VERSION ""

NS_ :

BS_:

BU_: Dummy_PHS EBOOST_OBD_PHS EOCM2cp_IMX6_PHS EOCM2cp_K1_PHS EPSb_PHS EBCM_PHS EPSa_PHS CMMb_PHS CGM3a_PHS CMMa_PHS ADIMb_PHS

BO_ 603 USDT_Req_to_CMM_PHS: 8 CGM3a_PHS
 SG_ DgnInf : 7|64@0+ (1,0) [0|1.84467440737096E+019] ""  CMMa_PHS

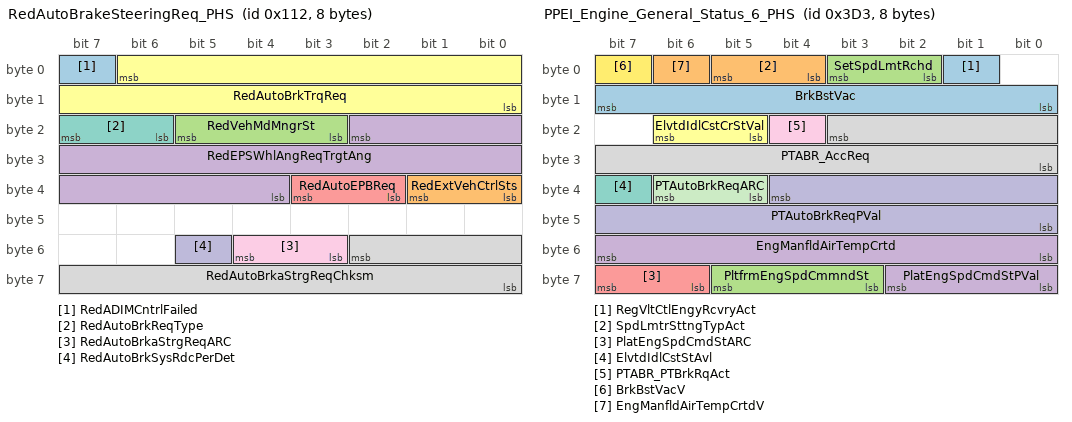
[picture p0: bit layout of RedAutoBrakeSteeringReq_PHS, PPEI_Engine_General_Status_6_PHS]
BO_ 274 RedAutoBrakeSteeringReq_PHS: 8 ADIMb_PHS
 SG_ RedADIMCntrlFailed : 7|1@0+ (1,0) [0|1] ""  EOCM2cp_K1_PHS,EPSb_PHS,EPSa_PHS,EBOOST_OBD_PHS,EBCM_PHS
 SG_ RedExtVehCtrlSts : 33|2@0+ (1,0) [0|2] ""  EBOOST_OBD_PHS,EBCM_PHS
 SG_ RedVehMdMngrSt : 21|3@0+ (1,0) [0|7] ""  EOCM2cp_K1_PHS,EPSb_PHS,EBOOST_OBD_PHS,EBCM_PHS,EPSa_PHS
 SG_ RedEPSWhlAngReqTrgtAng : 18|15@0- (0.0625,0) [-1024|1023.9375] "Deg"  EPSa_PHS,EPSb_PHS,EBOOST_OBD_PHS,EBCM_PHS
 SG_ RedAutoEPBReq : 35|2@0+ (1,0) [0|3] ""  EPSa_PHS,EPSb_PHS,EBOOST_OBD_PHS,EBCM_PHS
 SG_ RedAutoBrkTrqReq : 6|15@0+ (2,-65534) [-65534|0] "Nm"  EPSa_PHS,EPSb_PHS,EBOOST_OBD_PHS,EBCM_PHS
 SG_ RedAutoBrkReqType : 23|2@0+ (1,0) [0|3] ""  EPSa_PHS,EPSb_PHS,EBOOST_OBD_PHS,EBCM_PHS
 SG_ RedAutoBrkaStrgReqChksm : 50|11@0+ (1,0) [0|2047] ""  EPSa_PHS,EPSb_PHS,EBOOST_OBD_PHS,EBCM_PHS
 SG_ RedAutoBrkaStrgReqARC : 52|2@0+ (1,0) [0|3] ""  EPSa_PHS,EPSb_PHS,EBOOST_OBD_PHS,EBCM_PHS
 SG_ RedAutoBrkSysRdcPerDet : 53|1@0+ (1,0) [0|1] ""  EBCM_PHS,EBOOST_OBD_PHS

BO_ 598 USDT_Req_to_CMMb_PHS: 8 CGM3a_PHS
 SG_ DgnInf : 7|64@0+ (1,0) [0|1.84467440737096E+019] ""  CMMb_PHS

BO_ 1608 USDT_Resp_From_EPSb_PHS: 8 EPSb_PHS
 SG_ DgnInf : 7|64@0+ (1,0) [0|1.84467440737096E+019] ""  CGM3a_PHS

BO_ 1931 DTC_Triggered_78B_PHS: 7 EPSb_PHS
 SG_ DTCI_CodeSupported_78B : 40|1@0+ (1,0) [0|1] ""  CGM3a_PHS
 SG_ DTCI_CurrentStatus_78B : 41|1@0+ (1,0) [0|1] ""  CGM3a_PHS
 SG_ DTCI_DTCFailType_78B : 39|8@0+ (1,0) [0|255] ""  CGM3a_PHS
 SG_ DTCI_DTCFaultType_78B : 55|8@0+ (1,0) [0|255] ""  CGM3a_PHS
 SG_ DTCI_DTCNumber_78B : 23|16@0+ (1,0) [0|65535] ""  CGM3a_PHS
 SG_ DTCI_DTCSource_78B : 15|8@0+ (1,0) [0|255] ""  CGM3a_PHS
 SG_ DTCI_DTCTriggered_78B : 0|1@0+ (1,0) [0|1] ""  CGM3a_PHS
 SG_ DTCI_HistStat_78B : 44|1@0+ (1,0) [0|1] ""  CGM3a_PHS
 SG_ DTCI_TstFldCdClrdStat_78B : 43|1@0+ (1,0) [0|1] ""  CGM3a_PHS
 SG_ DTCI_TstFldPwrUpSt_78B : 46|1@0+ (1,0) [0|1] ""  CGM3a_PHS
 SG_ DTCI_TstNPsdCdClrdSt_78B : 42|1@0+ (1,0) [0|1] ""  CGM3a_PHS
 SG_ DTCI_TstNPsdPwrUpSt_78B : 45|1@0+ (1,0) [0|1] ""  CGM3a_PHS
 SG_ DTCIUnused1_78B : 7|1@0+ (1,0) [0|1] ""  CGM3a_PHS
 SG_ DTCIUnused2_78B : 6|1@0+ (1,0) [0|1] ""  CGM3a_PHS
 SG_ DTCIUnused3_78B : 5|1@0+ (1,0) [0|1] ""  CGM3a_PHS
 SG_ DTCIUnused4_78B : 4|1@0+ (1,0) [0|1] ""  CGM3a_PHS
 SG_ DTCIUnused5_78B : 3|1@0+ (1,0) [0|1] ""  CGM3a_PHS
 SG_ DTCIUnused6_78B : 2|1@0+ (1,0) [0|1] ""  CGM3a_PHS
 SG_ DTCIUnused7_78B : 1|1@0+ (1,0) [0|1] ""  CGM3a_PHS
 SG_ DTCI_WrnIndRqdSt_78B : 47|1@0+ (1,0) [0|1] ""  CGM3a_PHS

BO_ 1364 UUDT_Resp_From_EBoost_PHS: 8 EBOOST_OBD_PHS
 SG_ DgnInf_HS554 : 7|64@0+ (1,0) [0|1.84467440737096E+019] ""  CGM3a_PHS

BO_ 1359 UUDT_Resp_From_ADIMb_PHS: 8 ADIMb_PHS
 SG_ DgnInf_HS54F : 7|64@0+ (1,0) [0|1.84467440737096E+019] ""  CGM3a_PHS

BO_ 1352 UUDT_Resp_From_EPSb_PHS: 8 EPSb_PHS
 SG_ DgnInf_HS548 : 7|64@0+ (1,0) [0|1.84467440737096E+019] ""  CGM3a_PHS

BO_ 1300 VIN_Digits_2_to_9_PHS: 8 CGM3a_PHS
 SG_ VehIdNmDig2_9 : 7|64@0+ (1,0) [0|1] ""  EBCM_PHS,EBOOST_OBD_PHS,EOCM2cp_IMX6_PHS,EPSa_PHS,EOCM2cp_K1_PHS

BO_ 979 PPEI_Engine_General_Status_6_PHS: 8 CGM3a_PHS
 SG_ RegVltCtlEngyRcvryAct : 1|1@0+ (1,0) [0|1] "" Vector__XXX
 SG_ SpdLmtrSttngTypAct : 5|2@0+ (1,0) [0|3] "" Vector__XXX
 SG_ SetSpdLmtRchd : 3|2@0+ (1,0) [0|3] "" Vector__XXX
 SG_ PlatEngSpdCmdStPVal : 58|3@0+ (1,0) [0|7] "" Vector__XXX
 SG_ PlatEngSpdCmdStARC : 63|2@0+ (1,0) [0|3] "" Vector__XXX
 SG_ ElvtdIdlCstCrStVal : 22|2@0+ (1,0) [0|3] "" Vector__XXX
 SG_ ElvtdIdlCstStAvl : 39|1@0+ (1,0) [0|1] "" Vector__XXX
 SG_ PTABR_AccReq : 19|12@0- (0.01,0) [-20.48|20.47] "m/s^2"  EBCM_PHS
 SG_ PTABR_PTBrkRqAct : 20|1@0+ (1,0) [0|1] ""  EBCM_PHS
 SG_ PTAutoBrkReqPVal : 36|13@0+ (1,0) [0|8191] ""  EBCM_PHS
 SG_ PTAutoBrkReqARC : 38|2@0+ (1,0) [0|3] ""  EBCM_PHS
 SG_ BrkBstVacV : 7|1@0+ (1,0) [0|1] ""  EBCM_PHS
 SG_ BrkBstVac : 15|8@0+ (0.5,0) [0|127.5] "kPa"  EBCM_PHS
 SG_ EngManfldAirTempCrtdV : 6|1@0+ (1,0) [0|1] "" Vector__XXX
 SG_ PltfrmEngSpdCmmndSt : 61|3@0+ (1,0) [0|7] "" Vector__XXX
 SG_ EngManfldAirTempCrtd : 55|8@0+ (1,-40) [-40|215] "deg C" Vector__XXX

BO_ 1249 PPEI_VIN_Digits_10_to_17_PHS: 8 CGM3a_PHS
 SG_ VehIdNmDig10_17 : 7|64@0+ (1,0) [0|1] ""  EPSa_PHS,EBCM_PHS,EOCM2cp_K1_PHS

BO_ 1615 USDT_Resp_From_ADIMb_PHS: 8 ADIMb_PHS
 SG_ DgnInf : 7|64@0+ (1,0) [0|1.84467440737096E+019] ""  CGM3a_PHS

BO_ 562 Driving_Mode_Control_PHS: 8 EBCM_PHS
 SG_ BrkSysAutBrkStat : 52|2@0+ (1,0) [0|3] ""  Dummy_PHS
 SG_ FSRACCBrkngReqDenied : 46|1@0+ (1,0) [0|1] ""  Dummy_PHS
 SG_ BrkSysExtHldCpbltyFld : 47|1@0+ (1,0) [0|1] ""  Dummy_PHS
 SG_ SndPerfMdCsStAvl : 63|1@0+ (1,0) [0|1] ""  Dummy_PHS
 SG_ SndPerfMdCsCrStVal : 62|3@0+ (1,0) [0|7] ""  Dummy_PHS
 SG_ DispPerfMdCsStAvl : 59|1@0+ (1,0) [0|1] ""  Dummy_PHS
 SG_ DispPerfMdCsCrStVal : 58|3@0+ (1,0) [0|7] ""  Dummy_PHS
 SG_ DrvlneMntsPerfMdRq : 50|3@0+ (1,0) [0|7] ""  Dummy_PHS
 SG_ RideCntrlPerfMdRq : 18|3@0+ (1,0) [0|7] ""  Dummy_PHS
 SG_ StgSysPerfMdRq : 29|3@0+ (1,0) [0|7] ""  Dummy_PHS
 SG_ DiffPerfMdRq : 26|3@0+ (1,0) [0|7] ""  Dummy_PHS
 SG_ SndEnhcmtPerfMdRq : 13|3@0+ (1,0) [0|7] ""  Dummy_PHS
 SG_ DsplyPerfMdRq : 10|3@0+ (1,0) [0|7] ""  Dummy_PHS
 SG_ ExhstPerfMdRq : 5|3@0+ (1,0) [0|7] ""  Dummy_PHS
 SG_ HillDscntCntlSysStat : 55|3@0+ (1,0) [0|7] ""  Dummy_PHS
 SG_ SusCustStngAvlbl : 23|1@0+ (1,0) [0|1] ""  Dummy_PHS
 SG_ SusCustCurrStngVal : 45|3@0+ (1,0) [0|7] ""  Dummy_PHS
 SG_ StrCustStngAvlbl : 7|1@0+ (1,0) [0|1] ""  Dummy_PHS
 SG_ StrCustCurrStngVal : 42|3@0+ (1,0) [0|7] ""  Dummy_PHS
 SG_ DrvlnCustStngAvlbl : 6|1@0+ (1,0) [0|1] ""  Dummy_PHS
 SG_ DrvMdCntrlState : 39|8@0+ (1,0) [0|255] ""  Dummy_PHS
 SG_ AWDPerfMdRq : 2|3@0+ (1,0) [0|7] ""  Dummy_PHS
 SG_ DrvlnCustCurrStngVal : 22|3@0+ (1,0) [0|7] ""  Dummy_PHS

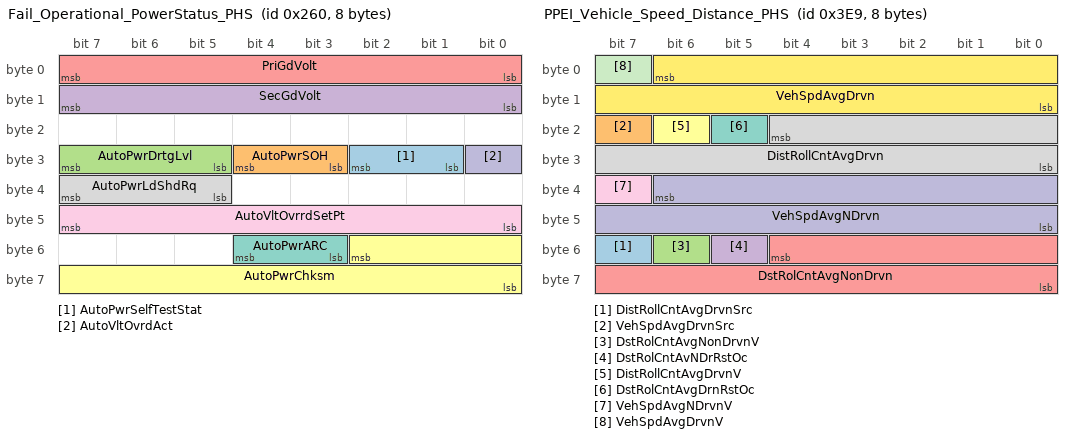
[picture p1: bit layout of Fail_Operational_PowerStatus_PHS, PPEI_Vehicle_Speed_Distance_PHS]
BO_ 608 Fail_Operational_PowerStatus_PHS: 8 CGM3a_PHS
 SG_ AutoPwrSelfTestStat : 26|2@0+ (1,0) [0|3] "" Vector__XXX
 SG_ AutoPwrSOH : 28|2@0+ (1,0) [0|3] "" Vector__XXX
 SG_ AutoPwrDrtgLvl : 31|3@0+ (1,0) [0|7] "" Vector__XXX
 SG_ SecGdVolt : 15|8@0+ (0.1,0) [0|25.5] "Volts" Vector__XXX
 SG_ PriGdVolt : 7|8@0+ (0.1,0) [0|25.5] "Volts" Vector__XXX
 SG_ AutoPwrChksm : 50|11@0+ (1,0) [0|2047] ""  EBOOST_OBD_PHS,EPSb_PHS,EBCM_PHS,EPSa_PHS
 SG_ AutoPwrARC : 52|2@0+ (1,0) [0|3] ""  EBOOST_OBD_PHS,EPSb_PHS,EBCM_PHS,EPSa_PHS
 SG_ AutoPwrLdShdRq : 39|3@0+ (1,0) [0|7] ""  EBOOST_OBD_PHS,EPSb_PHS,EBCM_PHS,EPSa_PHS
 SG_ AutoVltOvrrdSetPt : 47|8@0+ (0.1,0) [0|25.5] "V" Vector__XXX
 SG_ AutoVltOvrdAct : 24|1@0+ (1,0) [0|1] "" Vector__XXX

BO_ 1001 PPEI_Vehicle_Speed_Distance_PHS: 8 CGM3a_PHS
 SG_ DistRollCntAvgDrvnSrc : 55|1@0+ (1,0) [0|1] ""  EBOOST_OBD_PHS,EOCM2cp_IMX6_PHS,EPSb_PHS,EBCM_PHS,EPSa_PHS
 SG_ VehSpdAvgDrvnSrc : 23|1@0+ (1,0) [0|1] ""  EBOOST_OBD_PHS,EOCM2cp_IMX6_PHS,EPSa_PHS,EPSb_PHS,EBCM_PHS
 SG_ DstRolCntAvgNonDrvnV : 54|1@0+ (1,0) [0|1] ""  EBOOST_OBD_PHS,EOCM2cp_IMX6_PHS,EPSb_PHS,EPSa_PHS,EBCM_PHS
 SG_ DstRolCntAvNDrRstOc : 53|1@0+ (1,0) [0|1] ""  EBOOST_OBD_PHS,EOCM2cp_IMX6_PHS,EPSb_PHS,EPSa_PHS,EBCM_PHS
 SG_ DstRolCntAvgNonDrvn : 52|13@0+ (0.125,0) [0|1023.875] "m"  EBOOST_OBD_PHS,EOCM2cp_IMX6_PHS,EPSb_PHS,EBCM_PHS,EPSa_PHS
 SG_ DistRollCntAvgDrvnV : 22|1@0+ (1,0) [0|1] ""  EBOOST_OBD_PHS,EOCM2cp_IMX6_PHS,EPSb_PHS,EBCM_PHS,EPSa_PHS
 SG_ DstRolCntAvgDrnRstOc : 21|1@0+ (1,0) [0|1] ""  EBOOST_OBD_PHS,EOCM2cp_IMX6_PHS,EPSb_PHS,EBCM_PHS,EPSa_PHS
 SG_ DistRollCntAvgDrvn : 20|13@0+ (0.125,0) [0|1023.875] "m"  EBOOST_OBD_PHS,EOCM2cp_IMX6_PHS,EPSb_PHS,EBCM_PHS,EPSa_PHS
 SG_ VehSpdAvgNDrvnV : 39|1@0+ (1,0) [0|1] ""  CMMb_PHS,CMMa_PHS,EBOOST_OBD_PHS,EPSa_PHS,EOCM2cp_IMX6_PHS,EPSb_PHS,EBCM_PHS
 SG_ VehSpdAvgNDrvn : 38|15@0+ (0.015625,0) [0|511.984375] "km / h"  CMMb_PHS,CMMa_PHS,EBOOST_OBD_PHS,EPSa_PHS,EOCM2cp_IMX6_PHS,EPSb_PHS,EBCM_PHS
 SG_ VehSpdAvgDrvnV : 7|1@0+ (1,0) [0|1] ""  EBOOST_OBD_PHS,EPSa_PHS,EOCM2cp_IMX6_PHS,EPSb_PHS,EOCM2cp_K1_PHS,EBCM_PHS
 SG_ VehSpdAvgDrvn : 6|15@0+ (0.015625,0) [0|511.984375] "km / h"  EBOOST_OBD_PHS,EOCM2cp_IMX6_PHS,EOCM2cp_K1_PHS,EPSa_PHS,EPSb_PHS,EBCM_PHS

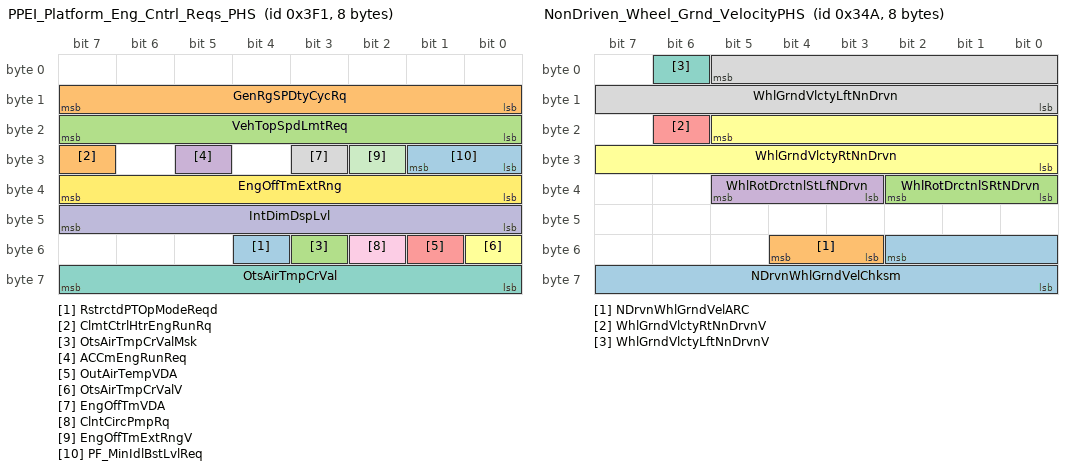
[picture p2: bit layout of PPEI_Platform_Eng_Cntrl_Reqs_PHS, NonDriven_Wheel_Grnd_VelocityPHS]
BO_ 1009 PPEI_Platform_Eng_Cntrl_Reqs_PHS: 8 CGM3a_PHS
 SG_ RstrctdPTOpModeReqd : 52|1@0+ (1,0) [0|1] "" Vector__XXX
 SG_ ClmtCtrlHtrEngRunRq : 31|1@0+ (1,0) [0|1] "" Vector__XXX
 SG_ OtsAirTmpCrValMsk : 51|1@0+ (1,0) [0|1] ""  EPSb_PHS,EPSa_PHS
 SG_ ACCmEngRunReq : 29|1@0+ (1,0) [0|1] "" Vector__XXX
 SG_ OutAirTempVDA : 49|1@0+ (1,0) [0|1] "" Vector__XXX
 SG_ OtsAirTmpCrValV : 48|1@0+ (1,0) [0|1] ""  EBCM_PHS,EPSb_PHS,EPSa_PHS
 SG_ OtsAirTmpCrVal : 63|8@0+ (0.5,-40) [-40|87.5] "deg C"  EPSb_PHS,EPSa_PHS,EBCM_PHS
 SG_ EngOffTmVDA : 27|1@0+ (1,0) [0|1] ""  EPSa_PHS,EPSb_PHS
 SG_ ClntCircPmpRq : 50|1@0+ (1,0) [0|1] "" Vector__XXX
 SG_ IntDimDspLvl : 47|8@0+ (0.392157,0) [0|100.000035] "%" Vector__XXX
 SG_ EngOffTmExtRngV : 26|1@0+ (1,0) [0|1] ""  EBCM_PHS,EPSa_PHS,EPSb_PHS
 SG_ EngOffTmExtRng : 39|8@0+ (4,0) [0|1020] "min"  EBCM_PHS,EPSa_PHS,EPSb_PHS
 SG_ PF_MinIdlBstLvlReq : 25|2@0+ (1,0) [0|3] "" Vector__XXX
 SG_ GenRgSPDtyCycRq : 15|8@0+ (0.392157,0) [0|100.000035] "%" Vector__XXX
 SG_ VehTopSpdLmtReq : 23|8@0+ (2,0) [0|510] "km / h" Vector__XXX

BO_ 201 PPEI_Engine_General_Status_1_PHS: 8 CGM3a_PHS
 SG_ Eng12vStrtrMtrCmmdOn : 53|1@0+ (1,0) [0|1] ""  EOCM2cp_K1_PHS,EOCM2cp_IMX6_PHS,EBCM_PHS,EPSb_PHS,EPSa_PHS
 SG_ EngCntrlRunCrnkTrmSt : 52|1@0+ (1,0) [0|1] ""  EOCM2cp_K1_PHS,EBOOST_OBD_PHS,EBCM_PHS,EOCM2cp_IMX6_PHS
 SG_ EngAirIntBstPrV : 51|1@0+ (1,0) [0|1] ""  EOCM2cp_K1_PHS,EBCM_PHS
 SG_ EngAirIntBstPr : 63|8@0- (1,0) [-128|127] "kPaG"  EOCM2cp_K1_PHS,EBCM_PHS
 SG_ SpdLmtrSpdWrngEnbld : 47|1@0+ (1,0) [0|1] ""  EOCM2cp_K1_PHS,EBCM_PHS
 SG_ EngCylDactEvntPndg : 54|1@0+ (1,0) [0|1] ""  EOCM2cp_K1_PHS,EBCM_PHS
 SG_ EngCylDeactMd : 43|2@0+ (1,0) [0|3] ""  EOCM2cp_K1_PHS,EBCM_PHS
 SG_ RmVhStrtEngRng : 55|1@0+ (1,0) [0|1] ""  EOCM2cp_K1_PHS,EBCM_PHS
 SG_ PFEngSpdCmndSpcd : 45|1@0+ (1,0) [0|1] ""  EOCM2cp_K1_PHS,EBCM_PHS
 SG_ DrThrtlOvrrdDetProtVal : 25|2@0+ (1,0) [0|3] ""  EOCM2cp_K1_PHS,EBCM_PHS
 SG_ DrThrtlOvrdDetAlvRlCnt : 27|2@0+ (1,0) [0|3] ""  EOCM2cp_K1_PHS,EBCM_PHS
 SG_ PltfrmEngSpdCmdInhtRq : 44|1@0+ (1,0) [0|1] ""  EOCM2cp_K1_PHS,EBCM_PHS
 SG_ PT_BrkPedDscrtInpStatV : 41|1@0+ (1,0) [0|1] ""  EOCM2cp_K1_PHS,EBCM_PHS
 SG_ PT_BrkPedDscrtInpStat : 40|1@0+ (1,0) [0|1] ""  EOCM2cp_K1_PHS,EBCM_PHS
 SG_ AccActPos : 39|8@0+ (0.392157,0) [0|100.000035] "%"  EOCM2cp_K1_PHS,EBCM_PHS
 SG_ CrsCntEnbld : 29|1@0+ (1,0) [0|1] ""  EOCM2cp_K1_PHS,EBCM_PHS
 SG_ CrsCntAtv : 30|1@0+ (1,0) [0|1] ""  EOCM2cp_K1_PHS,EBCM_PHS
 SG_ DrvThrottlOvrrdDet : 28|1@0+ (1,0) [0|1] ""  EOCM2cp_K1_PHS,EBCM_PHS
 SG_ PT_CrnkAct : 6|1@0+ (1,0) [0|1] ""  EOCM2cp_K1_PHS,EBCM_PHS,EPSb_PHS,EPSa_PHS
 SG_ PTRunAbrt : 4|1@0+ (1,0) [0|1] ""  EOCM2cp_K1_PHS,EBCM_PHS
 SG_ PTO_PT_RunAbrtd : 3|1@0+ (1,0) [0|1] ""  EOCM2cp_K1_PHS,EBCM_PHS
 SG_ PTCrnkAbrted : 5|1@0+ (1,0) [0|1] ""  EOCM2cp_K1_PHS,EBCM_PHS
 SG_ EngSpdStat : 1|2@0+ (1,0) [0|3] ""  EOCM2cp_K1_PHS,EBCM_PHS,EPSb_PHS,EPSa_PHS
 SG_ EngSpd : 15|16@0+ (0.25,0) [0|16383.75] "rpm"  EOCM2cp_K1_PHS,EBCM_PHS,EPSb_PHS,EPSa_PHS
 SG_ EngRunAtv : 7|1@0+ (1,0) [0|1] ""  EOCM2cp_K1_PHS,EBCM_PHS,EOCM2cp_IMX6_PHS,EPSb_PHS,EPSa_PHS
 SG_ EngIdlAtv : 2|1@0+ (1,0) [0|1] ""  EOCM2cp_K1_PHS,EBCM_PHS
 SG_ AccActPosV : 31|1@0+ (1,0) [0|1] ""  EOCM2cp_K1_PHS,EBCM_PHS

BO_ 842 NonDriven_Wheel_Grnd_VelocityPHS: 8 EBCM_PHS
 SG_ NDrvnWhlGrndVelChksm : 50|11@0+ (1,0) [0|2047] ""  ADIMb_PHS,EPSb_PHS,EPSa_PHS,CGM3a_PHS,EBOOST_OBD_PHS
 SG_ NDrvnWhlGrndVelARC : 52|2@0+ (1,0) [0|3] ""  ADIMb_PHS,EPSb_PHS,EPSa_PHS,CGM3a_PHS,EBOOST_OBD_PHS
 SG_ WhlRotDrctnlSRtNDrvn : 34|3@0+ (1,0) [0|7] ""  ADIMb_PHS,EBOOST_OBD_PHS,CGM3a_PHS,EPSb_PHS,EPSa_PHS
 SG_ WhlRotDrctnlStLfNDrvn : 37|3@0+ (1,0) [0|7] ""  ADIMb_PHS,EBOOST_OBD_PHS,CGM3a_PHS,EPSb_PHS,EPSa_PHS
 SG_ WhlGrndVlctyRtNnDrvnV : 22|1@0+ (1,0) [0|1] ""  ADIMb_PHS,EBOOST_OBD_PHS,EPSa_PHS,CGM3a_PHS,EPSb_PHS
 SG_ WhlGrndVlctyRtNnDrvn : 21|14@0+ (0.03125,0) [0|511.96875] "km / h"  ADIMb_PHS,EBOOST_OBD_PHS,EPSa_PHS,CGM3a_PHS,EPSb_PHS
 SG_ WhlGrndVlctyLftNnDrvnV : 6|1@0+ (1,0) [0|1] ""  ADIMb_PHS,EBOOST_OBD_PHS,EPSa_PHS,CGM3a_PHS,EPSb_PHS
 SG_ WhlGrndVlctyLftNnDrvn : 5|14@0+ (0.03125,0) [0|511.96875] "km / h"  ADIMb_PHS,EBOOST_OBD_PHS,EPSa_PHS,CGM3a_PHS,EPSb_PHS

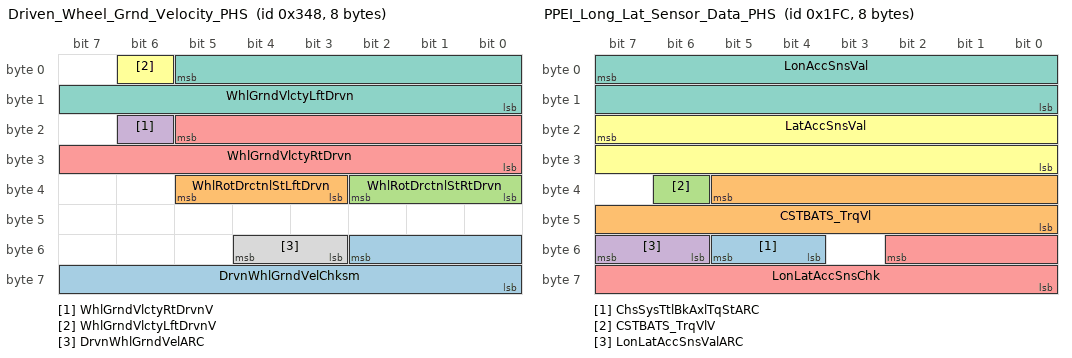
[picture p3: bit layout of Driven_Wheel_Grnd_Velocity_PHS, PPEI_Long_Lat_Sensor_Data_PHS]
BO_ 840 Driven_Wheel_Grnd_Velocity_PHS: 8 EBCM_PHS
 SG_ DrvnWhlGrndVelChksm : 50|11@0+ (1,0) [0|2047] ""  ADIMb_PHS,EPSb_PHS,EPSa_PHS,CGM3a_PHS,EBOOST_OBD_PHS
 SG_ WhlRotDrctnlStLftDrvn : 37|3@0+ (1,0) [0|7] ""  ADIMb_PHS,EBOOST_OBD_PHS,CGM3a_PHS,EPSb_PHS,EPSa_PHS
 SG_ WhlRotDrctnlStRtDrvn : 34|3@0+ (1,0) [0|7] ""  ADIMb_PHS,EBOOST_OBD_PHS,CGM3a_PHS,EPSb_PHS,EPSa_PHS
 SG_ WhlGrndVlctyRtDrvnV : 22|1@0+ (1,0) [0|1] ""  ADIMb_PHS,EBOOST_OBD_PHS,EPSa_PHS,CGM3a_PHS,EPSb_PHS
 SG_ WhlGrndVlctyRtDrvn : 21|14@0+ (0.03125,0) [0|511.96875] "km / h"  ADIMb_PHS,EBOOST_OBD_PHS,EPSa_PHS,CGM3a_PHS,EPSb_PHS
 SG_ WhlGrndVlctyLftDrvnV : 6|1@0+ (1,0) [0|1] ""  ADIMb_PHS,EBOOST_OBD_PHS,EPSa_PHS,CGM3a_PHS,EPSb_PHS
 SG_ WhlGrndVlctyLftDrvn : 5|14@0+ (0.03125,0) [0|511.96875] "km / h"  ADIMb_PHS,EBOOST_OBD_PHS,EPSa_PHS,CGM3a_PHS,EPSb_PHS
 SG_ DrvnWhlGrndVelARC : 52|2@0+ (1,0) [0|3] ""  ADIMb_PHS,EPSb_PHS,EPSa_PHS,CGM3a_PHS,EBOOST_OBD_PHS

BO_ 1912 DTC_Triggered_778_PHS: 7 EPSa_PHS
 SG_ DTCI_DTCFaultType_778 : 55|8@0+ (1,0) [0|255] ""  CGM3a_PHS
 SG_ DTCI_CodeSupported_778 : 40|1@0+ (1,0) [0|1] ""  CGM3a_PHS
 SG_ DTCI_CurrentStatus_778 : 41|1@0+ (1,0) [0|1] ""  CGM3a_PHS
 SG_ DTCI_TstNPsdCdClrdSt_778 : 42|1@0+ (1,0) [0|1] ""  CGM3a_PHS
 SG_ DTCI_TstFldCdClrdStat_778 : 43|1@0+ (1,0) [0|1] ""  CGM3a_PHS
 SG_ DTCI_HistStat_778 : 44|1@0+ (1,0) [0|1] ""  CGM3a_PHS
 SG_ DTCI_TstNPsdPwrUpSt_778 : 45|1@0+ (1,0) [0|1] ""  CGM3a_PHS
 SG_ DTCI_TstFldPwrUpSt_778 : 46|1@0+ (1,0) [0|1] ""  CGM3a_PHS
 SG_ DTCI_WrnIndRqdSt_778 : 47|1@0+ (1,0) [0|1] ""  CGM3a_PHS
 SG_ DTCI_DTCFailType_778 : 39|8@0+ (1,0) [0|255] ""  CGM3a_PHS
 SG_ DTCI_DTCNumber_778 : 23|16@0+ (1,0) [0|65535] ""  CGM3a_PHS
 SG_ DTCI_DTCSource_778 : 15|8@0+ (1,0) [0|255] ""  CGM3a_PHS
 SG_ DTCI_DTCTriggered_778 : 0|1@0+ (1,0) [0|1] ""  CGM3a_PHS
 SG_ DTCIUnused7_778 : 1|1@0+ (1,0) [0|1] ""  CGM3a_PHS
 SG_ DTCIUnused6_778 : 2|1@0+ (1,0) [0|1] ""  CGM3a_PHS
 SG_ DTCIUnused5_778 : 3|1@0+ (1,0) [0|1] ""  CGM3a_PHS
 SG_ DTCIUnused4_778 : 4|1@0+ (1,0) [0|1] ""  CGM3a_PHS
 SG_ DTCIUnused3_778 : 5|1@0+ (1,0) [0|1] ""  CGM3a_PHS
 SG_ DTCIUnused2_778 : 6|1@0+ (1,0) [0|1] ""  CGM3a_PHS
 SG_ DTCIUnused1_778 : 7|1@0+ (1,0) [0|1] ""  CGM3a_PHS

BO_ 591 USDT_Req_to_ADIMb_PHS: 8 CGM3a_PHS
 SG_ DgnInf : 7|64@0+ (1,0) [0|1.84467440737096E+019] ""  ADIMb_PHS

BO_ 1371 UUDT_Resp_From_CMM_PHS: 8 CMMa_PHS
 SG_ DgnInf_HS55B : 7|64@0+ (1,0) [0|1.84467440737096E+019] ""  CGM3a_PHS

BO_ 497 PPEI_Platform_General_Status_PHS: 8 CGM3a_PHS
 SG_ ElvtdIdlCstStReq : 33|2@0+ (1,0) [0|3] ""  EOCM2cp_K1_PHS
 SG_ FuelFltLfRstRqd : 56|1@0+ (1,0) [0|1] ""  EOCM2cp_K1_PHS
 SG_ ACCompSysVDA : 9|1@0+ (1,0) [0|1] ""  EOCM2cp_K1_PHS
 SG_ BkupPwrModeMstrVDA : 7|1@0+ (1,0) [0|1] ""  EOCM2cp_K1_PHS,EOCM2cp_IMX6_PHS,EBCM_PHS
 SG_ PrkBrkVDA : 35|1@0+ (1,0) [0|1] ""  EOCM2cp_K1_PHS
 SG_ PrkBrkVDM : 62|1@0+ (1,0) [0|1] ""  EOCM2cp_K1_PHS
 SG_ BkupPwrModeMstrVDM : 61|1@0+ (1,0) [0|1] ""  EOCM2cp_K1_PHS
 SG_ ACCompSysVDM : 60|1@0+ (1,0) [0|1] ""  EOCM2cp_K1_PHS
 SG_ AirbgVDA : 57|1@0+ (1,0) [0|1] ""  EOCM2cp_K1_PHS
 SG_ SysBkupPwrMdEn : 6|1@0+ (1,0) [0|1] ""  EBOOST_OBD_PHS,EOCM2cp_K1_PHS,EPSb_PHS,EPSa_PHS,EBCM_PHS,EOCM2cp_IMX6_PHS
 SG_ SysBkUpPwrMd : 5|2@0+ (1,0) [0|3] ""  EBOOST_OBD_PHS,EOCM2cp_K1_PHS,EPSb_PHS,EPSa_PHS,EBCM_PHS,EOCM2cp_IMX6_PHS
 SG_ SysPwrMd : 1|2@0+ (1,0) [0|3] ""  EBOOST_OBD_PHS,EOCM2cp_K1_PHS,EPSb_PHS,EPSa_PHS,EBCM_PHS,EOCM2cp_IMX6_PHS
 SG_ TrStLgMdAtv : 34|1@0+ (1,0) [0|1] ""  EOCM2cp_IMX6_PHS,EBOOST_OBD_PHS,EOCM2cp_K1_PHS,EPSb_PHS,EBCM_PHS,EPSa_PHS
 SG_ DispMeasSys : 59|1@0+ (1,0) [0|1] ""  EOCM2cp_K1_PHS
 SG_ ACCmpsrFldOn : 63|1@0+ (1,0) [0|1] ""  EOCM2cp_K1_PHS
 SG_ ACCompModReq : 12|2@0+ (1,0) [0|3] ""  EOCM2cp_K1_PHS
 SG_ ACCompNormLd : 55|8@0+ (0.1,0) [0|25.5] "l/min"  EOCM2cp_K1_PHS
 SG_ ACCompNormLdV : 10|1@0+ (1,0) [0|1] ""  EOCM2cp_K1_PHS
 SG_ PTORSMstrEngShtReq : 13|1@0+ (1,0) [0|1] ""  EOCM2cp_K1_PHS
 SG_ EngOilLfRstRq : 37|1@0+ (1,0) [0|1] ""  EOCM2cp_K1_PHS
 SG_ SIRDpl : 58|1@0+ (1,0) [0|1] ""  EOCM2cp_IMX6_PHS,EOCM2cp_K1_PHS
 SG_ PTORmStMsEngStRq : 14|1@0+ (1,0) [0|1] ""  EOCM2cp_K1_PHS
 SG_ RmVehStrRq : 15|1@0+ (1,0) [0|1] ""  EOCM2cp_K1_PHS
 SG_ ThrtlPrgrsnReq : 39|2@0+ (1,0) [0|3] ""  EOCM2cp_K1_PHS
 SG_ PrkBrkSwAtv : 36|1@0+ (1,0) [0|1] ""  EOCM2cp_K1_PHS,EBCM_PHS,EOCM2cp_IMX6_PHS
 SG_ PMMAccTrmSt : 2|1@0+ (1,0) [0|1] ""  EOCM2cp_K1_PHS
 SG_ PMMRunCrkTrmSt : 3|1@0+ (1,0) [0|1] ""  EOCM2cp_K1_PHS
 SG_ ImmblzrPreRelPswdStat : 8|1@0+ (1,0) [0|1] ""  EOCM2cp_K1_PHS
 SG_ ImmblzrPreRelPswrd : 23|16@0+ (1,0) [0|65535] "passwrd"  EOCM2cp_K1_PHS

BO_ 1908 DTC_Triggered_774: 7 EBCM_PHS
 SG_ DTCI_DTCFaultType_774 : 55|8@0+ (1,0) [0|255] ""  CGM3a_PHS
 SG_ DTCI_CodeSupported_774 : 40|1@0+ (1,0) [0|1] ""  CGM3a_PHS
 SG_ DTCI_CurrentStatus_774 : 41|1@0+ (1,0) [0|1] ""  CGM3a_PHS
 SG_ DTCI_TstNPsdCdClrdSt_774 : 42|1@0+ (1,0) [0|1] ""  CGM3a_PHS
 SG_ DTCI_TstFldCdClrdStat_774 : 43|1@0+ (1,0) [0|1] ""  CGM3a_PHS
 SG_ DTCI_HistStat_774 : 44|1@0+ (1,0) [0|1] ""  CGM3a_PHS
 SG_ DTCI_TstNPsdPwrUpSt_774 : 45|1@0+ (1,0) [0|1] ""  CGM3a_PHS
 SG_ DTCI_TstFldPwrUpSt_774 : 46|1@0+ (1,0) [0|1] ""  CGM3a_PHS
 SG_ DTCI_WrnIndRqdSt_774 : 47|1@0+ (1,0) [0|1] ""  CGM3a_PHS
 SG_ DTCI_DTCFailType_774 : 39|8@0+ (1,0) [0|255] ""  CGM3a_PHS
 SG_ DTCI_DTCNumber_774 : 23|16@0+ (1,0) [0|65535] ""  CGM3a_PHS
 SG_ DTCI_DTCSource_774 : 15|8@0+ (1,0) [0|255] ""  CGM3a_PHS
 SG_ DTCI_DTCTriggered_774 : 0|1@0+ (1,0) [0|1] ""  CGM3a_PHS
 SG_ DTCIUnused7_774 : 1|1@0+ (1,0) [0|1] ""  CGM3a_PHS
 SG_ DTCIUnused6_774 : 2|1@0+ (1,0) [0|1] ""  CGM3a_PHS
 SG_ DTCIUnused5_774 : 3|1@0+ (1,0) [0|1] ""  CGM3a_PHS
 SG_ DTCIUnused4_774 : 4|1@0+ (1,0) [0|1] ""  CGM3a_PHS
 SG_ DTCIUnused3_774 : 5|1@0+ (1,0) [0|1] ""  CGM3a_PHS
 SG_ DTCIUnused2_774 : 6|1@0+ (1,0) [0|1] ""  CGM3a_PHS
 SG_ DTCIUnused1_774 : 7|1@0+ (1,0) [0|1] ""  CGM3a_PHS

BO_ 578 USDT_Req_to_EPSa_PHS: 8 CGM3a_PHS
 SG_ DgnInf : 7|64@0+ (1,0) [0|1.84467440737096E+019] ""  EPSa_PHS

BO_ 584 USDT_Req_to_EPSb_PHS: 8 CGM3a_PHS
 SG_ DgnInf : 7|64@0+ (1,0) [0|1.84467440737096E+019] ""  EPSb_PHS

BO_ 1233 PPEI_Engine_General_Status_5_PHS: 8 CGM3a_PHS
 SG_ PTExPrtclFltWrng3IO : 63|1@0+ (1,0) [0|1] "" Vector__XXX
 SG_ PTExPartFltManRegStat : 62|3@0+ (1,0) [0|7] "" Vector__XXX
 SG_ a_12VBatSysUnstab : 30|1@0+ (1,0) [0|1] "" Vector__XXX
 SG_ EngShtdwnAct : 48|1@0+ (1,0) [0|1] "" Vector__XXX
 SG_ EngShtdwnPndgIO : 49|1@0+ (1,0) [0|1] "" Vector__XXX
 SG_ FuelFltChgNwIO : 51|1@0+ (1,0) [0|1] "" Vector__XXX
 SG_ PTExPrtclFltrWrn2IO : 50|1@0+ (1,0) [0|1] "" Vector__XXX
 SG_ PTHiElecLdReqd : 52|1@0+ (1,0) [0|1] "" Vector__XXX
 SG_ PTExPrtclFltrWrnIO : 53|1@0+ (1,0) [0|1] "" Vector__XXX
 SG_ AirCndOffIO : 0|1@0+ (1,0) [0|1] "" Vector__XXX
 SG_ DslGlwPlgIO : 55|1@0+ (1,0) [0|1] "" Vector__XXX
 SG_ RdcdPwrIO : 31|1@0+ (1,0) [0|1] "" Vector__XXX
 SG_ FuelTotCap : 27|12@0+ (0.125,0) [0|511.875] "liters" Vector__XXX
 SG_ FlLvlPctV : 28|1@0+ (1,0) [0|1] "" Vector__XXX
 SG_ FlLvlPct : 47|8@0+ (0.392157,0) [0|100.000035] "%" Vector__XXX
 SG_ EngWtrInFlIO : 54|1@0+ (1,0) [0|1] "" Vector__XXX
 SG_ EngOilTmpV : 7|1@0+ (1,0) [0|1] ""  EPSb_PHS,EPSa_PHS
 SG_ EngOilTmp : 15|8@0+ (1,-40) [-40|215] "deg C"  EPSb_PHS,EPSa_PHS
 SG_ EngOilPrsV : 6|1@0+ (1,0) [0|1] "" Vector__XXX
 SG_ EngOilPrsLwIO : 5|1@0+ (1,0) [0|1] "" Vector__XXX
 SG_ EngOilPrs : 23|8@0+ (4,0) [0|1020] "kPa" Vector__XXX
 SG_ EngOilLvlLwIO : 4|1@0+ (1,0) [0|1] "" Vector__XXX
 SG_ EngOilChngIO : 3|1@0+ (1,0) [0|1] "" Vector__XXX
 SG_ EngHt_StpEngIO : 1|1@0+ (1,0) [0|1] "" Vector__XXX
 SG_ EngHotFuelEnrchmntIO : 2|1@0+ (1,0) [0|1] "" Vector__XXX
 SG_ CkFlFilrCapIO : 29|1@0+ (1,0) [0|1] "" Vector__XXX

BO_ 257 USDT_Req_to_All_PHS_ECUs_PHS: 8 CGM3a_PHS
 SG_ DgnInf : 7|64@0+ (1,0) [0|1.84467440737096E+019] ""  CMMb_PHS,CMMa_PHS,EPSb_PHS,EOCM2cp_K1_PHS,EBOOST_OBD_PHS,EBCM_PHS,ADIMb_PHS,EPSa_PHS

BO_ 1620 USDT_Resp_From_EBoost_PHS: 8 EBOOST_OBD_PHS
 SG_ DgnInf : 7|64@0+ (1,0) [0|1.84467440737096E+019] ""  CGM3a_PHS

BO_ 596 USDT_Req_to_EBoost_PHS: 8 CGM3a_PHS
 SG_ DgnInf : 7|64@0+ (1,0) [0|1.84467440737096E+019] ""  EBOOST_OBD_PHS

BO_ 579 USDT_Req_to_EBCM_PHS: 8 CGM3a_PHS
 SG_ DgnInf : 7|64@0+ (1,0) [0|1.84467440737096E+019] ""  EBCM_PHS

BO_ 587 USDT_Req_to_EOCM2cp_K1_PHS: 8 CGM3a_PHS
 SG_ DgnInf : 7|64@0+ (1,0) [0|1.84467440737096E+019] ""  EOCM2cp_K1_PHS

BO_ 1611 USDT_Resp_From_EOCM2cp_K1_PHS: 8 EOCM2cp_K1_PHS
 SG_ DgnInf : 7|64@0+ (1,0) [0|1.84467440737096E+019] ""  CGM3a_PHS

BO_ 1355 UUDT_Resp_From_EOCM2cp_K1_PHS: 8 EOCM2cp_K1_PHS
 SG_ DgnInf_HS54B : 7|64@0+ (1,0) [0|1.84467440737096E+019] ""  CGM3a_PHS

BO_ 382 Redundant_Brake_Status_PHS: 1 EBOOST_OBD_PHS
 SG_ BrkSysBrkLtsReqdRed : 0|1@0+ (1,0) [0|1] ""  CGM3a_PHS

BO_ 508 PPEI_Long_Lat_Sensor_Data_PHS: 8 EBCM_PHS
 SG_ ChsSysTtlBkAxlTqStARC : 53|2@0+ (1,0) [0|3] ""  EOCM2cp_K1_PHS,CGM3a_PHS
 SG_ CSTBATS_TrqVl : 37|14@0+ (2,0) [0|32766] "Nm"  EOCM2cp_K1_PHS,CGM3a_PHS
 SG_ CSTBATS_TrqVlV : 38|1@0+ (1,0) [0|1] ""  EOCM2cp_K1_PHS,CGM3a_PHS
 SG_ LonLatAccSnsValARC : 55|2@0+ (1,0) [0|3] ""  EOCM2cp_K1_PHS,CGM3a_PHS
 SG_ LonLatAccSnsChk : 50|11@0+ (1,0) [0|2047] ""  EOCM2cp_K1_PHS,CGM3a_PHS
 SG_ LatAccSnsVal : 23|16@0- (0.00012207,0) [-3.99998976|3.99986769] "g's"  EOCM2cp_K1_PHS,CGM3a_PHS
 SG_ LonAccSnsVal : 7|16@0- (0.00012207,0) [-3.99998976|3.99986769] "g's"  EOCM2cp_K1_PHS,CGM3a_PHS

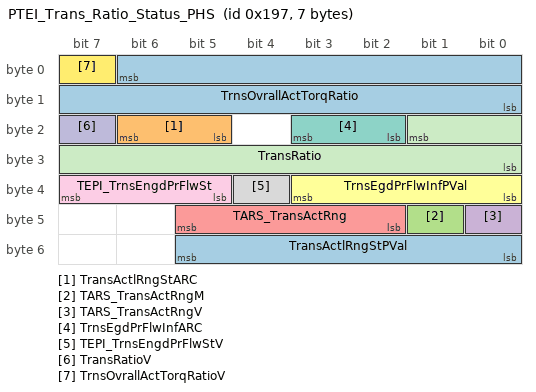
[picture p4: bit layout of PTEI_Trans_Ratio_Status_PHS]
BO_ 407 PTEI_Trans_Ratio_Status_PHS: 7 CGM3a_PHS
 SG_ TransActlRngStPVal : 53|6@0+ (1,0) [0|63] ""  EOCM2cp_K1_PHS
 SG_ TransActlRngStARC : 22|2@0+ (1,0) [0|3] ""  EOCM2cp_K1_PHS
 SG_ TARS_TransActRngM : 41|1@0+ (1,0) [0|1] ""  EOCM2cp_K1_PHS,EBOOST_OBD_PHS,EBCM_PHS
 SG_ TARS_TransActRngV : 40|1@0+ (1,0) [0|1] ""  EOCM2cp_K1_PHS,EBOOST_OBD_PHS,EBCM_PHS
 SG_ TARS_TransActRng : 45|4@0+ (1,0) [0|15] ""  EOCM2cp_K1_PHS,EBOOST_OBD_PHS,EBCM_PHS
 SG_ TrnsEgdPrFlwInfPVal : 35|4@0+ (1,0) [0|15] ""  EOCM2cp_K1_PHS
 SG_ TrnsEgdPrFlwInfARC : 19|2@0+ (1,0) [0|3] ""  EOCM2cp_K1_PHS
 SG_ TEPI_TrnsEngdPrFlwStV : 36|1@0+ (1,0) [0|1] ""  EOCM2cp_K1_PHS
 SG_ TEPI_TrnsEngdPrFlwSt : 39|3@0+ (1,0) [0|7] ""  EOCM2cp_K1_PHS
 SG_ TransRatioV : 23|1@0+ (1,0) [0|1] ""  EOCM2cp_K1_PHS
 SG_ TransRatio : 17|10@0+ (0.03125,0) [0|31.96875] ""  EOCM2cp_K1_PHS
 SG_ TrnsOvrallActTorqRatioV : 7|1@0+ (1,0) [0|1] ""  EOCM2cp_K1_PHS
 SG_ TrnsOvrallActTorqRatio : 6|15@0- (0.00390625,0) [-64|63.99609375] ""  EOCM2cp_K1_PHS

BO_ 1627 USDT_Resp_From_CMM_PHS: 8 CMMa_PHS
 SG_ DgnInf : 7|64@0+ (1,0) [0|1.84467440737096E+019] ""  CGM3a_PHS

BO_ 1603 USDT_Resp_From_EBCM_PHS: 8 EBCM_PHS
 SG_ DgnInf : 7|64@0+ (1,0) [0|1.84467440737096E+019] ""  CGM3a_PHS

BO_ 1347 UUDT_Resp_From_EBCM_PHS: 8 EBCM_PHS
 SG_ DgnInf_HS543 : 7|64@0+ (1,0) [0|1.84467440737096E+019] ""  CGM3a_PHS

BO_ 1346 UUDT_Resp_From_EPSa_PHS: 8 EPSa_PHS
 SG_ DgnInf_HS542 : 7|64@0+ (1,0) [0|1.84467440737096E+019] ""  CGM3a_PHS

BO_ 1602 USDT_Resp_From_EPSa_PHS: 8 EPSa_PHS
 SG_ DgnInf : 7|64@0+ (1,0) [0|1.84467440737096E+019] ""  CGM3a_PHS

CM_ SG_ 1931 DTCI_DTCFailType_78B "Assigned per GMW3110, Appendix E";
CM_ SG_ 1931 DTCI_DTCFaultType_78B "Based on Powertrain definition.  Not expected to be supported by all devices.";
CM_ SG_ 1931 DTCI_DTCSource_78B "This shall be equal to the Diagnostic Address of the transmittting device.";
CM_ SG_ 1300 VehIdNmDig2_9 "Desc: 8 ASCII Characters";
CM_ SG_ 979 BrkBstVac "0 kPA represents the sensor reading atmospheric pressure";
CM_ SG_ 1249 VehIdNmDig10_17 "Desc: 8 ASCII Characters";
CM_ BO_ 201 "Changed for PPEI 3.6";
CM_ SG_ 201 EngRunAtv "Indication from powertrain that the engine is running (Has RPM > 0)";
CM_ SG_ 1912 DTCI_DTCFaultType_778 "Based on Powertrain definition.  Not expected to be supported by all devices.";
CM_ SG_ 1912 DTCI_DTCFailType_778 "Assigned per GMW3110, Appendix E";
CM_ SG_ 1912 DTCI_DTCSource_778 "This shall be equal to the Diagnostic Address of the transmittting device.";
CM_ SG_ 1908 DTCI_DTCFaultType_774 "Based on Powertrain definition.  Not expected to be supported by all devices.";
CM_ SG_ 1908 DTCI_DTCFailType_774 "Assigned per GMW3110, Appendix E";
CM_ SG_ 1908 DTCI_DTCSource_774 "This shall be equal to the Diagnostic Address of the transmittting device.";
BA_DEF_ SG_  "VNSigSLHSSharedDiagnostic" ENUM  "No","Yes";
BA_DEF_ SG_  "SignalType" STRING ;
BA_DEF_ SG_  "PacketOrder" INT 0 65535;
BA_DEF_ SG_  "SignalLongName" STRING ;
BA_DEF_ SG_  "GenSigStartValue" INT 0 65535;
BA_DEF_ SG_  "VNSigAllNodes" ENUM  "No","Yes";
BA_DEF_ SG_  "GenSigSendType" ENUM  "not used","not used","not used","not used","not used","not used","not used","NoSigSendType","not used","not used","OnAnyChange","OnChangeIfActive","OnDelta";
BA_DEF_ SG_  "GenSigSendOnInit" ENUM  "Not Initialized","Application","Handler";
BA_DEF_ BO_  "AppGenMsgCycleTime" INT 0 0;
BA_DEF_ BO_  "GenMsgILSupport" ENUM  "No","Yes";
BA_DEF_ BO_  "TpApplType" STRING ;
BA_DEF_ BO_  "Prio" INT 0 7;
BA_DEF_ BO_  "MessageSubnet" ENUM  "LS","HS","CE","PE","HV","FO","LE","HE2","PHS","PCE","DLCLS","DLCHS","DLCCE","DLCFO";
BA_DEF_ BO_  "DiagState" ENUM  "No","Yes";
BA_DEF_ BO_  "GenMsgStartDelayTime" INT 0 100000;
BA_DEF_ BO_  "GenMsgDelayTime" INT 0 100000;
BA_DEF_ BO_  "GenMsgCycleTime" INT 0 100000;
BA_DEF_ BO_  "GenMsgSendType" ENUM  "cyclicX","spontanX","cyclicIfActiveX","spontanWithDelay","cyclicAndSpontanX","cyclicAndSpontanWithDelay","spontanWithRepitition","cyclicIfActiveAndSpontanWD";
BA_DEF_ BO_  "DiagResponse" ENUM  "No","Yes";
BA_DEF_ BO_  "DiagRequest" ENUM  "No","Yes";
BA_DEF_ BO_  "NmMessage" ENUM  "No","Yes";
BA_DEF_REL_ BU_SG_REL_  "GenSigSuprvRespComment" STRING ;
BA_DEF_REL_ BU_SG_REL_  "GenSigVBitResp" ENUM  "No","Yes";
BA_DEF_REL_ BU_SG_REL_  "GenSigVBitRespComment" STRING ;
BA_DEF_REL_ BU_SG_REL_  "GenSigVDAFailComment" STRING ;
BA_DEF_REL_ BU_SG_REL_  "GenSigVDAFailResp" ENUM  "No","Yes";
BA_DEF_REL_ BU_SG_REL_  "GenSigRxStartValue" STRING ;
BA_DEF_REL_ BU_SG_REL_  "GenSigSuprvResp" ENUM  "None","Notify App","Substitute Default";
BA_DEF_REL_ BU_SG_REL_  "GenSigTimeoutMsg" HEX 0 268435455;
BA_DEF_REL_ BU_SG_REL_  "GenSigTimeoutTime" INT 0 15000;
BA_DEF_DEF_  "VNSigSLHSSharedDiagnostic" "No";
BA_DEF_DEF_  "SignalType" "";
BA_DEF_DEF_  "PacketOrder" 0;
BA_DEF_DEF_  "SignalLongName" "";
BA_DEF_DEF_  "GenSigStartValue" 0;
BA_DEF_DEF_  "VNSigAllNodes" "No";
BA_DEF_DEF_  "GenSigSendType" "NoSigSendType";
BA_DEF_DEF_  "GenSigSendOnInit" "Not Initialized";
BA_DEF_DEF_  "AppGenMsgCycleTime" 0;
BA_DEF_DEF_  "GenMsgILSupport" "Yes";
BA_DEF_DEF_  "TpApplType" "";
BA_DEF_DEF_  "Prio" 4;
BA_DEF_DEF_  "MessageSubnet" "LS";
BA_DEF_DEF_  "DiagState" "No";
BA_DEF_DEF_  "GenMsgStartDelayTime" 0;
BA_DEF_DEF_  "GenMsgDelayTime" 0;
BA_DEF_DEF_  "GenMsgCycleTime" 0;
BA_DEF_DEF_  "GenMsgSendType" "spontanX";
BA_DEF_DEF_  "DiagResponse" "No";
BA_DEF_DEF_  "DiagRequest" "No";
BA_DEF_DEF_  "NmMessage" "No";
BA_DEF_DEF_REL_ "GenSigSuprvRespComment" "";
BA_DEF_DEF_REL_ "GenSigVBitResp" "No";
BA_DEF_DEF_REL_ "GenSigVBitRespComment" "";
BA_DEF_DEF_REL_ "GenSigVDAFailComment" "";
BA_DEF_DEF_REL_ "GenSigVDAFailResp" "No";
BA_DEF_DEF_REL_ "GenSigRxStartValue" "";
BA_DEF_DEF_REL_ "GenSigSuprvResp" "None";
BA_DEF_DEF_REL_ "GenSigTimeoutMsg" 0;
BA_DEF_DEF_REL_ "GenSigTimeoutTime" 0;
BA_ "Prio" BO_ 603 0;
BA_ "MessageSubnet" BO_ 603 8;
BA_ "DiagRequest" BO_ 603 1;
BA_ "Prio" BO_ 274 0;
BA_ "MessageSubnet" BO_ 274 8;
BA_ "GenMsgCycleTime" BO_ 274 10;
BA_ "GenMsgSendType" BO_ 274 0;
BA_ "Prio" BO_ 598 0;
BA_ "MessageSubnet" BO_ 598 8;
BA_ "DiagRequest" BO_ 598 1;
BA_ "Prio" BO_ 1608 0;
BA_ "MessageSubnet" BO_ 1608 8;
BA_ "DiagResponse" BO_ 1608 1;
BA_ "Prio" BO_ 1931 0;
BA_ "MessageSubnet" BO_ 1931 8;
BA_ "GenMsgCycleTime" BO_ 1931 1000;
BA_ "GenMsgSendType" BO_ 1931 0;
BA_ "GenMsgILSupport" BO_ 1364 0;
BA_ "TpApplType" BO_ 1364 "DiagUUDTResponse";
BA_ "Prio" BO_ 1364 0;
BA_ "MessageSubnet" BO_ 1364 8;
BA_ "GenMsgILSupport" BO_ 1359 0;
BA_ "TpApplType" BO_ 1359 "DiagUUDTResponse";
BA_ "Prio" BO_ 1359 0;
BA_ "MessageSubnet" BO_ 1359 8;
BA_ "GenMsgILSupport" BO_ 1352 0;
BA_ "TpApplType" BO_ 1352 "DiagUUDTResponse";
BA_ "Prio" BO_ 1352 0;
BA_ "MessageSubnet" BO_ 1352 8;
BA_ "Prio" BO_ 1300 0;
BA_ "MessageSubnet" BO_ 1300 8;
BA_ "GenMsgStartDelayTime" BO_ 1300 70;
BA_ "GenMsgCycleTime" BO_ 1300 1000;
BA_ "GenMsgSendType" BO_ 1300 0;
BA_ "Prio" BO_ 979 0;
BA_ "MessageSubnet" BO_ 979 8;
BA_ "GenMsgCycleTime" BO_ 979 100;
BA_ "GenMsgSendType" BO_ 979 0;
BA_ "Prio" BO_ 1249 0;
BA_ "MessageSubnet" BO_ 1249 8;
BA_ "GenMsgStartDelayTime" BO_ 1249 60;
BA_ "GenMsgCycleTime" BO_ 1249 1000;
BA_ "GenMsgSendType" BO_ 1249 0;
BA_ "Prio" BO_ 1615 0;
BA_ "MessageSubnet" BO_ 1615 8;
BA_ "DiagResponse" BO_ 1615 1;
BA_ "Prio" BO_ 562 0;
BA_ "MessageSubnet" BO_ 562 8;
BA_ "GenMsgCycleTime" BO_ 562 50;
BA_ "GenMsgSendType" BO_ 562 0;
BA_ "Prio" BO_ 608 0;
BA_ "MessageSubnet" BO_ 608 8;
BA_ "GenMsgDelayTime" BO_ 608 25;
BA_ "GenMsgCycleTime" BO_ 608 100;
BA_ "GenMsgSendType" BO_ 608 0;
BA_ "Prio" BO_ 1001 0;
BA_ "MessageSubnet" BO_ 1001 8;
BA_ "GenMsgCycleTime" BO_ 1001 100;
BA_ "GenMsgSendType" BO_ 1001 0;
BA_ "Prio" BO_ 1009 0;
BA_ "MessageSubnet" BO_ 1009 8;
BA_ "GenMsgStartDelayTime" BO_ 1009 10;
BA_ "GenMsgCycleTime" BO_ 1009 250;
BA_ "GenMsgSendType" BO_ 1009 0;
BA_ "Prio" BO_ 201 0;
BA_ "MessageSubnet" BO_ 201 8;
BA_ "GenMsgCycleTime" BO_ 201 12;
BA_ "GenMsgSendType" BO_ 201 0;
BA_ "Prio" BO_ 842 0;
BA_ "MessageSubnet" BO_ 842 8;
BA_ "GenMsgCycleTime" BO_ 842 50;
BA_ "GenMsgSendType" BO_ 842 0;
BA_ "Prio" BO_ 840 0;
BA_ "MessageSubnet" BO_ 840 8;
BA_ "GenMsgCycleTime" BO_ 840 50;
BA_ "GenMsgSendType" BO_ 840 0;
BA_ "Prio" BO_ 1912 0;
BA_ "MessageSubnet" BO_ 1912 8;
BA_ "GenMsgCycleTime" BO_ 1912 1000;
BA_ "GenMsgSendType" BO_ 1912 0;
BA_ "Prio" BO_ 591 0;
BA_ "MessageSubnet" BO_ 591 8;
BA_ "DiagRequest" BO_ 591 1;
BA_ "GenMsgILSupport" BO_ 1371 0;
BA_ "TpApplType" BO_ 1371 "DiagUUDTResponse";
BA_ "Prio" BO_ 1371 0;
BA_ "MessageSubnet" BO_ 1371 8;
BA_ "Prio" BO_ 497 0;
BA_ "MessageSubnet" BO_ 497 8;
BA_ "GenMsgStartDelayTime" BO_ 497 10;
BA_ "GenMsgDelayTime" BO_ 497 30;
BA_ "GenMsgCycleTime" BO_ 497 100;
BA_ "GenMsgSendType" BO_ 497 0;
BA_ "Prio" BO_ 1908 0;
BA_ "MessageSubnet" BO_ 1908 8;
BA_ "GenMsgCycleTime" BO_ 1908 1000;
BA_ "GenMsgSendType" BO_ 1908 0;
BA_ "Prio" BO_ 578 0;
BA_ "MessageSubnet" BO_ 578 8;
BA_ "DiagRequest" BO_ 578 1;
BA_ "Prio" BO_ 584 0;
BA_ "MessageSubnet" BO_ 584 8;
BA_ "DiagRequest" BO_ 584 1;
BA_ "Prio" BO_ 1233 0;
BA_ "MessageSubnet" BO_ 1233 8;
BA_ "GenMsgCycleTime" BO_ 1233 500;
BA_ "GenMsgSendType" BO_ 1233 0;
BA_ "GenMsgILSupport" BO_ 257 0;
BA_ "Prio" BO_ 257 0;
BA_ "MessageSubnet" BO_ 257 8;
BA_ "DiagState" BO_ 257 1;
BA_ "Prio" BO_ 1620 0;
BA_ "MessageSubnet" BO_ 1620 8;
BA_ "DiagResponse" BO_ 1620 1;
BA_ "Prio" BO_ 596 0;
BA_ "MessageSubnet" BO_ 596 8;
BA_ "DiagRequest" BO_ 596 1;
BA_ "Prio" BO_ 579 0;
BA_ "MessageSubnet" BO_ 579 8;
BA_ "DiagRequest" BO_ 579 1;
BA_ "GenMsgILSupport" BO_ 587 0;
BA_ "Prio" BO_ 587 0;
BA_ "MessageSubnet" BO_ 587 8;
BA_ "DiagRequest" BO_ 587 1;
BA_ "GenMsgILSupport" BO_ 1611 0;
BA_ "Prio" BO_ 1611 0;
BA_ "MessageSubnet" BO_ 1611 8;
BA_ "DiagResponse" BO_ 1611 1;
BA_ "GenMsgILSupport" BO_ 1355 0;
BA_ "TpApplType" BO_ 1355 "DiagUUDTResponse";
BA_ "Prio" BO_ 1355 0;
BA_ "MessageSubnet" BO_ 1355 8;
BA_ "MessageSubnet" BO_ 382 8;
BA_ "GenMsgCycleTime" BO_ 382 100;
BA_ "GenMsgSendType" BO_ 382 0;
BA_ "Prio" BO_ 508 0;
BA_ "MessageSubnet" BO_ 508 8;
BA_ "GenMsgCycleTime" BO_ 508 50;
BA_ "GenMsgSendType" BO_ 508 0;
BA_ "Prio" BO_ 407 0;
BA_ "MessageSubnet" BO_ 407 8;
BA_ "GenMsgCycleTime" BO_ 407 25;
BA_ "GenMsgSendType" BO_ 407 0;
BA_ "Prio" BO_ 1627 0;
BA_ "MessageSubnet" BO_ 1627 8;
BA_ "DiagResponse" BO_ 1627 1;
BA_ "Prio" BO_ 1603 0;
BA_ "MessageSubnet" BO_ 1603 8;
BA_ "DiagResponse" BO_ 1603 1;
BA_ "GenMsgILSupport" BO_ 1347 0;
BA_ "TpApplType" BO_ 1347 "DiagUUDTResponse";
BA_ "Prio" BO_ 1347 0;
BA_ "MessageSubnet" BO_ 1347 8;
BA_ "GenMsgILSupport" BO_ 1346 0;
BA_ "TpApplType" BO_ 1346 "DiagUUDTResponse";
BA_ "Prio" BO_ 1346 0;
BA_ "MessageSubnet" BO_ 1346 8;
BA_ "Prio" BO_ 1602 0;
BA_ "MessageSubnet" BO_ 1602 8;
BA_ "DiagResponse" BO_ 1602 1;
BA_ "VNSigSLHSSharedDiagnostic" SG_ 603 DgnInf 1;
BA_ "SignalType" SG_ 603 DgnInf "UNM";
BA_ "SignalLongName" SG_ 603 DgnInf "Diagnostic Information";
BA_ "VNSigAllNodes" SG_ 603 DgnInf 1;
BA_ "SignalType" SG_ 274 RedADIMCntrlFailed "BLN";
BA_ "SignalLongName" SG_ 274 RedADIMCntrlFailed "Redundant Autonomous Drive Interface Module Controller Failed";
BA_ "VNSigAllNodes" SG_ 274 RedADIMCntrlFailed 1;
BA_ "SignalType" SG_ 274 RedExtVehCtrlSts "ENM";
BA_ "SignalLongName" SG_ 274 RedExtVehCtrlSts "Redundant External Vehicle Control Status";
BA_ "VNSigAllNodes" SG_ 274 RedExtVehCtrlSts 1;
BA_ "SignalType" SG_ 274 RedVehMdMngrSt "ENM";
BA_ "SignalLongName" SG_ 274 RedVehMdMngrSt "Redundant Vehicle Mode Manager State";
BA_ "VNSigAllNodes" SG_ 274 RedVehMdMngrSt 1;
BA_ "SignalType" SG_ 274 RedEPSWhlAngReqTrgtAng "UNM";
BA_ "SignalLongName" SG_ 274 RedEPSWhlAngReqTrgtAng "Redundant Electric Power Steering Wheel Angle Request Target Angle";
BA_ "VNSigAllNodes" SG_ 274 RedEPSWhlAngReqTrgtAng 1;
BA_ "SignalType" SG_ 274 RedAutoEPBReq "ENM";
BA_ "SignalLongName" SG_ 274 RedAutoEPBReq "Redundant Autonomous Electric Park Brake Request";
BA_ "VNSigAllNodes" SG_ 274 RedAutoEPBReq 1;
BA_ "SignalType" SG_ 274 RedAutoBrkTrqReq "UNM";
BA_ "SignalLongName" SG_ 274 RedAutoBrkTrqReq "Redundant Autonomous Brake Torque Request";
BA_ "GenSigStartValue" SG_ 274 RedAutoBrkTrqReq 32767;
BA_ "VNSigAllNodes" SG_ 274 RedAutoBrkTrqReq 1;
BA_ "SignalType" SG_ 274 RedAutoBrkReqType "ENM";
BA_ "SignalLongName" SG_ 274 RedAutoBrkReqType "Redundant Autonomous Brake Request Type";
BA_ "VNSigAllNodes" SG_ 274 RedAutoBrkReqType 1;
BA_ "SignalType" SG_ 274 RedAutoBrkaStrgReqChksm "UNM";
BA_ "SignalLongName" SG_ 274 RedAutoBrkaStrgReqChksm "Redundant Autonomous Brake and Steering Request Checksum";
BA_ "VNSigAllNodes" SG_ 274 RedAutoBrkaStrgReqChksm 1;
BA_ "SignalType" SG_ 274 RedAutoBrkaStrgReqARC "UNM";
BA_ "SignalLongName" SG_ 274 RedAutoBrkaStrgReqARC "Redundant Autonomous Brake and Steering Request Alive Rolling Count";
BA_ "VNSigAllNodes" SG_ 274 RedAutoBrkaStrgReqARC 1;
BA_ "SignalType" SG_ 274 RedAutoBrkSysRdcPerDet "BLN";
BA_ "SignalLongName" SG_ 274 RedAutoBrkSysRdcPerDet "Redundant Brake System Reduced Performance Detected";
BA_ "VNSigAllNodes" SG_ 274 RedAutoBrkSysRdcPerDet 1;
BA_ "VNSigSLHSSharedDiagnostic" SG_ 598 DgnInf 1;
BA_ "SignalType" SG_ 598 DgnInf "UNM";
BA_ "SignalLongName" SG_ 598 DgnInf "Diagnostic Information";
BA_ "VNSigAllNodes" SG_ 598 DgnInf 1;
BA_ "VNSigSLHSSharedDiagnostic" SG_ 1608 DgnInf 1;
BA_ "SignalType" SG_ 1608 DgnInf "UNM";
BA_ "SignalLongName" SG_ 1608 DgnInf "Diagnostic Information";
BA_ "VNSigAllNodes" SG_ 1608 DgnInf 1;
BA_ "SignalType" SG_ 1931 DTCI_CodeSupported_78B "BLN";
BA_ "PacketOrder" SG_ 1931 DTCI_CodeSupported_78B 19;
BA_ "SignalLongName" SG_ 1931 DTCI_CodeSupported_78B "Diagnostic Trouble Code Information Extended 78B : Code Supported";
BA_ "VNSigAllNodes" SG_ 1931 DTCI_CodeSupported_78B 1;
BA_ "SignalType" SG_ 1931 DTCI_CurrentStatus_78B "BLN";
BA_ "PacketOrder" SG_ 1931 DTCI_CurrentStatus_78B 18;
BA_ "SignalLongName" SG_ 1931 DTCI_CurrentStatus_78B "Diagnostic Trouble Code Information Extended 78B : Current Status";
BA_ "VNSigAllNodes" SG_ 1931 DTCI_CurrentStatus_78B 1;
BA_ "SignalType" SG_ 1931 DTCI_DTCFailType_78B "UNM";
BA_ "PacketOrder" SG_ 1931 DTCI_DTCFailType_78B 11;
BA_ "SignalLongName" SG_ 1931 DTCI_DTCFailType_78B "Diagnostic Trouble Code Information Extended 78B : Diagnostic Trouble Code Failure Type";
BA_ "VNSigAllNodes" SG_ 1931 DTCI_DTCFailType_78B 1;
BA_ "SignalType" SG_ 1931 DTCI_DTCFaultType_78B "ENM";
BA_ "PacketOrder" SG_ 1931 DTCI_DTCFaultType_78B 20;
BA_ "SignalLongName" SG_ 1931 DTCI_DTCFaultType_78B "Diagnostic Trouble Code Information Extended 78B : Diagnostic Trouble Code Fault Type";
BA_ "VNSigAllNodes" SG_ 1931 DTCI_DTCFaultType_78B 1;
BA_ "SignalType" SG_ 1931 DTCI_DTCNumber_78B "UNM";
BA_ "PacketOrder" SG_ 1931 DTCI_DTCNumber_78B 10;
BA_ "SignalLongName" SG_ 1931 DTCI_DTCNumber_78B "Diagnostic Trouble Code Information Extended 78B : Diagnostic Trouble Code Number";
BA_ "VNSigAllNodes" SG_ 1931 DTCI_DTCNumber_78B 1;
BA_ "SignalType" SG_ 1931 DTCI_DTCSource_78B "UNM";
BA_ "PacketOrder" SG_ 1931 DTCI_DTCSource_78B 9;
BA_ "SignalLongName" SG_ 1931 DTCI_DTCSource_78B "Diagnostic Trouble Code Information Extended 78B : Diagnostic Trouble Code Source";
BA_ "VNSigAllNodes" SG_ 1931 DTCI_DTCSource_78B 1;
BA_ "SignalType" SG_ 1931 DTCI_DTCTriggered_78B "BLN";
BA_ "PacketOrder" SG_ 1931 DTCI_DTCTriggered_78B 8;
BA_ "SignalLongName" SG_ 1931 DTCI_DTCTriggered_78B "Diagnostic Trouble Code Information Extended 78B : Diagnostic Trouble Code Triggered";
BA_ "VNSigAllNodes" SG_ 1931 DTCI_DTCTriggered_78B 1;
BA_ "SignalType" SG_ 1931 DTCI_HistStat_78B "BLN";
BA_ "PacketOrder" SG_ 1931 DTCI_HistStat_78B 15;
BA_ "SignalLongName" SG_ 1931 DTCI_HistStat_78B "Diagnostic Trouble Code Information Extended 78B : History Status";
BA_ "VNSigAllNodes" SG_ 1931 DTCI_HistStat_78B 1;
BA_ "SignalType" SG_ 1931 DTCI_TstFldCdClrdStat_78B "BLN";
BA_ "PacketOrder" SG_ 1931 DTCI_TstFldCdClrdStat_78B 16;
BA_ "SignalLongName" SG_ 1931 DTCI_TstFldCdClrdStat_78B "Diagnostic Trouble Code Information Extended 78B : Test Failed Since Code Cleared Status";
BA_ "VNSigAllNodes" SG_ 1931 DTCI_TstFldCdClrdStat_78B 1;
BA_ "SignalType" SG_ 1931 DTCI_TstFldPwrUpSt_78B "BLN";
BA_ "PacketOrder" SG_ 1931 DTCI_TstFldPwrUpSt_78B 13;
BA_ "SignalLongName" SG_ 1931 DTCI_TstFldPwrUpSt_78B "Diagnostic Trouble Code Information Extended 78B : Test Failed Since Power Up Status";
BA_ "VNSigAllNodes" SG_ 1931 DTCI_TstFldPwrUpSt_78B 1;
BA_ "SignalType" SG_ 1931 DTCI_TstNPsdCdClrdSt_78B "BLN";
BA_ "PacketOrder" SG_ 1931 DTCI_TstNPsdCdClrdSt_78B 17;
BA_ "SignalLongName" SG_ 1931 DTCI_TstNPsdCdClrdSt_78B "Diagnostic Trouble Code Information Extended 78B : Test Not Passed Since Code Cleared Status";
BA_ "VNSigAllNodes" SG_ 1931 DTCI_TstNPsdCdClrdSt_78B 1;
BA_ "SignalType" SG_ 1931 DTCI_TstNPsdPwrUpSt_78B "BLN";
BA_ "PacketOrder" SG_ 1931 DTCI_TstNPsdPwrUpSt_78B 14;
BA_ "SignalLongName" SG_ 1931 DTCI_TstNPsdPwrUpSt_78B "Diagnostic Trouble Code Information Extended 78B : Test Not Passed Since Power Up Status";
BA_ "VNSigAllNodes" SG_ 1931 DTCI_TstNPsdPwrUpSt_78B 1;
BA_ "SignalType" SG_ 1931 DTCIUnused1_78B "BLN";
BA_ "PacketOrder" SG_ 1931 DTCIUnused1_78B 1;
BA_ "SignalLongName" SG_ 1931 DTCIUnused1_78B "Diagnostic Trouble Code Information Extended 78B : Unused 1";
BA_ "VNSigAllNodes" SG_ 1931 DTCIUnused1_78B 1;
BA_ "SignalType" SG_ 1931 DTCIUnused2_78B "BLN";
BA_ "PacketOrder" SG_ 1931 DTCIUnused2_78B 2;
BA_ "SignalLongName" SG_ 1931 DTCIUnused2_78B "Diagnostic Trouble Code Information Extended 78B : Unused 2";
BA_ "VNSigAllNodes" SG_ 1931 DTCIUnused2_78B 1;
BA_ "SignalType" SG_ 1931 DTCIUnused3_78B "BLN";
BA_ "PacketOrder" SG_ 1931 DTCIUnused3_78B 3;
BA_ "SignalLongName" SG_ 1931 DTCIUnused3_78B "Diagnostic Trouble Code Information Extended 78B : Unused 3";
BA_ "VNSigAllNodes" SG_ 1931 DTCIUnused3_78B 1;
BA_ "SignalType" SG_ 1931 DTCIUnused4_78B "BLN";
BA_ "PacketOrder" SG_ 1931 DTCIUnused4_78B 4;
BA_ "SignalLongName" SG_ 1931 DTCIUnused4_78B "Diagnostic Trouble Code Information Extended 78B : Unused 4";
BA_ "VNSigAllNodes" SG_ 1931 DTCIUnused4_78B 1;
BA_ "SignalType" SG_ 1931 DTCIUnused5_78B "BLN";
BA_ "PacketOrder" SG_ 1931 DTCIUnused5_78B 5;
BA_ "SignalLongName" SG_ 1931 DTCIUnused5_78B "Diagnostic Trouble Code Information Extended 78B : Unused 5";
BA_ "VNSigAllNodes" SG_ 1931 DTCIUnused5_78B 1;
BA_ "SignalType" SG_ 1931 DTCIUnused6_78B "BLN";
BA_ "PacketOrder" SG_ 1931 DTCIUnused6_78B 6;
BA_ "SignalLongName" SG_ 1931 DTCIUnused6_78B "Diagnostic Trouble Code Information Extended 78B : Unused 6";
BA_ "VNSigAllNodes" SG_ 1931 DTCIUnused6_78B 1;
BA_ "SignalType" SG_ 1931 DTCIUnused7_78B "BLN";
BA_ "PacketOrder" SG_ 1931 DTCIUnused7_78B 7;
BA_ "SignalLongName" SG_ 1931 DTCIUnused7_78B "Diagnostic Trouble Code Information Extended 78B : Unused 7";
BA_ "VNSigAllNodes" SG_ 1931 DTCIUnused7_78B 1;
BA_ "SignalType" SG_ 1931 DTCI_WrnIndRqdSt_78B "BLN";
BA_ "PacketOrder" SG_ 1931 DTCI_WrnIndRqdSt_78B 12;
BA_ "SignalLongName" SG_ 1931 DTCI_WrnIndRqdSt_78B "Diagnostic Trouble Code Information Extended 78B : Warning Indicator Requested Status";
BA_ "VNSigAllNodes" SG_ 1931 DTCI_WrnIndRqdSt_78B 1;
BA_ "VNSigSLHSSharedDiagnostic" SG_ 1364 DgnInf_HS554 1;
BA_ "SignalType" SG_ 1364 DgnInf_HS554 "UNM";
BA_ "SignalLongName" SG_ 1364 DgnInf_HS554 "Diagnostic Information HS554";
BA_ "VNSigAllNodes" SG_ 1364 DgnInf_HS554 1;
BA_ "VNSigSLHSSharedDiagnostic" SG_ 1359 DgnInf_HS54F 1;
BA_ "SignalType" SG_ 1359 DgnInf_HS54F "UNM";
BA_ "SignalLongName" SG_ 1359 DgnInf_HS54F "Diagnostic Information HS54F";
BA_ "VNSigAllNodes" SG_ 1359 DgnInf_HS54F 1;
BA_ "VNSigSLHSSharedDiagnostic" SG_ 1352 DgnInf_HS548 1;
BA_ "SignalType" SG_ 1352 DgnInf_HS548 "UNM";
BA_ "SignalLongName" SG_ 1352 DgnInf_HS548 "Diagnostic Information HS548";
BA_ "VNSigAllNodes" SG_ 1352 DgnInf_HS548 1;
BA_ "SignalType" SG_ 1300 VehIdNmDig2_9 "ASC";
BA_ "SignalLongName" SG_ 1300 VehIdNmDig2_9 "Vehicle Identification Number Digits 2-9";
BA_ "VNSigAllNodes" SG_ 1300 VehIdNmDig2_9 1;
BA_ "SignalType" SG_ 979 RegVltCtlEngyRcvryAct "BLN";
BA_ "SignalLongName" SG_ 979 RegVltCtlEngyRcvryAct "Regulated Voltage Control Energy Recovery Active";
BA_ "VNSigAllNodes" SG_ 979 RegVltCtlEngyRcvryAct 1;
BA_ "SignalType" SG_ 979 SpdLmtrSttngTypAct "ENM";
BA_ "SignalLongName" SG_ 979 SpdLmtrSttngTypAct "Speed Limiter Setting Type Active";
BA_ "VNSigAllNodes" SG_ 979 SpdLmtrSttngTypAct 1;
BA_ "SignalType" SG_ 979 SetSpdLmtRchd "ENM";
BA_ "SignalLongName" SG_ 979 SetSpdLmtRchd "Set Speed Limit Reached";
BA_ "VNSigAllNodes" SG_ 979 SetSpdLmtRchd 1;
BA_ "SignalType" SG_ 979 PlatEngSpdCmdStPVal "UNM";
BA_ "SignalLongName" SG_ 979 PlatEngSpdCmdStPVal "Platform Engine Speed Command Status Protection Value";
BA_ "VNSigAllNodes" SG_ 979 PlatEngSpdCmdStPVal 1;
BA_ "SignalType" SG_ 979 PlatEngSpdCmdStARC "UNM";
BA_ "SignalLongName" SG_ 979 PlatEngSpdCmdStARC "Platform Engine Speed Command Status Alive Rolling Count";
BA_ "VNSigAllNodes" SG_ 979 PlatEngSpdCmdStARC 1;
BA_ "SignalType" SG_ 979 ElvtdIdlCstCrStVal "ENM";
BA_ "SignalLongName" SG_ 979 ElvtdIdlCstCrStVal "Elevated Idle Customization Current Setting Value";
BA_ "VNSigAllNodes" SG_ 979 ElvtdIdlCstCrStVal 1;
BA_ "SignalType" SG_ 979 ElvtdIdlCstStAvl "BLN";
BA_ "SignalLongName" SG_ 979 ElvtdIdlCstStAvl "Elevated Idle Customization Setting Available";
BA_ "VNSigAllNodes" SG_ 979 ElvtdIdlCstStAvl 1;
BA_ "SignalType" SG_ 979 PTABR_AccReq "SNM";
BA_ "PacketOrder" SG_ 979 PTABR_AccReq 2;
BA_ "SignalLongName" SG_ 979 PTABR_AccReq "Powertrain Automatic Braking Request : Acceleration Request";
BA_ "VNSigAllNodes" SG_ 979 PTABR_AccReq 1;
BA_ "SignalType" SG_ 979 PTABR_PTBrkRqAct "BLN";
BA_ "PacketOrder" SG_ 979 PTABR_PTBrkRqAct 1;
BA_ "SignalLongName" SG_ 979 PTABR_PTBrkRqAct "Powertrain Automatic Braking Request : Powertrain Brake Request Active";
BA_ "VNSigAllNodes" SG_ 979 PTABR_PTBrkRqAct 1;
BA_ "SignalType" SG_ 979 PTAutoBrkReqPVal "UNM";
BA_ "SignalLongName" SG_ 979 PTAutoBrkReqPVal "Powertrain Automatic Braking Request Protection Value";
BA_ "VNSigAllNodes" SG_ 979 PTAutoBrkReqPVal 1;
BA_ "SignalType" SG_ 979 PTAutoBrkReqARC "UNM";
BA_ "SignalLongName" SG_ 979 PTAutoBrkReqARC "Powertrain Automatic Braking Request Alive Rolling Count";
BA_ "VNSigAllNodes" SG_ 979 PTAutoBrkReqARC 1;
BA_ "SignalType" SG_ 979 BrkBstVacV "ENM";
BA_ "SignalLongName" SG_ 979 BrkBstVacV "Brake Boost Vacuum Validity";
BA_ "VNSigAllNodes" SG_ 979 BrkBstVacV 1;
BA_ "SignalType" SG_ 979 BrkBstVac "UNM";
BA_ "SignalLongName" SG_ 979 BrkBstVac "Brake Boost Vacuum";
BA_ "VNSigAllNodes" SG_ 979 BrkBstVac 1;
BA_ "SignalType" SG_ 979 EngManfldAirTempCrtdV "ENM";
BA_ "SignalLongName" SG_ 979 EngManfldAirTempCrtdV "Engine Manifold Air Temperature Corrected Validity";
BA_ "VNSigAllNodes" SG_ 979 EngManfldAirTempCrtdV 1;
BA_ "SignalType" SG_ 979 PltfrmEngSpdCmmndSt "ENM";
BA_ "SignalLongName" SG_ 979 PltfrmEngSpdCmmndSt "Platform Engine Speed Command Status";
BA_ "VNSigAllNodes" SG_ 979 PltfrmEngSpdCmmndSt 1;
BA_ "SignalType" SG_ 979 EngManfldAirTempCrtd "UNM";
BA_ "SignalLongName" SG_ 979 EngManfldAirTempCrtd "Engine Manifold Air Temperature Corrected";
BA_ "VNSigAllNodes" SG_ 979 EngManfldAirTempCrtd 1;
BA_ "SignalType" SG_ 1249 VehIdNmDig10_17 "ASC";
BA_ "SignalLongName" SG_ 1249 VehIdNmDig10_17 "Vehicle Identification Number Digits 10-17";
BA_ "VNSigAllNodes" SG_ 1249 VehIdNmDig10_17 1;
BA_ "VNSigSLHSSharedDiagnostic" SG_ 1615 DgnInf 1;
BA_ "SignalType" SG_ 1615 DgnInf "UNM";
BA_ "SignalLongName" SG_ 1615 DgnInf "Diagnostic Information";
BA_ "VNSigAllNodes" SG_ 1615 DgnInf 1;
BA_ "SignalType" SG_ 562 BrkSysAutBrkStat "ENM";
BA_ "SignalLongName" SG_ 562 BrkSysAutBrkStat "Brake System Automatic Braking Status";
BA_ "VNSigAllNodes" SG_ 562 BrkSysAutBrkStat 1;
BA_ "SignalType" SG_ 562 FSRACCBrkngReqDenied "BLN";
BA_ "SignalLongName" SG_ 562 FSRACCBrkngReqDenied "Full Speed Range Adaptive Cruise Control Braking Request Denied";
BA_ "VNSigAllNodes" SG_ 562 FSRACCBrkngReqDenied 1;
BA_ "SignalType" SG_ 562 BrkSysExtHldCpbltyFld "BLN";
BA_ "SignalLongName" SG_ 562 BrkSysExtHldCpbltyFld "Brake System Extended Hold Capability Failed";
BA_ "VNSigAllNodes" SG_ 562 BrkSysExtHldCpbltyFld 1;
BA_ "SignalType" SG_ 562 SndPerfMdCsStAvl "BLN";
BA_ "SignalLongName" SG_ 562 SndPerfMdCsStAvl "Sound Performance Mode Customization Setting Available";
BA_ "VNSigAllNodes" SG_ 562 SndPerfMdCsStAvl 1;
BA_ "SignalType" SG_ 562 SndPerfMdCsCrStVal "ENM";
BA_ "SignalLongName" SG_ 562 SndPerfMdCsCrStVal "Sound Performance Mode Customization Current Setting Value";
BA_ "VNSigAllNodes" SG_ 562 SndPerfMdCsCrStVal 1;
BA_ "SignalType" SG_ 562 DispPerfMdCsStAvl "BLN";
BA_ "SignalLongName" SG_ 562 DispPerfMdCsStAvl "Display Performance Mode Customization Setting Available";
BA_ "VNSigAllNodes" SG_ 562 DispPerfMdCsStAvl 1;
BA_ "SignalType" SG_ 562 DispPerfMdCsCrStVal "ENM";
BA_ "SignalLongName" SG_ 562 DispPerfMdCsCrStVal "Display Performance Mode Customization Current Setting Value";
BA_ "VNSigAllNodes" SG_ 562 DispPerfMdCsCrStVal 1;
BA_ "SignalType" SG_ 562 DrvlneMntsPerfMdRq "ENM";
BA_ "SignalLongName" SG_ 562 DrvlneMntsPerfMdRq "Driveline Mounts Performance Mode Request";
BA_ "VNSigAllNodes" SG_ 562 DrvlneMntsPerfMdRq 1;
BA_ "SignalType" SG_ 562 RideCntrlPerfMdRq "ENM";
BA_ "SignalLongName" SG_ 562 RideCntrlPerfMdRq "Ride Control Performance Mode Request";
BA_ "VNSigAllNodes" SG_ 562 RideCntrlPerfMdRq 1;
BA_ "SignalType" SG_ 562 StgSysPerfMdRq "ENM";
BA_ "SignalLongName" SG_ 562 StgSysPerfMdRq "Steering System Performance Mode Request";
BA_ "VNSigAllNodes" SG_ 562 StgSysPerfMdRq 1;
BA_ "SignalType" SG_ 562 DiffPerfMdRq "ENM";
BA_ "SignalLongName" SG_ 562 DiffPerfMdRq "Differential Performance Mode Request";
BA_ "VNSigAllNodes" SG_ 562 DiffPerfMdRq 1;
BA_ "SignalType" SG_ 562 SndEnhcmtPerfMdRq "ENM";
BA_ "SignalLongName" SG_ 562 SndEnhcmtPerfMdRq "Sound Enhancement Performance Mode Request";
BA_ "VNSigAllNodes" SG_ 562 SndEnhcmtPerfMdRq 1;
BA_ "SignalType" SG_ 562 DsplyPerfMdRq "ENM";
BA_ "SignalLongName" SG_ 562 DsplyPerfMdRq "Display Performance Mode Request";
BA_ "VNSigAllNodes" SG_ 562 DsplyPerfMdRq 1;
BA_ "SignalType" SG_ 562 ExhstPerfMdRq "ENM";
BA_ "SignalLongName" SG_ 562 ExhstPerfMdRq "Exhaust Performance Mode Request";
BA_ "VNSigAllNodes" SG_ 562 ExhstPerfMdRq 1;
BA_ "SignalType" SG_ 562 HillDscntCntlSysStat "ENM";
BA_ "SignalLongName" SG_ 562 HillDscntCntlSysStat "Hill Descent Control System Status";
BA_ "VNSigAllNodes" SG_ 562 HillDscntCntlSysStat 1;
BA_ "SignalType" SG_ 562 SusCustStngAvlbl "BLN";
BA_ "SignalLongName" SG_ 562 SusCustStngAvlbl "Suspension Customization Setting Available";
BA_ "VNSigAllNodes" SG_ 562 SusCustStngAvlbl 1;
BA_ "SignalType" SG_ 562 SusCustCurrStngVal "ENM";
BA_ "SignalLongName" SG_ 562 SusCustCurrStngVal "Suspension Customization Current Setting Value";
BA_ "VNSigAllNodes" SG_ 562 SusCustCurrStngVal 1;
BA_ "SignalType" SG_ 562 StrCustStngAvlbl "BLN";
BA_ "SignalLongName" SG_ 562 StrCustStngAvlbl "Steering Customization Setting Available";
BA_ "VNSigAllNodes" SG_ 562 StrCustStngAvlbl 1;
BA_ "SignalType" SG_ 562 StrCustCurrStngVal "ENM";
BA_ "SignalLongName" SG_ 562 StrCustCurrStngVal "Steering Customization Current Setting Value";
BA_ "VNSigAllNodes" SG_ 562 StrCustCurrStngVal 1;
BA_ "SignalType" SG_ 562 DrvlnCustStngAvlbl "BLN";
BA_ "SignalLongName" SG_ 562 DrvlnCustStngAvlbl "Driveline Customization Setting Available";
BA_ "VNSigAllNodes" SG_ 562 DrvlnCustStngAvlbl 1;
BA_ "SignalType" SG_ 562 DrvMdCntrlState "UNM";
BA_ "SignalLongName" SG_ 562 DrvMdCntrlState "Driving Mode Control State";
BA_ "VNSigAllNodes" SG_ 562 DrvMdCntrlState 1;
BA_ "SignalType" SG_ 562 AWDPerfMdRq "ENM";
BA_ "SignalLongName" SG_ 562 AWDPerfMdRq "AWD Performance Mode Request";
BA_ "VNSigAllNodes" SG_ 562 AWDPerfMdRq 1;
BA_ "SignalType" SG_ 562 DrvlnCustCurrStngVal "ENM";
BA_ "SignalLongName" SG_ 562 DrvlnCustCurrStngVal "Driveline Customization Current Setting Value";
BA_ "VNSigAllNodes" SG_ 562 DrvlnCustCurrStngVal 1;
BA_ "SignalType" SG_ 608 AutoPwrSelfTestStat "ENM";
BA_ "SignalLongName" SG_ 608 AutoPwrSelfTestStat "Autonomous Power Self Test Status";
BA_ "VNSigAllNodes" SG_ 608 AutoPwrSelfTestStat 1;
BA_ "GenSigSendType" SG_ 608 AutoPwrSOH 10;
BA_ "SignalType" SG_ 608 AutoPwrSOH "ENM";
BA_ "SignalLongName" SG_ 608 AutoPwrSOH "Autonomous Power State of Health";
BA_ "VNSigAllNodes" SG_ 608 AutoPwrSOH 1;
BA_ "GenSigSendType" SG_ 608 AutoPwrDrtgLvl 10;
BA_ "SignalType" SG_ 608 AutoPwrDrtgLvl "ENM";
BA_ "SignalLongName" SG_ 608 AutoPwrDrtgLvl "Autonomous Power Derating Level";
BA_ "VNSigAllNodes" SG_ 608 AutoPwrDrtgLvl 1;
BA_ "SignalType" SG_ 608 SecGdVolt "UNM";
BA_ "SignalLongName" SG_ 608 SecGdVolt "Secondary Grid Voltage";
BA_ "VNSigAllNodes" SG_ 608 SecGdVolt 1;
BA_ "SignalType" SG_ 608 PriGdVolt "UNM";
BA_ "SignalLongName" SG_ 608 PriGdVolt "Primary Grid Voltage";
BA_ "VNSigAllNodes" SG_ 608 PriGdVolt 1;
BA_ "SignalType" SG_ 608 AutoPwrChksm "UNM";
BA_ "SignalLongName" SG_ 608 AutoPwrChksm "Autonomous Power Checksum";
BA_ "VNSigAllNodes" SG_ 608 AutoPwrChksm 1;
BA_ "SignalType" SG_ 608 AutoPwrARC "UNM";
BA_ "SignalLongName" SG_ 608 AutoPwrARC "Autonomous Power Alive Rolling Count";
BA_ "VNSigAllNodes" SG_ 608 AutoPwrARC 1;
BA_ "GenSigSendType" SG_ 608 AutoPwrLdShdRq 10;
BA_ "SignalType" SG_ 608 AutoPwrLdShdRq "ENM";
BA_ "SignalLongName" SG_ 608 AutoPwrLdShdRq "Autonomous Power Load Shedding Request";
BA_ "VNSigAllNodes" SG_ 608 AutoPwrLdShdRq 1;
BA_ "SignalType" SG_ 608 AutoVltOvrrdSetPt "UNM";
BA_ "SignalLongName" SG_ 608 AutoVltOvrrdSetPt "Autonomous Voltage Override Set Point";
BA_ "VNSigAllNodes" SG_ 608 AutoVltOvrrdSetPt 1;
BA_ "GenSigSendType" SG_ 608 AutoVltOvrdAct 10;
BA_ "SignalType" SG_ 608 AutoVltOvrdAct "BLN";
BA_ "SignalLongName" SG_ 608 AutoVltOvrdAct "Autonomous Voltage Override Active";
BA_ "VNSigAllNodes" SG_ 608 AutoVltOvrdAct 1;
BA_ "SignalType" SG_ 1001 DistRollCntAvgDrvnSrc "ENM";
BA_ "SignalLongName" SG_ 1001 DistRollCntAvgDrvnSrc "Distance Rolling Count Average Driven Source";
BA_ "VNSigAllNodes" SG_ 1001 DistRollCntAvgDrvnSrc 1;
BA_ "SignalType" SG_ 1001 VehSpdAvgDrvnSrc "ENM";
BA_ "SignalLongName" SG_ 1001 VehSpdAvgDrvnSrc "Vehicle Speed Average Driven Source";
BA_ "VNSigAllNodes" SG_ 1001 VehSpdAvgDrvnSrc 1;
BA_ "SignalType" SG_ 1001 DstRolCntAvgNonDrvnV "ENM";
BA_ "SignalLongName" SG_ 1001 DstRolCntAvgNonDrvnV "Distance Rolling Count Average Non Driven Validity";
BA_ "VNSigAllNodes" SG_ 1001 DstRolCntAvgNonDrvnV 1;
BA_ "SignalType" SG_ 1001 DstRolCntAvNDrRstOc "BLN";
BA_ "SignalLongName" SG_ 1001 DstRolCntAvNDrRstOc "Distance Rolling Count Average Non Driven Reset Occurred";
BA_ "VNSigAllNodes" SG_ 1001 DstRolCntAvNDrRstOc 1;
BA_ "SignalType" SG_ 1001 DstRolCntAvgNonDrvn "UNM";
BA_ "SignalLongName" SG_ 1001 DstRolCntAvgNonDrvn "Distance Rolling Count Average Non Driven";
BA_ "VNSigAllNodes" SG_ 1001 DstRolCntAvgNonDrvn 1;
BA_ "SignalType" SG_ 1001 DistRollCntAvgDrvnV "ENM";
BA_ "SignalLongName" SG_ 1001 DistRollCntAvgDrvnV "Distance Rolling Count Average Driven Validity";
BA_ "VNSigAllNodes" SG_ 1001 DistRollCntAvgDrvnV 1;
BA_ "SignalType" SG_ 1001 DstRolCntAvgDrnRstOc "BLN";
BA_ "SignalLongName" SG_ 1001 DstRolCntAvgDrnRstOc "Distance Rolling Count Average Driven Reset Occurred";
BA_ "VNSigAllNodes" SG_ 1001 DstRolCntAvgDrnRstOc 1;
BA_ "SignalType" SG_ 1001 DistRollCntAvgDrvn "UNM";
BA_ "SignalLongName" SG_ 1001 DistRollCntAvgDrvn "Distance Rolling Count Average Driven";
BA_ "VNSigAllNodes" SG_ 1001 DistRollCntAvgDrvn 1;
BA_ "SignalType" SG_ 1001 VehSpdAvgNDrvnV "ENM";
BA_ "SignalLongName" SG_ 1001 VehSpdAvgNDrvnV "Vehicle Speed Average Non Driven Validity";
BA_ "VNSigAllNodes" SG_ 1001 VehSpdAvgNDrvnV 1;
BA_ "SignalType" SG_ 1001 VehSpdAvgNDrvn "UNM";
BA_ "SignalLongName" SG_ 1001 VehSpdAvgNDrvn "Vehicle Speed Average Non Driven";
BA_ "VNSigAllNodes" SG_ 1001 VehSpdAvgNDrvn 1;
BA_ "SignalType" SG_ 1001 VehSpdAvgDrvnV "ENM";
BA_ "SignalLongName" SG_ 1001 VehSpdAvgDrvnV "Vehicle Speed Average Driven Validity";
BA_ "VNSigAllNodes" SG_ 1001 VehSpdAvgDrvnV 1;
BA_ "SignalType" SG_ 1001 VehSpdAvgDrvn "UNM";
BA_ "SignalLongName" SG_ 1001 VehSpdAvgDrvn "Vehicle Speed Average Driven";
BA_ "VNSigAllNodes" SG_ 1001 VehSpdAvgDrvn 1;
BA_ "SignalType" SG_ 1009 RstrctdPTOpModeReqd "BLN";
BA_ "SignalLongName" SG_ 1009 RstrctdPTOpModeReqd "Restricted Powertrain Operation Mode Requested";
BA_ "VNSigAllNodes" SG_ 1009 RstrctdPTOpModeReqd 1;
BA_ "SignalType" SG_ 1009 ClmtCtrlHtrEngRunRq "ENM";
BA_ "SignalLongName" SG_ 1009 ClmtCtrlHtrEngRunRq "Climate Control Heater Engine Run Request";
BA_ "VNSigAllNodes" SG_ 1009 ClmtCtrlHtrEngRunRq 1;
BA_ "SignalType" SG_ 1009 OtsAirTmpCrValMsk "ENM";
BA_ "SignalLongName" SG_ 1009 OtsAirTmpCrValMsk "Outside Air Temperature Corrected Value Mask";
BA_ "VNSigAllNodes" SG_ 1009 OtsAirTmpCrValMsk 1;
BA_ "SignalType" SG_ 1009 ACCmEngRunReq "ENM";
BA_ "SignalLongName" SG_ 1009 ACCmEngRunReq "Air Conditioning Compressor Engine Run Request";
BA_ "VNSigAllNodes" SG_ 1009 ACCmEngRunReq 1;
BA_ "SignalType" SG_ 1009 OutAirTempVDA "ENM";
BA_ "SignalLongName" SG_ 1009 OutAirTempVDA "Outside Air Temperature Virtual Device Availability";
BA_ "GenSigStartValue" SG_ 1009 OutAirTempVDA 1;
BA_ "VNSigAllNodes" SG_ 1009 OutAirTempVDA 1;
BA_ "SignalType" SG_ 1009 OtsAirTmpCrValV "ENM";
BA_ "SignalLongName" SG_ 1009 OtsAirTmpCrValV "Outside Air Temperature Corrected Value Validity";
BA_ "VNSigAllNodes" SG_ 1009 OtsAirTmpCrValV 1;
BA_ "SignalType" SG_ 1009 OtsAirTmpCrVal "UNM";
BA_ "SignalLongName" SG_ 1009 OtsAirTmpCrVal "Outside Air Temperature Corrected Value";
BA_ "VNSigAllNodes" SG_ 1009 OtsAirTmpCrVal 1;
BA_ "SignalType" SG_ 1009 EngOffTmVDA "ENM";
BA_ "SignalLongName" SG_ 1009 EngOffTmVDA "Engine Off Time Virtual Device Availability";
BA_ "GenSigStartValue" SG_ 1009 EngOffTmVDA 1;
BA_ "VNSigAllNodes" SG_ 1009 EngOffTmVDA 1;
BA_ "SignalType" SG_ 1009 ClntCircPmpRq "ENM";
BA_ "SignalLongName" SG_ 1009 ClntCircPmpRq "Coolant Circulation Pump Request";
BA_ "VNSigAllNodes" SG_ 1009 ClntCircPmpRq 1;
BA_ "SignalType" SG_ 1009 IntDimDspLvl "UNM";
BA_ "SignalLongName" SG_ 1009 IntDimDspLvl "Interior Dimming Display Level";
BA_ "VNSigAllNodes" SG_ 1009 IntDimDspLvl 1;
BA_ "SignalType" SG_ 1009 EngOffTmExtRngV "ENM";
BA_ "SignalLongName" SG_ 1009 EngOffTmExtRngV "Engine Off Time Extended Range Validity";
BA_ "VNSigAllNodes" SG_ 1009 EngOffTmExtRngV 1;
BA_ "SignalType" SG_ 1009 EngOffTmExtRng "UNM";
BA_ "SignalLongName" SG_ 1009 EngOffTmExtRng "Engine Off Time Extended Range";
BA_ "VNSigAllNodes" SG_ 1009 EngOffTmExtRng 1;
BA_ "SignalType" SG_ 1009 PF_MinIdlBstLvlReq "ENM";
BA_ "SignalLongName" SG_ 1009 PF_MinIdlBstLvlReq "Platform Minimum Idle Boost Level Request";
BA_ "VNSigAllNodes" SG_ 1009 PF_MinIdlBstLvlReq 1;
BA_ "SignalType" SG_ 1009 GenRgSPDtyCycRq "UNM";
BA_ "SignalLongName" SG_ 1009 GenRgSPDtyCycRq "Generator Regulator Setpoint Duty Cycle Request";
BA_ "VNSigAllNodes" SG_ 1009 GenRgSPDtyCycRq 1;
BA_ "SignalType" SG_ 1009 VehTopSpdLmtReq "UNM";
BA_ "SignalLongName" SG_ 1009 VehTopSpdLmtReq "Vehicle Top Speed Limit Request";
BA_ "VNSigAllNodes" SG_ 1009 VehTopSpdLmtReq 1;
BA_ "SignalType" SG_ 201 Eng12vStrtrMtrCmmdOn "BLN";
BA_ "SignalLongName" SG_ 201 Eng12vStrtrMtrCmmdOn "Engine 12 Volt Starter Motor Commanded On";
BA_ "VNSigAllNodes" SG_ 201 Eng12vStrtrMtrCmmdOn 1;
BA_ "SignalType" SG_ 201 EngCntrlRunCrnkTrmSt "ENM";
BA_ "SignalLongName" SG_ 201 EngCntrlRunCrnkTrmSt "Engine Controller Run Crank Terminal Status";
BA_ "VNSigAllNodes" SG_ 201 EngCntrlRunCrnkTrmSt 1;
BA_ "SignalType" SG_ 201 EngAirIntBstPrV "ENM";
BA_ "SignalLongName" SG_ 201 EngAirIntBstPrV "Engine Intake Air Boost Pressure Validity";
BA_ "VNSigAllNodes" SG_ 201 EngAirIntBstPrV 1;
BA_ "SignalType" SG_ 201 EngAirIntBstPr "SNM";
BA_ "SignalLongName" SG_ 201 EngAirIntBstPr "Engine Intake Air Boost Pressure";
BA_ "VNSigAllNodes" SG_ 201 EngAirIntBstPr 1;
BA_ "SignalType" SG_ 201 SpdLmtrSpdWrngEnbld "BLN";
BA_ "SignalLongName" SG_ 201 SpdLmtrSpdWrngEnbld "Speed Limiter/Speed Warning Enabled";
BA_ "VNSigAllNodes" SG_ 201 SpdLmtrSpdWrngEnbld 1;
BA_ "SignalType" SG_ 201 EngCylDactEvntPndg "BLN";
BA_ "SignalLongName" SG_ 201 EngCylDactEvntPndg "Engine Cylinder Deactivation Event Pending";
BA_ "VNSigAllNodes" SG_ 201 EngCylDactEvntPndg 1;
BA_ "SignalType" SG_ 201 EngCylDeactMd "ENM";
BA_ "SignalLongName" SG_ 201 EngCylDeactMd "Engine Cylinder Deactivation Mode";
BA_ "VNSigAllNodes" SG_ 201 EngCylDeactMd 1;
BA_ "SignalType" SG_ 201 RmVhStrtEngRng "BLN";
BA_ "SignalLongName" SG_ 201 RmVhStrtEngRng "Remote Vehicle Start Engine Running";
BA_ "VNSigAllNodes" SG_ 201 RmVhStrtEngRng 1;
BA_ "SignalType" SG_ 201 PFEngSpdCmndSpcd "BLN";
BA_ "SignalLongName" SG_ 201 PFEngSpdCmndSpcd "Platform Engine Speed Command Superceded";
BA_ "VNSigAllNodes" SG_ 201 PFEngSpdCmndSpcd 1;
BA_ "SignalType" SG_ 201 DrThrtlOvrrdDetProtVal "UNM";
BA_ "SignalLongName" SG_ 201 DrThrtlOvrrdDetProtVal "Driver Throttle Override Detected Protection Value";
BA_ "VNSigAllNodes" SG_ 201 DrThrtlOvrrdDetProtVal 1;
BA_ "SignalType" SG_ 201 DrThrtlOvrdDetAlvRlCnt "UNM";
BA_ "SignalLongName" SG_ 201 DrThrtlOvrdDetAlvRlCnt "Driver Throttle Override Detection Alive Rolling Count";
BA_ "VNSigAllNodes" SG_ 201 DrThrtlOvrdDetAlvRlCnt 1;
BA_ "SignalType" SG_ 201 PltfrmEngSpdCmdInhtRq "ENM";
BA_ "SignalLongName" SG_ 201 PltfrmEngSpdCmdInhtRq "Platform Engine Speed Command Inhibit Request";
BA_ "VNSigAllNodes" SG_ 201 PltfrmEngSpdCmdInhtRq 1;
BA_ "SignalType" SG_ 201 PT_BrkPedDscrtInpStatV "ENM";
BA_ "SignalLongName" SG_ 201 PT_BrkPedDscrtInpStatV "Powertrain Brake Pedal Discrete Input Status Validity";
BA_ "VNSigAllNodes" SG_ 201 PT_BrkPedDscrtInpStatV 1;
BA_ "SignalType" SG_ 201 PT_BrkPedDscrtInpStat "ENM";
BA_ "SignalLongName" SG_ 201 PT_BrkPedDscrtInpStat "Powertrain Brake Pedal Discrete Input Status";
BA_ "VNSigAllNodes" SG_ 201 PT_BrkPedDscrtInpStat 1;
BA_ "SignalType" SG_ 201 AccActPos "UNM";
BA_ "SignalLongName" SG_ 201 AccActPos "Accelerator Actual Position";
BA_ "VNSigAllNodes" SG_ 201 AccActPos 1;
BA_ "SignalType" SG_ 201 CrsCntEnbld "BLN";
BA_ "SignalLongName" SG_ 201 CrsCntEnbld "Cruise Control Enabled";
BA_ "VNSigAllNodes" SG_ 201 CrsCntEnbld 1;
BA_ "SignalType" SG_ 201 CrsCntAtv "BLN";
BA_ "SignalLongName" SG_ 201 CrsCntAtv "Cruise Control Active";
BA_ "VNSigAllNodes" SG_ 201 CrsCntAtv 1;
BA_ "SignalType" SG_ 201 DrvThrottlOvrrdDet "BLN";
BA_ "SignalLongName" SG_ 201 DrvThrottlOvrrdDet "Driver Throttle Override Detected";
BA_ "VNSigAllNodes" SG_ 201 DrvThrottlOvrrdDet 1;
BA_ "SignalType" SG_ 201 PT_CrnkAct "BLN";
BA_ "SignalLongName" SG_ 201 PT_CrnkAct "Powertrain Crank Active";
BA_ "VNSigAllNodes" SG_ 201 PT_CrnkAct 1;
BA_ "SignalType" SG_ 201 PTRunAbrt "BLN";
BA_ "SignalLongName" SG_ 201 PTRunAbrt "Powertrain Run Aborted";
BA_ "VNSigAllNodes" SG_ 201 PTRunAbrt 1;
BA_ "SignalType" SG_ 201 PTO_PT_RunAbrtd "BLN";
BA_ "SignalLongName" SG_ 201 PTO_PT_RunAbrtd "Power Take Off Powertrain Run Aborted";
BA_ "VNSigAllNodes" SG_ 201 PTO_PT_RunAbrtd 1;
BA_ "SignalType" SG_ 201 PTCrnkAbrted "BLN";
BA_ "SignalLongName" SG_ 201 PTCrnkAbrted "Powertrain Crank Aborted";
BA_ "VNSigAllNodes" SG_ 201 PTCrnkAbrted 1;
BA_ "SignalType" SG_ 201 EngSpdStat "ENM";
BA_ "SignalLongName" SG_ 201 EngSpdStat "Engine Speed Status";
BA_ "VNSigAllNodes" SG_ 201 EngSpdStat 1;
BA_ "SignalType" SG_ 201 EngSpd "UNM";
BA_ "SignalLongName" SG_ 201 EngSpd "Engine Speed";
BA_ "VNSigAllNodes" SG_ 201 EngSpd 1;
BA_ "SignalType" SG_ 201 EngRunAtv "BLN";
BA_ "SignalLongName" SG_ 201 EngRunAtv "Engine Run Active";
BA_ "VNSigAllNodes" SG_ 201 EngRunAtv 1;
BA_ "SignalType" SG_ 201 EngIdlAtv "BLN";
BA_ "SignalLongName" SG_ 201 EngIdlAtv "Engine Idle Active";
BA_ "VNSigAllNodes" SG_ 201 EngIdlAtv 1;
BA_ "SignalType" SG_ 201 AccActPosV "ENM";
BA_ "SignalLongName" SG_ 201 AccActPosV "Accelerator Actual Position Validity";
BA_ "VNSigAllNodes" SG_ 201 AccActPosV 1;
BA_ "SignalType" SG_ 842 NDrvnWhlGrndVelChksm "UNM";
BA_ "SignalLongName" SG_ 842 NDrvnWhlGrndVelChksm "Non Driven Wheel Ground Velocity Checksum";
BA_ "VNSigAllNodes" SG_ 842 NDrvnWhlGrndVelChksm 1;
BA_ "SignalType" SG_ 842 NDrvnWhlGrndVelARC "UNM";
BA_ "SignalLongName" SG_ 842 NDrvnWhlGrndVelARC "Non Driven Wheel Ground Velocity Alive Rolling Count";
BA_ "VNSigAllNodes" SG_ 842 NDrvnWhlGrndVelARC 1;
BA_ "SignalType" SG_ 842 WhlRotDrctnlSRtNDrvn "ENM";
BA_ "SignalLongName" SG_ 842 WhlRotDrctnlSRtNDrvn "Wheel Rotational Directional Status Right Non Driven";
BA_ "VNSigAllNodes" SG_ 842 WhlRotDrctnlSRtNDrvn 1;
BA_ "SignalType" SG_ 842 WhlRotDrctnlStLfNDrvn "ENM";
BA_ "SignalLongName" SG_ 842 WhlRotDrctnlStLfNDrvn "Wheel Rotational Directional Status Left Non Driven";
BA_ "VNSigAllNodes" SG_ 842 WhlRotDrctnlStLfNDrvn 1;
BA_ "SignalType" SG_ 842 WhlGrndVlctyRtNnDrvnV "ENM";
BA_ "SignalLongName" SG_ 842 WhlGrndVlctyRtNnDrvnV "Wheel Ground Velocity Right Non Driven Validity";
BA_ "VNSigAllNodes" SG_ 842 WhlGrndVlctyRtNnDrvnV 1;
BA_ "SignalType" SG_ 842 WhlGrndVlctyRtNnDrvn "UNM";
BA_ "SignalLongName" SG_ 842 WhlGrndVlctyRtNnDrvn "Wheel Ground Velocity Right Non Driven";
BA_ "VNSigAllNodes" SG_ 842 WhlGrndVlctyRtNnDrvn 1;
BA_ "SignalType" SG_ 842 WhlGrndVlctyLftNnDrvnV "ENM";
BA_ "SignalLongName" SG_ 842 WhlGrndVlctyLftNnDrvnV "Wheel Ground Velocity Left Non Driven Validity";
BA_ "VNSigAllNodes" SG_ 842 WhlGrndVlctyLftNnDrvnV 1;
BA_ "SignalType" SG_ 842 WhlGrndVlctyLftNnDrvn "UNM";
BA_ "SignalLongName" SG_ 842 WhlGrndVlctyLftNnDrvn "Wheel Ground Velocity Left Non Driven";
BA_ "VNSigAllNodes" SG_ 842 WhlGrndVlctyLftNnDrvn 1;
BA_ "SignalType" SG_ 840 DrvnWhlGrndVelChksm "UNM";
BA_ "SignalLongName" SG_ 840 DrvnWhlGrndVelChksm "Driven Wheel Ground Velocity Checksum";
BA_ "VNSigAllNodes" SG_ 840 DrvnWhlGrndVelChksm 1;
BA_ "SignalType" SG_ 840 WhlRotDrctnlStLftDrvn "ENM";
BA_ "SignalLongName" SG_ 840 WhlRotDrctnlStLftDrvn "Wheel Rotational Directional Status Left Driven";
BA_ "VNSigAllNodes" SG_ 840 WhlRotDrctnlStLftDrvn 1;
BA_ "SignalType" SG_ 840 WhlRotDrctnlStRtDrvn "ENM";
BA_ "SignalLongName" SG_ 840 WhlRotDrctnlStRtDrvn "Wheel Rotational Directional Status Right Driven";
BA_ "VNSigAllNodes" SG_ 840 WhlRotDrctnlStRtDrvn 1;
BA_ "SignalType" SG_ 840 WhlGrndVlctyRtDrvnV "ENM";
BA_ "SignalLongName" SG_ 840 WhlGrndVlctyRtDrvnV "Wheel Ground Velocity Right Driven Validity";
BA_ "VNSigAllNodes" SG_ 840 WhlGrndVlctyRtDrvnV 1;
BA_ "SignalType" SG_ 840 WhlGrndVlctyRtDrvn "UNM";
BA_ "SignalLongName" SG_ 840 WhlGrndVlctyRtDrvn "Wheel Ground Velocity Right Driven";
BA_ "VNSigAllNodes" SG_ 840 WhlGrndVlctyRtDrvn 1;
BA_ "SignalType" SG_ 840 WhlGrndVlctyLftDrvnV "ENM";
BA_ "SignalLongName" SG_ 840 WhlGrndVlctyLftDrvnV "Wheel Ground Velocity Left Driven Validity";
BA_ "VNSigAllNodes" SG_ 840 WhlGrndVlctyLftDrvnV 1;
BA_ "SignalType" SG_ 840 WhlGrndVlctyLftDrvn "UNM";
BA_ "SignalLongName" SG_ 840 WhlGrndVlctyLftDrvn "Wheel Ground Velocity Left Driven";
BA_ "VNSigAllNodes" SG_ 840 WhlGrndVlctyLftDrvn 1;
BA_ "SignalType" SG_ 840 DrvnWhlGrndVelARC "UNM";
BA_ "SignalLongName" SG_ 840 DrvnWhlGrndVelARC "Driven Wheel Ground Velocity Alive Rolling Count";
BA_ "VNSigAllNodes" SG_ 840 DrvnWhlGrndVelARC 1;
BA_ "SignalType" SG_ 1912 DTCI_DTCFaultType_778 "ENM";
BA_ "PacketOrder" SG_ 1912 DTCI_DTCFaultType_778 20;
BA_ "SignalLongName" SG_ 1912 DTCI_DTCFaultType_778 "Diagnostic Trouble Code Information Extended 778 : Diagnostic Trouble Code Fault Type";
BA_ "VNSigAllNodes" SG_ 1912 DTCI_DTCFaultType_778 1;
BA_ "SignalType" SG_ 1912 DTCI_CodeSupported_778 "BLN";
BA_ "PacketOrder" SG_ 1912 DTCI_CodeSupported_778 19;
BA_ "SignalLongName" SG_ 1912 DTCI_CodeSupported_778 "Diagnostic Trouble Code Information Extended 778 : Code Supported";
BA_ "VNSigAllNodes" SG_ 1912 DTCI_CodeSupported_778 1;
BA_ "SignalType" SG_ 1912 DTCI_CurrentStatus_778 "BLN";
BA_ "PacketOrder" SG_ 1912 DTCI_CurrentStatus_778 18;
BA_ "SignalLongName" SG_ 1912 DTCI_CurrentStatus_778 "Diagnostic Trouble Code Information Extended 778 : Current Status";
BA_ "VNSigAllNodes" SG_ 1912 DTCI_CurrentStatus_778 1;
BA_ "SignalType" SG_ 1912 DTCI_TstNPsdCdClrdSt_778 "BLN";
BA_ "PacketOrder" SG_ 1912 DTCI_TstNPsdCdClrdSt_778 17;
BA_ "SignalLongName" SG_ 1912 DTCI_TstNPsdCdClrdSt_778 "Diagnostic Trouble Code Information Extended 778 : Test Not Passed Since Code Cleared Status";
BA_ "VNSigAllNodes" SG_ 1912 DTCI_TstNPsdCdClrdSt_778 1;
BA_ "SignalType" SG_ 1912 DTCI_TstFldCdClrdStat_778 "BLN";
BA_ "PacketOrder" SG_ 1912 DTCI_TstFldCdClrdStat_778 16;
BA_ "SignalLongName" SG_ 1912 DTCI_TstFldCdClrdStat_778 "Diagnostic Trouble Code Information Extended 778 : Test Failed Since Code Cleared Status";
BA_ "VNSigAllNodes" SG_ 1912 DTCI_TstFldCdClrdStat_778 1;
BA_ "SignalType" SG_ 1912 DTCI_HistStat_778 "BLN";
BA_ "PacketOrder" SG_ 1912 DTCI_HistStat_778 15;
BA_ "SignalLongName" SG_ 1912 DTCI_HistStat_778 "Diagnostic Trouble Code Information Extended 778 : History Status";
BA_ "VNSigAllNodes" SG_ 1912 DTCI_HistStat_778 1;
BA_ "SignalType" SG_ 1912 DTCI_TstNPsdPwrUpSt_778 "BLN";
BA_ "PacketOrder" SG_ 1912 DTCI_TstNPsdPwrUpSt_778 14;
BA_ "SignalLongName" SG_ 1912 DTCI_TstNPsdPwrUpSt_778 "Diagnostic Trouble Code Information Extended 778 : Test Not Passed Since Power Up Status";
BA_ "VNSigAllNodes" SG_ 1912 DTCI_TstNPsdPwrUpSt_778 1;
BA_ "SignalType" SG_ 1912 DTCI_TstFldPwrUpSt_778 "BLN";
BA_ "PacketOrder" SG_ 1912 DTCI_TstFldPwrUpSt_778 13;
BA_ "SignalLongName" SG_ 1912 DTCI_TstFldPwrUpSt_778 "Diagnostic Trouble Code Information Extended 778 : Test Failed Since Power Up Status";
BA_ "VNSigAllNodes" SG_ 1912 DTCI_TstFldPwrUpSt_778 1;
BA_ "SignalType" SG_ 1912 DTCI_WrnIndRqdSt_778 "BLN";
BA_ "PacketOrder" SG_ 1912 DTCI_WrnIndRqdSt_778 12;
BA_ "SignalLongName" SG_ 1912 DTCI_WrnIndRqdSt_778 "Diagnostic Trouble Code Information Extended 778 : Warning Indicator Requested Status";
BA_ "VNSigAllNodes" SG_ 1912 DTCI_WrnIndRqdSt_778 1;
BA_ "SignalType" SG_ 1912 DTCI_DTCFailType_778 "UNM";
BA_ "PacketOrder" SG_ 1912 DTCI_DTCFailType_778 11;
BA_ "SignalLongName" SG_ 1912 DTCI_DTCFailType_778 "Diagnostic Trouble Code Information Extended 778 : Diagnostic Trouble Code Failure Type";
BA_ "VNSigAllNodes" SG_ 1912 DTCI_DTCFailType_778 1;
BA_ "SignalType" SG_ 1912 DTCI_DTCNumber_778 "UNM";
BA_ "PacketOrder" SG_ 1912 DTCI_DTCNumber_778 10;
BA_ "SignalLongName" SG_ 1912 DTCI_DTCNumber_778 "Diagnostic Trouble Code Information Extended 778 : Diagnostic Trouble Code Number";
BA_ "VNSigAllNodes" SG_ 1912 DTCI_DTCNumber_778 1;
BA_ "SignalType" SG_ 1912 DTCI_DTCSource_778 "UNM";
BA_ "PacketOrder" SG_ 1912 DTCI_DTCSource_778 9;
BA_ "SignalLongName" SG_ 1912 DTCI_DTCSource_778 "Diagnostic Trouble Code Information Extended 778 : Diagnostic Trouble Code Source";
BA_ "VNSigAllNodes" SG_ 1912 DTCI_DTCSource_778 1;
BA_ "SignalType" SG_ 1912 DTCI_DTCTriggered_778 "BLN";
BA_ "PacketOrder" SG_ 1912 DTCI_DTCTriggered_778 8;
BA_ "SignalLongName" SG_ 1912 DTCI_DTCTriggered_778 "Diagnostic Trouble Code Information Extended 778 : Diagnostic Trouble Code Triggered";
BA_ "VNSigAllNodes" SG_ 1912 DTCI_DTCTriggered_778 1;
BA_ "SignalType" SG_ 1912 DTCIUnused7_778 "BLN";
BA_ "PacketOrder" SG_ 1912 DTCIUnused7_778 7;
BA_ "SignalLongName" SG_ 1912 DTCIUnused7_778 "Diagnostic Trouble Code Information Extended 778 : Unused 7";
BA_ "VNSigAllNodes" SG_ 1912 DTCIUnused7_778 1;
BA_ "SignalType" SG_ 1912 DTCIUnused6_778 "BLN";
BA_ "PacketOrder" SG_ 1912 DTCIUnused6_778 6;
BA_ "SignalLongName" SG_ 1912 DTCIUnused6_778 "Diagnostic Trouble Code Information Extended 778 : Unused 6";
BA_ "VNSigAllNodes" SG_ 1912 DTCIUnused6_778 1;
BA_ "SignalType" SG_ 1912 DTCIUnused5_778 "BLN";
BA_ "PacketOrder" SG_ 1912 DTCIUnused5_778 5;
BA_ "SignalLongName" SG_ 1912 DTCIUnused5_778 "Diagnostic Trouble Code Information Extended 778 : Unused 5";
BA_ "VNSigAllNodes" SG_ 1912 DTCIUnused5_778 1;
BA_ "SignalType" SG_ 1912 DTCIUnused4_778 "BLN";
BA_ "PacketOrder" SG_ 1912 DTCIUnused4_778 4;
BA_ "SignalLongName" SG_ 1912 DTCIUnused4_778 "Diagnostic Trouble Code Information Extended 778 : Unused 4";
BA_ "VNSigAllNodes" SG_ 1912 DTCIUnused4_778 1;
BA_ "SignalType" SG_ 1912 DTCIUnused3_778 "BLN";
BA_ "PacketOrder" SG_ 1912 DTCIUnused3_778 3;
BA_ "SignalLongName" SG_ 1912 DTCIUnused3_778 "Diagnostic Trouble Code Information Extended 778 : Unused 3";
BA_ "VNSigAllNodes" SG_ 1912 DTCIUnused3_778 1;
BA_ "SignalType" SG_ 1912 DTCIUnused2_778 "BLN";
BA_ "PacketOrder" SG_ 1912 DTCIUnused2_778 2;
BA_ "SignalLongName" SG_ 1912 DTCIUnused2_778 "Diagnostic Trouble Code Information Extended 778 : Unused 2";
BA_ "VNSigAllNodes" SG_ 1912 DTCIUnused2_778 1;
BA_ "SignalType" SG_ 1912 DTCIUnused1_778 "BLN";
BA_ "PacketOrder" SG_ 1912 DTCIUnused1_778 1;
BA_ "SignalLongName" SG_ 1912 DTCIUnused1_778 "Diagnostic Trouble Code Information Extended 778 : Unused 1";
BA_ "VNSigAllNodes" SG_ 1912 DTCIUnused1_778 1;
BA_ "VNSigSLHSSharedDiagnostic" SG_ 591 DgnInf 1;
BA_ "SignalType" SG_ 591 DgnInf "UNM";
BA_ "SignalLongName" SG_ 591 DgnInf "Diagnostic Information";
BA_ "VNSigAllNodes" SG_ 591 DgnInf 1;
BA_ "VNSigSLHSSharedDiagnostic" SG_ 1371 DgnInf_HS55B 1;
BA_ "SignalType" SG_ 1371 DgnInf_HS55B "UNM";
BA_ "SignalLongName" SG_ 1371 DgnInf_HS55B "Diagnostic Information HS55B";
BA_ "VNSigAllNodes" SG_ 1371 DgnInf_HS55B 1;
BA_ "SignalType" SG_ 497 ElvtdIdlCstStReq "ENM";
BA_ "SignalLongName" SG_ 497 ElvtdIdlCstStReq "Elevated Idle Customization Setting Request";
BA_ "VNSigAllNodes" SG_ 497 ElvtdIdlCstStReq 1;
BA_ "SignalType" SG_ 497 FuelFltLfRstRqd "BLN";
BA_ "SignalLongName" SG_ 497 FuelFltLfRstRqd "Fuel Filter Life Reset Requested";
BA_ "VNSigAllNodes" SG_ 497 FuelFltLfRstRqd 1;
BA_ "SignalType" SG_ 497 ACCompSysVDA "ENM";
BA_ "SignalLongName" SG_ 497 ACCompSysVDA "Air Conditioning Compressor System Virtual Device Availability";
BA_ "GenSigStartValue" SG_ 497 ACCompSysVDA 1;
BA_ "VNSigAllNodes" SG_ 497 ACCompSysVDA 1;
BA_ "SignalType" SG_ 497 BkupPwrModeMstrVDA "ENM";
BA_ "SignalLongName" SG_ 497 BkupPwrModeMstrVDA "Backup Power Mode Master Virtual Device Availability";
BA_ "GenSigStartValue" SG_ 497 BkupPwrModeMstrVDA 1;
BA_ "VNSigAllNodes" SG_ 497 BkupPwrModeMstrVDA 1;
BA_ "SignalType" SG_ 497 PrkBrkVDA "ENM";
BA_ "SignalLongName" SG_ 497 PrkBrkVDA "Park Brake Virtual Device Availability";
BA_ "GenSigStartValue" SG_ 497 PrkBrkVDA 1;
BA_ "VNSigAllNodes" SG_ 497 PrkBrkVDA 1;
BA_ "SignalType" SG_ 497 PrkBrkVDM "ENM";
BA_ "SignalLongName" SG_ 497 PrkBrkVDM "Park Brake Virtual Device Mask";
BA_ "GenSigStartValue" SG_ 497 PrkBrkVDM 1;
BA_ "VNSigAllNodes" SG_ 497 PrkBrkVDM 1;
BA_ "SignalType" SG_ 497 BkupPwrModeMstrVDM "ENM";
BA_ "SignalLongName" SG_ 497 BkupPwrModeMstrVDM "Backup Power Mode Master Virtual Device Mask";
BA_ "VNSigAllNodes" SG_ 497 BkupPwrModeMstrVDM 1;
BA_ "SignalType" SG_ 497 ACCompSysVDM "ENM";
BA_ "SignalLongName" SG_ 497 ACCompSysVDM "Air Conditioning Compressor System Virtual Device Mask";
BA_ "VNSigAllNodes" SG_ 497 ACCompSysVDM 1;
BA_ "SignalType" SG_ 497 AirbgVDA "ENM";
BA_ "SignalLongName" SG_ 497 AirbgVDA "Airbag Virtual Device Availability";
BA_ "GenSigStartValue" SG_ 497 AirbgVDA 1;
BA_ "VNSigAllNodes" SG_ 497 AirbgVDA 1;
BA_ "SignalType" SG_ 497 SysBkupPwrMdEn "BLN";
BA_ "SignalLongName" SG_ 497 SysBkupPwrMdEn "System Backup Power Mode Enabled";
BA_ "VNSigAllNodes" SG_ 497 SysBkupPwrMdEn 1;
BA_ "SignalType" SG_ 497 SysBkUpPwrMd "ENM";
BA_ "SignalLongName" SG_ 497 SysBkUpPwrMd "System Backup Power Mode";
BA_ "VNSigAllNodes" SG_ 497 SysBkUpPwrMd 1;
BA_ "SignalType" SG_ 497 SysPwrMd "ENM";
BA_ "SignalLongName" SG_ 497 SysPwrMd "System Power Mode";
BA_ "VNSigAllNodes" SG_ 497 SysPwrMd 1;
BA_ "SignalType" SG_ 497 TrStLgMdAtv "BLN";
BA_ "SignalLongName" SG_ 497 TrStLgMdAtv "Transport Storage Logistic Mode Active";
BA_ "VNSigAllNodes" SG_ 497 TrStLgMdAtv 1;
BA_ "SignalType" SG_ 497 DispMeasSys "ENM";
BA_ "SignalLongName" SG_ 497 DispMeasSys "Display Measurement System";
BA_ "VNSigAllNodes" SG_ 497 DispMeasSys 1;
BA_ "SignalType" SG_ 497 ACCmpsrFldOn "BLN";
BA_ "SignalLongName" SG_ 497 ACCmpsrFldOn "Air Conditioning Compressor Failed On";
BA_ "VNSigAllNodes" SG_ 497 ACCmpsrFldOn 1;
BA_ "SignalType" SG_ 497 ACCompModReq "ENM";
BA_ "SignalLongName" SG_ 497 ACCompModReq "Air Conditioning Compressor Mode Request";
BA_ "VNSigAllNodes" SG_ 497 ACCompModReq 1;
BA_ "SignalType" SG_ 497 ACCompNormLd "UNM";
BA_ "SignalLongName" SG_ 497 ACCompNormLd "Air Conditioning Compressor Normalized Load";
BA_ "VNSigAllNodes" SG_ 497 ACCompNormLd 1;
BA_ "SignalType" SG_ 497 ACCompNormLdV "ENM";
BA_ "SignalLongName" SG_ 497 ACCompNormLdV "Air Conditioning Compressor Normalized Load Validity";
BA_ "VNSigAllNodes" SG_ 497 ACCompNormLdV 1;
BA_ "SignalType" SG_ 497 PTORSMstrEngShtReq "BLN";
BA_ "SignalLongName" SG_ 497 PTORSMstrEngShtReq "Power Take Off Remote Start Master Engine Shutdown Requested";
BA_ "VNSigAllNodes" SG_ 497 PTORSMstrEngShtReq 1;
BA_ "SignalType" SG_ 497 EngOilLfRstRq "BLN";
BA_ "SignalLongName" SG_ 497 EngOilLfRstRq "Engine Oil Life Reset Request";
BA_ "VNSigAllNodes" SG_ 497 EngOilLfRstRq 1;
BA_ "SignalType" SG_ 497 SIRDpl "BLN";
BA_ "SignalLongName" SG_ 497 SIRDpl "Airbag Deployed";
BA_ "VNSigAllNodes" SG_ 497 SIRDpl 1;
BA_ "SignalType" SG_ 497 PTORmStMsEngStRq "ENM";
BA_ "SignalLongName" SG_ 497 PTORmStMsEngStRq "Power Take Off Remote Start Master Engine Start Request";
BA_ "VNSigAllNodes" SG_ 497 PTORmStMsEngStRq 1;
BA_ "SignalType" SG_ 497 RmVehStrRq "ENM";
BA_ "SignalLongName" SG_ 497 RmVehStrRq "Remote Vehicle Start Request";
BA_ "VNSigAllNodes" SG_ 497 RmVehStrRq 1;
BA_ "SignalType" SG_ 497 ThrtlPrgrsnReq "ENM";
BA_ "SignalLongName" SG_ 497 ThrtlPrgrsnReq "Throttle Progression Request";
BA_ "VNSigAllNodes" SG_ 497 ThrtlPrgrsnReq 1;
BA_ "SignalType" SG_ 497 PrkBrkSwAtv "BLN";
BA_ "SignalLongName" SG_ 497 PrkBrkSwAtv "Park Brake Switch Active";
BA_ "VNSigAllNodes" SG_ 497 PrkBrkSwAtv 1;
BA_ "SignalType" SG_ 497 PMMAccTrmSt "ENM";
BA_ "SignalLongName" SG_ 497 PMMAccTrmSt "Power Mode Master Accessory Terminal Status";
BA_ "VNSigAllNodes" SG_ 497 PMMAccTrmSt 1;
BA_ "SignalType" SG_ 497 PMMRunCrkTrmSt "ENM";
BA_ "SignalLongName" SG_ 497 PMMRunCrkTrmSt "Power Mode Master Run Crank Terminal Status";
BA_ "VNSigAllNodes" SG_ 497 PMMRunCrkTrmSt 1;
BA_ "SignalType" SG_ 497 ImmblzrPreRelPswdStat "ENM";
BA_ "SignalLongName" SG_ 497 ImmblzrPreRelPswdStat "Immobilizer Pre Release Password Status";
BA_ "VNSigAllNodes" SG_ 497 ImmblzrPreRelPswdStat 1;
BA_ "SignalType" SG_ 497 ImmblzrPreRelPswrd "UNM";
BA_ "SignalLongName" SG_ 497 ImmblzrPreRelPswrd "Immobilizer Pre Release Password";
BA_ "VNSigAllNodes" SG_ 497 ImmblzrPreRelPswrd 1;
BA_ "SignalType" SG_ 1908 DTCI_DTCFaultType_774 "ENM";
BA_ "PacketOrder" SG_ 1908 DTCI_DTCFaultType_774 20;
BA_ "SignalLongName" SG_ 1908 DTCI_DTCFaultType_774 "Diagnostic Trouble Code Information Extended 774 : Diagnostic Trouble Code Fault Type";
BA_ "VNSigAllNodes" SG_ 1908 DTCI_DTCFaultType_774 1;
BA_ "SignalType" SG_ 1908 DTCI_CodeSupported_774 "BLN";
BA_ "PacketOrder" SG_ 1908 DTCI_CodeSupported_774 19;
BA_ "SignalLongName" SG_ 1908 DTCI_CodeSupported_774 "Diagnostic Trouble Code Information Extended 774 : Code Supported";
BA_ "VNSigAllNodes" SG_ 1908 DTCI_CodeSupported_774 1;
BA_ "SignalType" SG_ 1908 DTCI_CurrentStatus_774 "BLN";
BA_ "PacketOrder" SG_ 1908 DTCI_CurrentStatus_774 18;
BA_ "SignalLongName" SG_ 1908 DTCI_CurrentStatus_774 "Diagnostic Trouble Code Information Extended 774 : Current Status";
BA_ "VNSigAllNodes" SG_ 1908 DTCI_CurrentStatus_774 1;
BA_ "SignalType" SG_ 1908 DTCI_TstNPsdCdClrdSt_774 "BLN";
BA_ "PacketOrder" SG_ 1908 DTCI_TstNPsdCdClrdSt_774 17;
BA_ "SignalLongName" SG_ 1908 DTCI_TstNPsdCdClrdSt_774 "Diagnostic Trouble Code Information Extended 774 : Test Not Passed Since Code Cleared Status";
BA_ "VNSigAllNodes" SG_ 1908 DTCI_TstNPsdCdClrdSt_774 1;
BA_ "SignalType" SG_ 1908 DTCI_TstFldCdClrdStat_774 "BLN";
BA_ "PacketOrder" SG_ 1908 DTCI_TstFldCdClrdStat_774 16;
BA_ "SignalLongName" SG_ 1908 DTCI_TstFldCdClrdStat_774 "Diagnostic Trouble Code Information Extended 774 : Test Failed Since Code Cleared Status";
BA_ "VNSigAllNodes" SG_ 1908 DTCI_TstFldCdClrdStat_774 1;
BA_ "SignalType" SG_ 1908 DTCI_HistStat_774 "BLN";
BA_ "PacketOrder" SG_ 1908 DTCI_HistStat_774 15;
BA_ "SignalLongName" SG_ 1908 DTCI_HistStat_774 "Diagnostic Trouble Code Information Extended 774 : History Status";
BA_ "VNSigAllNodes" SG_ 1908 DTCI_HistStat_774 1;
BA_ "SignalType" SG_ 1908 DTCI_TstNPsdPwrUpSt_774 "BLN";
BA_ "PacketOrder" SG_ 1908 DTCI_TstNPsdPwrUpSt_774 14;
BA_ "SignalLongName" SG_ 1908 DTCI_TstNPsdPwrUpSt_774 "Diagnostic Trouble Code Information Extended 774 : Test Not Passed Since Power Up Status";
BA_ "VNSigAllNodes" SG_ 1908 DTCI_TstNPsdPwrUpSt_774 1;
BA_ "SignalType" SG_ 1908 DTCI_TstFldPwrUpSt_774 "BLN";
BA_ "PacketOrder" SG_ 1908 DTCI_TstFldPwrUpSt_774 13;
BA_ "SignalLongName" SG_ 1908 DTCI_TstFldPwrUpSt_774 "Diagnostic Trouble Code Information Extended 774 : Test Failed Since Power Up Status";
BA_ "VNSigAllNodes" SG_ 1908 DTCI_TstFldPwrUpSt_774 1;
BA_ "SignalType" SG_ 1908 DTCI_WrnIndRqdSt_774 "BLN";
BA_ "PacketOrder" SG_ 1908 DTCI_WrnIndRqdSt_774 12;
BA_ "SignalLongName" SG_ 1908 DTCI_WrnIndRqdSt_774 "Diagnostic Trouble Code Information Extended 774 : Warning Indicator Requested Status";
BA_ "VNSigAllNodes" SG_ 1908 DTCI_WrnIndRqdSt_774 1;
BA_ "SignalType" SG_ 1908 DTCI_DTCFailType_774 "UNM";
BA_ "PacketOrder" SG_ 1908 DTCI_DTCFailType_774 11;
BA_ "SignalLongName" SG_ 1908 DTCI_DTCFailType_774 "Diagnostic Trouble Code Information Extended 774 : Diagnostic Trouble Code Failure Type";
BA_ "VNSigAllNodes" SG_ 1908 DTCI_DTCFailType_774 1;
BA_ "SignalType" SG_ 1908 DTCI_DTCNumber_774 "UNM";
BA_ "PacketOrder" SG_ 1908 DTCI_DTCNumber_774 10;
BA_ "SignalLongName" SG_ 1908 DTCI_DTCNumber_774 "Diagnostic Trouble Code Information Extended 774 : Diagnostic Trouble Code Number";
BA_ "VNSigAllNodes" SG_ 1908 DTCI_DTCNumber_774 1;
BA_ "SignalType" SG_ 1908 DTCI_DTCSource_774 "UNM";
BA_ "PacketOrder" SG_ 1908 DTCI_DTCSource_774 9;
BA_ "SignalLongName" SG_ 1908 DTCI_DTCSource_774 "Diagnostic Trouble Code Information Extended 774 : Diagnostic Trouble Code Source";
BA_ "VNSigAllNodes" SG_ 1908 DTCI_DTCSource_774 1;
BA_ "SignalType" SG_ 1908 DTCI_DTCTriggered_774 "BLN";
BA_ "PacketOrder" SG_ 1908 DTCI_DTCTriggered_774 8;
BA_ "SignalLongName" SG_ 1908 DTCI_DTCTriggered_774 "Diagnostic Trouble Code Information Extended 774 : Diagnostic Trouble Code Triggered";
BA_ "VNSigAllNodes" SG_ 1908 DTCI_DTCTriggered_774 1;
BA_ "SignalType" SG_ 1908 DTCIUnused7_774 "BLN";
BA_ "PacketOrder" SG_ 1908 DTCIUnused7_774 7;
BA_ "SignalLongName" SG_ 1908 DTCIUnused7_774 "Diagnostic Trouble Code Information Extended 774 : Unused 7";
BA_ "VNSigAllNodes" SG_ 1908 DTCIUnused7_774 1;
BA_ "SignalType" SG_ 1908 DTCIUnused6_774 "BLN";
BA_ "PacketOrder" SG_ 1908 DTCIUnused6_774 6;
BA_ "SignalLongName" SG_ 1908 DTCIUnused6_774 "Diagnostic Trouble Code Information Extended 774 : Unused 6";
BA_ "VNSigAllNodes" SG_ 1908 DTCIUnused6_774 1;
BA_ "SignalType" SG_ 1908 DTCIUnused5_774 "BLN";
BA_ "PacketOrder" SG_ 1908 DTCIUnused5_774 5;
BA_ "SignalLongName" SG_ 1908 DTCIUnused5_774 "Diagnostic Trouble Code Information Extended 774 : Unused 5";
BA_ "VNSigAllNodes" SG_ 1908 DTCIUnused5_774 1;
BA_ "SignalType" SG_ 1908 DTCIUnused4_774 "BLN";
BA_ "PacketOrder" SG_ 1908 DTCIUnused4_774 4;
BA_ "SignalLongName" SG_ 1908 DTCIUnused4_774 "Diagnostic Trouble Code Information Extended 774 : Unused 4";
BA_ "VNSigAllNodes" SG_ 1908 DTCIUnused4_774 1;
BA_ "SignalType" SG_ 1908 DTCIUnused3_774 "BLN";
BA_ "PacketOrder" SG_ 1908 DTCIUnused3_774 3;
BA_ "SignalLongName" SG_ 1908 DTCIUnused3_774 "Diagnostic Trouble Code Information Extended 774 : Unused 3";
BA_ "VNSigAllNodes" SG_ 1908 DTCIUnused3_774 1;
BA_ "SignalType" SG_ 1908 DTCIUnused2_774 "BLN";
BA_ "PacketOrder" SG_ 1908 DTCIUnused2_774 2;
BA_ "SignalLongName" SG_ 1908 DTCIUnused2_774 "Diagnostic Trouble Code Information Extended 774 : Unused 2";
BA_ "VNSigAllNodes" SG_ 1908 DTCIUnused2_774 1;
BA_ "SignalType" SG_ 1908 DTCIUnused1_774 "BLN";
BA_ "PacketOrder" SG_ 1908 DTCIUnused1_774 1;
BA_ "SignalLongName" SG_ 1908 DTCIUnused1_774 "Diagnostic Trouble Code Information Extended 774 : Unused 1";
BA_ "VNSigAllNodes" SG_ 1908 DTCIUnused1_774 1;
BA_ "VNSigSLHSSharedDiagnostic" SG_ 578 DgnInf 1;
BA_ "SignalType" SG_ 578 DgnInf "UNM";
BA_ "SignalLongName" SG_ 578 DgnInf "Diagnostic Information";
BA_ "VNSigAllNodes" SG_ 578 DgnInf 1;
BA_ "VNSigSLHSSharedDiagnostic" SG_ 584 DgnInf 1;
BA_ "SignalType" SG_ 584 DgnInf "UNM";
BA_ "SignalLongName" SG_ 584 DgnInf "Diagnostic Information";
BA_ "VNSigAllNodes" SG_ 584 DgnInf 1;
BA_ "SignalType" SG_ 1233 PTExPrtclFltWrng3IO "BLN";
BA_ "SignalLongName" SG_ 1233 PTExPrtclFltWrng3IO "Powertrain Exhaust Particle Filter Warning 3 Indication On";
BA_ "VNSigAllNodes" SG_ 1233 PTExPrtclFltWrng3IO 1;
BA_ "SignalType" SG_ 1233 PTExPartFltManRegStat "ENM";
BA_ "SignalLongName" SG_ 1233 PTExPartFltManRegStat "Powertrain Exhaust Particle Filter Manual Regeneration Status";
BA_ "VNSigAllNodes" SG_ 1233 PTExPartFltManRegStat 1;
BA_ "SignalType" SG_ 1233 a_12VBatSysUnstab "BLN";
BA_ "SignalLongName" SG_ 1233 a_12VBatSysUnstab "12 Volt Battery System Unstable";
BA_ "VNSigAllNodes" SG_ 1233 a_12VBatSysUnstab 1;
BA_ "SignalType" SG_ 1233 EngShtdwnAct "BLN";
BA_ "SignalLongName" SG_ 1233 EngShtdwnAct "Engine Shutdown Active";
BA_ "VNSigAllNodes" SG_ 1233 EngShtdwnAct 1;
BA_ "SignalType" SG_ 1233 EngShtdwnPndgIO "BLN";
BA_ "SignalLongName" SG_ 1233 EngShtdwnPndgIO "Engine Shutdown Pending Indication On";
BA_ "VNSigAllNodes" SG_ 1233 EngShtdwnPndgIO 1;
BA_ "SignalType" SG_ 1233 FuelFltChgNwIO "BLN";
BA_ "SignalLongName" SG_ 1233 FuelFltChgNwIO "Fuel Filter Change Now Indication On";
BA_ "VNSigAllNodes" SG_ 1233 FuelFltChgNwIO 1;
BA_ "SignalType" SG_ 1233 PTExPrtclFltrWrn2IO "BLN";
BA_ "SignalLongName" SG_ 1233 PTExPrtclFltrWrn2IO "Powertrain Exhaust Particle Filter Warning 2 Indication On";
BA_ "VNSigAllNodes" SG_ 1233 PTExPrtclFltrWrn2IO 1;
BA_ "SignalType" SG_ 1233 PTHiElecLdReqd "BLN";
BA_ "SignalLongName" SG_ 1233 PTHiElecLdReqd "Powertrain High Electrical Load Requested";
BA_ "VNSigAllNodes" SG_ 1233 PTHiElecLdReqd 1;
BA_ "SignalType" SG_ 1233 PTExPrtclFltrWrnIO "BLN";
BA_ "SignalLongName" SG_ 1233 PTExPrtclFltrWrnIO "Powertrain Exhaust Particle Filter Warning Indication On";
BA_ "VNSigAllNodes" SG_ 1233 PTExPrtclFltrWrnIO 1;
BA_ "SignalType" SG_ 1233 AirCndOffIO "BLN";
BA_ "SignalLongName" SG_ 1233 AirCndOffIO "Air Conditioning Off Indication On";
BA_ "VNSigAllNodes" SG_ 1233 AirCndOffIO 1;
BA_ "SignalType" SG_ 1233 DslGlwPlgIO "BLN";
BA_ "SignalLongName" SG_ 1233 DslGlwPlgIO "Diesel Glow Plug Indication On";
BA_ "VNSigAllNodes" SG_ 1233 DslGlwPlgIO 1;
BA_ "SignalType" SG_ 1233 RdcdPwrIO "BLN";
BA_ "SignalLongName" SG_ 1233 RdcdPwrIO "Reduced Power Indication On";
BA_ "VNSigAllNodes" SG_ 1233 RdcdPwrIO 1;
BA_ "SignalType" SG_ 1233 FuelTotCap "UNM";
BA_ "SignalLongName" SG_ 1233 FuelTotCap "Fuel Total Capacity";
BA_ "VNSigAllNodes" SG_ 1233 FuelTotCap 1;
BA_ "SignalType" SG_ 1233 FlLvlPctV "ENM";
BA_ "SignalLongName" SG_ 1233 FlLvlPctV "Fuel Level Percent Validity";
BA_ "VNSigAllNodes" SG_ 1233 FlLvlPctV 1;
BA_ "SignalType" SG_ 1233 FlLvlPct "UNM";
BA_ "SignalLongName" SG_ 1233 FlLvlPct "Fuel Level Percent";
BA_ "VNSigAllNodes" SG_ 1233 FlLvlPct 1;
BA_ "SignalType" SG_ 1233 EngWtrInFlIO "BLN";
BA_ "SignalLongName" SG_ 1233 EngWtrInFlIO "Engine Water In Fuel Indication On";
BA_ "VNSigAllNodes" SG_ 1233 EngWtrInFlIO 1;
BA_ "SignalType" SG_ 1233 EngOilTmpV "ENM";
BA_ "SignalLongName" SG_ 1233 EngOilTmpV "Engine Oil Temperature Validity";
BA_ "VNSigAllNodes" SG_ 1233 EngOilTmpV 1;
BA_ "SignalType" SG_ 1233 EngOilTmp "UNM";
BA_ "SignalLongName" SG_ 1233 EngOilTmp "Engine Oil Temperature";
BA_ "VNSigAllNodes" SG_ 1233 EngOilTmp 1;
BA_ "SignalType" SG_ 1233 EngOilPrsV "ENM";
BA_ "SignalLongName" SG_ 1233 EngOilPrsV "Engine Oil Pressure Validity";
BA_ "VNSigAllNodes" SG_ 1233 EngOilPrsV 1;
BA_ "SignalType" SG_ 1233 EngOilPrsLwIO "BLN";
BA_ "SignalLongName" SG_ 1233 EngOilPrsLwIO "Engine Oil Pressure Low Indication On";
BA_ "VNSigAllNodes" SG_ 1233 EngOilPrsLwIO 1;
BA_ "SignalType" SG_ 1233 EngOilPrs "UNM";
BA_ "SignalLongName" SG_ 1233 EngOilPrs "Engine Oil Pressure";
BA_ "VNSigAllNodes" SG_ 1233 EngOilPrs 1;
BA_ "SignalType" SG_ 1233 EngOilLvlLwIO "BLN";
BA_ "SignalLongName" SG_ 1233 EngOilLvlLwIO "Engine Oil Level Low Indication On";
BA_ "VNSigAllNodes" SG_ 1233 EngOilLvlLwIO 1;
BA_ "SignalType" SG_ 1233 EngOilChngIO "BLN";
BA_ "SignalLongName" SG_ 1233 EngOilChngIO "Engine Oil Change Indication On";
BA_ "VNSigAllNodes" SG_ 1233 EngOilChngIO 1;
BA_ "SignalType" SG_ 1233 EngHt_StpEngIO "BLN";
BA_ "SignalLongName" SG_ 1233 EngHt_StpEngIO "Engine Hot / Stop Engine Indication On";
BA_ "VNSigAllNodes" SG_ 1233 EngHt_StpEngIO 1;
BA_ "SignalType" SG_ 1233 EngHotFuelEnrchmntIO "BLN";
BA_ "SignalLongName" SG_ 1233 EngHotFuelEnrchmntIO "Engine Hot Fuel Enrichment Indication On";
BA_ "VNSigAllNodes" SG_ 1233 EngHotFuelEnrchmntIO 1;
BA_ "SignalType" SG_ 1233 CkFlFilrCapIO "BLN";
BA_ "SignalLongName" SG_ 1233 CkFlFilrCapIO "Check Fuel Filler Cap Indication On";
BA_ "VNSigAllNodes" SG_ 1233 CkFlFilrCapIO 1;
BA_ "VNSigSLHSSharedDiagnostic" SG_ 257 DgnInf 1;
BA_ "SignalType" SG_ 257 DgnInf "UNM";
BA_ "SignalLongName" SG_ 257 DgnInf "Diagnostic Information";
BA_ "VNSigAllNodes" SG_ 257 DgnInf 1;
BA_ "VNSigSLHSSharedDiagnostic" SG_ 1620 DgnInf 1;
BA_ "SignalType" SG_ 1620 DgnInf "UNM";
BA_ "SignalLongName" SG_ 1620 DgnInf "Diagnostic Information";
BA_ "VNSigAllNodes" SG_ 1620 DgnInf 1;
BA_ "VNSigSLHSSharedDiagnostic" SG_ 596 DgnInf 1;
BA_ "SignalType" SG_ 596 DgnInf "UNM";
BA_ "SignalLongName" SG_ 596 DgnInf "Diagnostic Information";
BA_ "VNSigAllNodes" SG_ 596 DgnInf 1;
BA_ "VNSigSLHSSharedDiagnostic" SG_ 579 DgnInf 1;
BA_ "SignalType" SG_ 579 DgnInf "UNM";
BA_ "SignalLongName" SG_ 579 DgnInf "Diagnostic Information";
BA_ "VNSigAllNodes" SG_ 579 DgnInf 1;
BA_ "VNSigSLHSSharedDiagnostic" SG_ 587 DgnInf 1;
BA_ "SignalType" SG_ 587 DgnInf "UNM";
BA_ "SignalLongName" SG_ 587 DgnInf "Diagnostic Information";
BA_ "VNSigAllNodes" SG_ 587 DgnInf 1;
BA_ "VNSigSLHSSharedDiagnostic" SG_ 1611 DgnInf 1;
BA_ "SignalType" SG_ 1611 DgnInf "UNM";
BA_ "SignalLongName" SG_ 1611 DgnInf "Diagnostic Information";
BA_ "VNSigAllNodes" SG_ 1611 DgnInf 1;
BA_ "VNSigSLHSSharedDiagnostic" SG_ 1355 DgnInf_HS54B 1;
BA_ "SignalType" SG_ 1355 DgnInf_HS54B "UNM";
BA_ "SignalLongName" SG_ 1355 DgnInf_HS54B "Diagnostic Information HS54B";
BA_ "VNSigAllNodes" SG_ 1355 DgnInf_HS54B 1;
BA_ "SignalType" SG_ 382 BrkSysBrkLtsReqdRed "BLN";
BA_ "SignalLongName" SG_ 382 BrkSysBrkLtsReqdRed "Brake System Brake Lights Requested Redundant";
BA_ "VNSigAllNodes" SG_ 382 BrkSysBrkLtsReqdRed 1;
BA_ "SignalType" SG_ 508 ChsSysTtlBkAxlTqStARC "UNM";
BA_ "SignalLongName" SG_ 508 ChsSysTtlBkAxlTqStARC "Chassis System Total Brake Axle Torque Status Alive Rolling Count";
BA_ "VNSigAllNodes" SG_ 508 ChsSysTtlBkAxlTqStARC 1;
BA_ "SignalType" SG_ 508 CSTBATS_TrqVl "UNM";
BA_ "PacketOrder" SG_ 508 CSTBATS_TrqVl 2;
BA_ "SignalLongName" SG_ 508 CSTBATS_TrqVl "Chassis System Total Brake Axle Torque Status : Torque Value";
BA_ "VNSigAllNodes" SG_ 508 CSTBATS_TrqVl 1;
BA_ "SignalType" SG_ 508 CSTBATS_TrqVlV "ENM";
BA_ "PacketOrder" SG_ 508 CSTBATS_TrqVlV 1;
BA_ "SignalLongName" SG_ 508 CSTBATS_TrqVlV "Chassis System Total Brake Axle Torque Status : Torque Value Validity";
BA_ "VNSigAllNodes" SG_ 508 CSTBATS_TrqVlV 1;
BA_ "SignalType" SG_ 508 LonLatAccSnsValARC "UNM";
BA_ "SignalLongName" SG_ 508 LonLatAccSnsValARC "Longitudinal/Lateral Acceleration Sensor Value Alive Rolling Count";
BA_ "VNSigAllNodes" SG_ 508 LonLatAccSnsValARC 1;
BA_ "SignalType" SG_ 508 LonLatAccSnsChk "UNM";
BA_ "SignalLongName" SG_ 508 LonLatAccSnsChk "Longitudinal/Lateral Acceleration Sensor Checksum";
BA_ "VNSigAllNodes" SG_ 508 LonLatAccSnsChk 1;
BA_ "SignalType" SG_ 508 LatAccSnsVal "SNM";
BA_ "SignalLongName" SG_ 508 LatAccSnsVal "Lateral Acceleration Sensor Value";
BA_ "VNSigAllNodes" SG_ 508 LatAccSnsVal 1;
BA_ "SignalType" SG_ 508 LonAccSnsVal "SNM";
BA_ "SignalLongName" SG_ 508 LonAccSnsVal "Longitudinal Acceleration Sensor Value";
BA_ "VNSigAllNodes" SG_ 508 LonAccSnsVal 1;
BA_ "SignalType" SG_ 407 TransActlRngStPVal "UNM";
BA_ "SignalLongName" SG_ 407 TransActlRngStPVal "Transmission Actual Range Status Protection Value";
BA_ "VNSigAllNodes" SG_ 407 TransActlRngStPVal 1;
BA_ "SignalType" SG_ 407 TransActlRngStARC "UNM";
BA_ "SignalLongName" SG_ 407 TransActlRngStARC "Transmission Actual Range Status Alive Rolling Count";
BA_ "VNSigAllNodes" SG_ 407 TransActlRngStARC 1;
BA_ "SignalType" SG_ 407 TARS_TransActRngM "ENM";
BA_ "PacketOrder" SG_ 407 TARS_TransActRngM 2;
BA_ "SignalLongName" SG_ 407 TARS_TransActRngM "Transmission Actual Range Status : Transmission Actual Range Mask";
BA_ "VNSigAllNodes" SG_ 407 TARS_TransActRngM 1;
BA_ "PacketOrder" SG_ 407 TARS_TransActRngV 3;
BA_ "SignalType" SG_ 407 TARS_TransActRngV "ENM";
BA_ "SignalLongName" SG_ 407 TARS_TransActRngV "Transmission Actual Range Status : Transmission Actual Range Validity";
BA_ "VNSigAllNodes" SG_ 407 TARS_TransActRngV 1;
BA_ "PacketOrder" SG_ 407 TARS_TransActRng 1;
BA_ "SignalType" SG_ 407 TARS_TransActRng "ENM";
BA_ "SignalLongName" SG_ 407 TARS_TransActRng "Transmission Actual Range Status : Transmission Actual Range";
BA_ "VNSigAllNodes" SG_ 407 TARS_TransActRng 1;
BA_ "SignalType" SG_ 407 TrnsEgdPrFlwInfPVal "UNM";
BA_ "SignalLongName" SG_ 407 TrnsEgdPrFlwInfPVal "Transmission Engaged Powerflow Information Protection Value";
BA_ "VNSigAllNodes" SG_ 407 TrnsEgdPrFlwInfPVal 1;
BA_ "SignalType" SG_ 407 TrnsEgdPrFlwInfARC "UNM";
BA_ "SignalLongName" SG_ 407 TrnsEgdPrFlwInfARC "Transmission Engaged Powerflow Information Alive Rolling Count";
BA_ "VNSigAllNodes" SG_ 407 TrnsEgdPrFlwInfARC 1;
BA_ "PacketOrder" SG_ 407 TEPI_TrnsEngdPrFlwStV 2;
BA_ "SignalType" SG_ 407 TEPI_TrnsEngdPrFlwStV "ENM";
BA_ "SignalLongName" SG_ 407 TEPI_TrnsEngdPrFlwStV "Transmission Engaged Powerflow Information : Transmission Engaged Powerflow State Validity";
BA_ "VNSigAllNodes" SG_ 407 TEPI_TrnsEngdPrFlwStV 1;
BA_ "PacketOrder" SG_ 407 TEPI_TrnsEngdPrFlwSt 1;
BA_ "SignalType" SG_ 407 TEPI_TrnsEngdPrFlwSt "ENM";
BA_ "SignalLongName" SG_ 407 TEPI_TrnsEngdPrFlwSt "Transmission Engaged Powerflow Information : Transmission Engaged Powerflow State";
BA_ "VNSigAllNodes" SG_ 407 TEPI_TrnsEngdPrFlwSt 1;
BA_ "SignalType" SG_ 407 TransRatioV "ENM";
BA_ "SignalLongName" SG_ 407 TransRatioV "Transmission Ratio Validity";
BA_ "VNSigAllNodes" SG_ 407 TransRatioV 1;
BA_ "SignalType" SG_ 407 TransRatio "UNM";
BA_ "SignalLongName" SG_ 407 TransRatio "Transmission Ratio";
BA_ "VNSigAllNodes" SG_ 407 TransRatio 1;
BA_ "SignalType" SG_ 407 TrnsOvrallActTorqRatioV "ENM";
BA_ "SignalLongName" SG_ 407 TrnsOvrallActTorqRatioV "Transmission Overall Actual Torque Ratio Validity";
BA_ "VNSigAllNodes" SG_ 407 TrnsOvrallActTorqRatioV 1;
BA_ "SignalType" SG_ 407 TrnsOvrallActTorqRatio "SNM";
BA_ "SignalLongName" SG_ 407 TrnsOvrallActTorqRatio "Transmission Overall Actual Torque Ratio";
BA_ "VNSigAllNodes" SG_ 407 TrnsOvrallActTorqRatio 1;
BA_ "VNSigSLHSSharedDiagnostic" SG_ 1627 DgnInf 1;
BA_ "SignalType" SG_ 1627 DgnInf "UNM";
BA_ "SignalLongName" SG_ 1627 DgnInf "Diagnostic Information";
BA_ "VNSigAllNodes" SG_ 1627 DgnInf 1;
BA_ "VNSigSLHSSharedDiagnostic" SG_ 1603 DgnInf 1;
BA_ "SignalType" SG_ 1603 DgnInf "UNM";
BA_ "SignalLongName" SG_ 1603 DgnInf "Diagnostic Information";
BA_ "VNSigAllNodes" SG_ 1603 DgnInf 1;
BA_ "VNSigSLHSSharedDiagnostic" SG_ 1347 DgnInf_HS543 1;
BA_ "SignalType" SG_ 1347 DgnInf_HS543 "UNM";
BA_ "SignalLongName" SG_ 1347 DgnInf_HS543 "Diagnostic Information HS543";
BA_ "VNSigAllNodes" SG_ 1347 DgnInf_HS543 1;
BA_ "VNSigSLHSSharedDiagnostic" SG_ 1346 DgnInf_HS542 1;
BA_ "SignalType" SG_ 1346 DgnInf_HS542 "UNM";
BA_ "SignalLongName" SG_ 1346 DgnInf_HS542 "Diagnostic Information HS542";
BA_ "VNSigAllNodes" SG_ 1346 DgnInf_HS542 1;
BA_ "VNSigSLHSSharedDiagnostic" SG_ 1602 DgnInf 1;
BA_ "SignalType" SG_ 1602 DgnInf "UNM";
BA_ "SignalLongName" SG_ 1602 DgnInf "Diagnostic Information";
BA_ "VNSigAllNodes" SG_ 1602 DgnInf 1;
BA_REL_ "GenSigRxStartValue" BU_SG_REL_ EOCM2cp_K1_PHS SG_ 274 RedADIMCntrlFailed "False";
BA_REL_ "GenSigSuprvResp" BU_SG_REL_ EOCM2cp_K1_PHS SG_ 274 RedADIMCntrlFailed 1;
BA_REL_ "GenSigTimeoutMsg" BU_SG_REL_ EOCM2cp_K1_PHS SG_ 274 RedADIMCntrlFailed 274;
BA_REL_ "GenSigTimeoutTime" BU_SG_REL_ EOCM2cp_K1_PHS SG_ 274 RedADIMCntrlFailed 25;
BA_REL_ "GenSigRxStartValue" BU_SG_REL_ EPSb_PHS SG_ 274 RedADIMCntrlFailed "False";
BA_REL_ "GenSigSuprvResp" BU_SG_REL_ EPSb_PHS SG_ 274 RedADIMCntrlFailed 1;
BA_REL_ "GenSigTimeoutMsg" BU_SG_REL_ EPSb_PHS SG_ 274 RedADIMCntrlFailed 274;
BA_REL_ "GenSigTimeoutTime" BU_SG_REL_ EPSb_PHS SG_ 274 RedADIMCntrlFailed 25;
BA_REL_ "GenSigRxStartValue" BU_SG_REL_ EPSa_PHS SG_ 274 RedADIMCntrlFailed "False";
BA_REL_ "GenSigSuprvResp" BU_SG_REL_ EPSa_PHS SG_ 274 RedADIMCntrlFailed 1;
BA_REL_ "GenSigTimeoutMsg" BU_SG_REL_ EPSa_PHS SG_ 274 RedADIMCntrlFailed 274;
BA_REL_ "GenSigTimeoutTime" BU_SG_REL_ EPSa_PHS SG_ 274 RedADIMCntrlFailed 25;
BA_REL_ "GenSigRxStartValue" BU_SG_REL_ EBOOST_OBD_PHS SG_ 274 RedADIMCntrlFailed "False";
BA_REL_ "GenSigSuprvResp" BU_SG_REL_ EBOOST_OBD_PHS SG_ 274 RedADIMCntrlFailed 1;
BA_REL_ "GenSigTimeoutMsg" BU_SG_REL_ EBOOST_OBD_PHS SG_ 274 RedADIMCntrlFailed 274;
BA_REL_ "GenSigTimeoutTime" BU_SG_REL_ EBOOST_OBD_PHS SG_ 274 RedADIMCntrlFailed 25;
BA_REL_ "GenSigRxStartValue" BU_SG_REL_ EBCM_PHS SG_ 274 RedADIMCntrlFailed "false";
BA_REL_ "GenSigSuprvResp" BU_SG_REL_ EBCM_PHS SG_ 274 RedADIMCntrlFailed 1;
BA_REL_ "GenSigTimeoutMsg" BU_SG_REL_ EBCM_PHS SG_ 274 RedADIMCntrlFailed 274;
BA_REL_ "GenSigTimeoutTime" BU_SG_REL_ EBCM_PHS SG_ 274 RedADIMCntrlFailed 25;
BA_REL_ "GenSigSuprvResp" BU_SG_REL_ EBOOST_OBD_PHS SG_ 274 RedExtVehCtrlSts 1;
BA_REL_ "GenSigTimeoutMsg" BU_SG_REL_ EBOOST_OBD_PHS SG_ 274 RedExtVehCtrlSts 274;
BA_REL_ "GenSigTimeoutTime" BU_SG_REL_ EBOOST_OBD_PHS SG_ 274 RedExtVehCtrlSts 250;
BA_REL_ "GenSigSuprvResp" BU_SG_REL_ EBCM_PHS SG_ 274 RedExtVehCtrlSts 1;
BA_REL_ "GenSigTimeoutMsg" BU_SG_REL_ EBCM_PHS SG_ 274 RedExtVehCtrlSts 274;
BA_REL_ "GenSigTimeoutTime" BU_SG_REL_ EBCM_PHS SG_ 274 RedExtVehCtrlSts 250;
BA_REL_ "GenSigRxStartValue" BU_SG_REL_ EOCM2cp_K1_PHS SG_ 274 RedVehMdMngrSt "0";
BA_REL_ "GenSigSuprvResp" BU_SG_REL_ EOCM2cp_K1_PHS SG_ 274 RedVehMdMngrSt 1;
BA_REL_ "GenSigTimeoutMsg" BU_SG_REL_ EOCM2cp_K1_PHS SG_ 274 RedVehMdMngrSt 274;
BA_REL_ "GenSigTimeoutTime" BU_SG_REL_ EOCM2cp_K1_PHS SG_ 274 RedVehMdMngrSt 25;
BA_REL_ "GenSigRxStartValue" BU_SG_REL_ EPSb_PHS SG_ 274 RedVehMdMngrSt "0";
BA_REL_ "GenSigSuprvResp" BU_SG_REL_ EPSb_PHS SG_ 274 RedVehMdMngrSt 1;
BA_REL_ "GenSigTimeoutMsg" BU_SG_REL_ EPSb_PHS SG_ 274 RedVehMdMngrSt 274;
BA_REL_ "GenSigTimeoutTime" BU_SG_REL_ EPSb_PHS SG_ 274 RedVehMdMngrSt 25;
BA_REL_ "GenSigRxStartValue" BU_SG_REL_ EBOOST_OBD_PHS SG_ 274 RedVehMdMngrSt "0";
BA_REL_ "GenSigSuprvResp" BU_SG_REL_ EBOOST_OBD_PHS SG_ 274 RedVehMdMngrSt 1;
BA_REL_ "GenSigTimeoutMsg" BU_SG_REL_ EBOOST_OBD_PHS SG_ 274 RedVehMdMngrSt 274;
BA_REL_ "GenSigTimeoutTime" BU_SG_REL_ EBOOST_OBD_PHS SG_ 274 RedVehMdMngrSt 25;
BA_REL_ "GenSigRxStartValue" BU_SG_REL_ EBCM_PHS SG_ 274 RedVehMdMngrSt "0";
BA_REL_ "GenSigSuprvResp" BU_SG_REL_ EBCM_PHS SG_ 274 RedVehMdMngrSt 1;
BA_REL_ "GenSigTimeoutMsg" BU_SG_REL_ EBCM_PHS SG_ 274 RedVehMdMngrSt 274;
BA_REL_ "GenSigTimeoutTime" BU_SG_REL_ EBCM_PHS SG_ 274 RedVehMdMngrSt 25;
BA_REL_ "GenSigRxStartValue" BU_SG_REL_ EPSa_PHS SG_ 274 RedVehMdMngrSt "0";
BA_REL_ "GenSigSuprvResp" BU_SG_REL_ EPSa_PHS SG_ 274 RedVehMdMngrSt 1;
BA_REL_ "GenSigTimeoutMsg" BU_SG_REL_ EPSa_PHS SG_ 274 RedVehMdMngrSt 274;
BA_REL_ "GenSigTimeoutTime" BU_SG_REL_ EPSa_PHS SG_ 274 RedVehMdMngrSt 25;
BA_REL_ "GenSigRxStartValue" BU_SG_REL_ EPSa_PHS SG_ 274 RedEPSWhlAngReqTrgtAng "0";
BA_REL_ "GenSigSuprvResp" BU_SG_REL_ EPSa_PHS SG_ 274 RedEPSWhlAngReqTrgtAng 1;
BA_REL_ "GenSigTimeoutMsg" BU_SG_REL_ EPSa_PHS SG_ 274 RedEPSWhlAngReqTrgtAng 274;
BA_REL_ "GenSigTimeoutTime" BU_SG_REL_ EPSa_PHS SG_ 274 RedEPSWhlAngReqTrgtAng 25;
BA_REL_ "GenSigRxStartValue" BU_SG_REL_ EPSb_PHS SG_ 274 RedEPSWhlAngReqTrgtAng "0";
BA_REL_ "GenSigSuprvResp" BU_SG_REL_ EPSb_PHS SG_ 274 RedEPSWhlAngReqTrgtAng 1;
BA_REL_ "GenSigTimeoutMsg" BU_SG_REL_ EPSb_PHS SG_ 274 RedEPSWhlAngReqTrgtAng 274;
BA_REL_ "GenSigTimeoutTime" BU_SG_REL_ EPSb_PHS SG_ 274 RedEPSWhlAngReqTrgtAng 25;
BA_REL_ "GenSigRxStartValue" BU_SG_REL_ EBOOST_OBD_PHS SG_ 274 RedEPSWhlAngReqTrgtAng "0";
BA_REL_ "GenSigSuprvResp" BU_SG_REL_ EBOOST_OBD_PHS SG_ 274 RedEPSWhlAngReqTrgtAng 1;
BA_REL_ "GenSigTimeoutMsg" BU_SG_REL_ EBOOST_OBD_PHS SG_ 274 RedEPSWhlAngReqTrgtAng 274;
BA_REL_ "GenSigTimeoutTime" BU_SG_REL_ EBOOST_OBD_PHS SG_ 274 RedEPSWhlAngReqTrgtAng 25;
BA_REL_ "GenSigRxStartValue" BU_SG_REL_ EBCM_PHS SG_ 274 RedEPSWhlAngReqTrgtAng "0";
BA_REL_ "GenSigSuprvResp" BU_SG_REL_ EBCM_PHS SG_ 274 RedEPSWhlAngReqTrgtAng 1;
BA_REL_ "GenSigTimeoutMsg" BU_SG_REL_ EBCM_PHS SG_ 274 RedEPSWhlAngReqTrgtAng 274;
BA_REL_ "GenSigTimeoutTime" BU_SG_REL_ EBCM_PHS SG_ 274 RedEPSWhlAngReqTrgtAng 25;
BA_REL_ "GenSigRxStartValue" BU_SG_REL_ EPSa_PHS SG_ 274 RedAutoEPBReq "0";
BA_REL_ "GenSigSuprvResp" BU_SG_REL_ EPSa_PHS SG_ 274 RedAutoEPBReq 1;
BA_REL_ "GenSigTimeoutMsg" BU_SG_REL_ EPSa_PHS SG_ 274 RedAutoEPBReq 274;
BA_REL_ "GenSigTimeoutTime" BU_SG_REL_ EPSa_PHS SG_ 274 RedAutoEPBReq 25;
BA_REL_ "GenSigRxStartValue" BU_SG_REL_ EPSb_PHS SG_ 274 RedAutoEPBReq "0";
BA_REL_ "GenSigSuprvResp" BU_SG_REL_ EPSb_PHS SG_ 274 RedAutoEPBReq 1;
BA_REL_ "GenSigTimeoutMsg" BU_SG_REL_ EPSb_PHS SG_ 274 RedAutoEPBReq 274;
BA_REL_ "GenSigTimeoutTime" BU_SG_REL_ EPSb_PHS SG_ 274 RedAutoEPBReq 25;
BA_REL_ "GenSigRxStartValue" BU_SG_REL_ EBOOST_OBD_PHS SG_ 274 RedAutoEPBReq "0";
BA_REL_ "GenSigSuprvResp" BU_SG_REL_ EBOOST_OBD_PHS SG_ 274 RedAutoEPBReq 1;
BA_REL_ "GenSigTimeoutMsg" BU_SG_REL_ EBOOST_OBD_PHS SG_ 274 RedAutoEPBReq 274;
BA_REL_ "GenSigTimeoutTime" BU_SG_REL_ EBOOST_OBD_PHS SG_ 274 RedAutoEPBReq 25;
BA_REL_ "GenSigRxStartValue" BU_SG_REL_ EBCM_PHS SG_ 274 RedAutoEPBReq "0";
BA_REL_ "GenSigSuprvResp" BU_SG_REL_ EBCM_PHS SG_ 274 RedAutoEPBReq 1;
BA_REL_ "GenSigTimeoutMsg" BU_SG_REL_ EBCM_PHS SG_ 274 RedAutoEPBReq 274;
BA_REL_ "GenSigTimeoutTime" BU_SG_REL_ EBCM_PHS SG_ 274 RedAutoEPBReq 25;
BA_REL_ "GenSigRxStartValue" BU_SG_REL_ EPSa_PHS SG_ 274 RedAutoBrkTrqReq "0";
BA_REL_ "GenSigSuprvResp" BU_SG_REL_ EPSa_PHS SG_ 274 RedAutoBrkTrqReq 1;
BA_REL_ "GenSigTimeoutMsg" BU_SG_REL_ EPSa_PHS SG_ 274 RedAutoBrkTrqReq 274;
BA_REL_ "GenSigTimeoutTime" BU_SG_REL_ EPSa_PHS SG_ 274 RedAutoBrkTrqReq 25;
BA_REL_ "GenSigRxStartValue" BU_SG_REL_ EPSb_PHS SG_ 274 RedAutoBrkTrqReq "0";
BA_REL_ "GenSigSuprvResp" BU_SG_REL_ EPSb_PHS SG_ 274 RedAutoBrkTrqReq 1;
BA_REL_ "GenSigTimeoutMsg" BU_SG_REL_ EPSb_PHS SG_ 274 RedAutoBrkTrqReq 274;
BA_REL_ "GenSigTimeoutTime" BU_SG_REL_ EPSb_PHS SG_ 274 RedAutoBrkTrqReq 25;
BA_REL_ "GenSigRxStartValue" BU_SG_REL_ EBOOST_OBD_PHS SG_ 274 RedAutoBrkTrqReq "0";
BA_REL_ "GenSigSuprvResp" BU_SG_REL_ EBOOST_OBD_PHS SG_ 274 RedAutoBrkTrqReq 1;
BA_REL_ "GenSigTimeoutMsg" BU_SG_REL_ EBOOST_OBD_PHS SG_ 274 RedAutoBrkTrqReq 274;
BA_REL_ "GenSigTimeoutTime" BU_SG_REL_ EBOOST_OBD_PHS SG_ 274 RedAutoBrkTrqReq 25;
BA_REL_ "GenSigRxStartValue" BU_SG_REL_ EBCM_PHS SG_ 274 RedAutoBrkTrqReq "0";
BA_REL_ "GenSigSuprvResp" BU_SG_REL_ EBCM_PHS SG_ 274 RedAutoBrkTrqReq 1;
BA_REL_ "GenSigTimeoutMsg" BU_SG_REL_ EBCM_PHS SG_ 274 RedAutoBrkTrqReq 274;
BA_REL_ "GenSigTimeoutTime" BU_SG_REL_ EBCM_PHS SG_ 274 RedAutoBrkTrqReq 25;
BA_REL_ "GenSigRxStartValue" BU_SG_REL_ EPSa_PHS SG_ 274 RedAutoBrkReqType "0";
BA_REL_ "GenSigSuprvResp" BU_SG_REL_ EPSa_PHS SG_ 274 RedAutoBrkReqType 1;
BA_REL_ "GenSigTimeoutMsg" BU_SG_REL_ EPSa_PHS SG_ 274 RedAutoBrkReqType 274;
BA_REL_ "GenSigTimeoutTime" BU_SG_REL_ EPSa_PHS SG_ 274 RedAutoBrkReqType 25;
BA_REL_ "GenSigRxStartValue" BU_SG_REL_ EPSb_PHS SG_ 274 RedAutoBrkReqType "0";
BA_REL_ "GenSigSuprvResp" BU_SG_REL_ EPSb_PHS SG_ 274 RedAutoBrkReqType 1;
BA_REL_ "GenSigTimeoutMsg" BU_SG_REL_ EPSb_PHS SG_ 274 RedAutoBrkReqType 274;
BA_REL_ "GenSigTimeoutTime" BU_SG_REL_ EPSb_PHS SG_ 274 RedAutoBrkReqType 25;
BA_REL_ "GenSigRxStartValue" BU_SG_REL_ EBOOST_OBD_PHS SG_ 274 RedAutoBrkReqType "0";
BA_REL_ "GenSigSuprvResp" BU_SG_REL_ EBOOST_OBD_PHS SG_ 274 RedAutoBrkReqType 1;
BA_REL_ "GenSigTimeoutMsg" BU_SG_REL_ EBOOST_OBD_PHS SG_ 274 RedAutoBrkReqType 274;
BA_REL_ "GenSigTimeoutTime" BU_SG_REL_ EBOOST_OBD_PHS SG_ 274 RedAutoBrkReqType 25;
BA_REL_ "GenSigRxStartValue" BU_SG_REL_ EBCM_PHS SG_ 274 RedAutoBrkReqType "0";
BA_REL_ "GenSigSuprvResp" BU_SG_REL_ EBCM_PHS SG_ 274 RedAutoBrkReqType 1;
BA_REL_ "GenSigTimeoutMsg" BU_SG_REL_ EBCM_PHS SG_ 274 RedAutoBrkReqType 274;
BA_REL_ "GenSigTimeoutTime" BU_SG_REL_ EBCM_PHS SG_ 274 RedAutoBrkReqType 25;
BA_REL_ "GenSigRxStartValue" BU_SG_REL_ EPSa_PHS SG_ 274 RedAutoBrkaStrgReqChksm "0";
BA_REL_ "GenSigRxStartValue" BU_SG_REL_ EPSb_PHS SG_ 274 RedAutoBrkaStrgReqChksm "0";
BA_REL_ "GenSigRxStartValue" BU_SG_REL_ EBOOST_OBD_PHS SG_ 274 RedAutoBrkaStrgReqChksm "0";
BA_REL_ "GenSigRxStartValue" BU_SG_REL_ EBCM_PHS SG_ 274 RedAutoBrkaStrgReqChksm "0";
BA_REL_ "GenSigRxStartValue" BU_SG_REL_ EPSa_PHS SG_ 274 RedAutoBrkaStrgReqARC "0";
BA_REL_ "GenSigRxStartValue" BU_SG_REL_ EPSb_PHS SG_ 274 RedAutoBrkaStrgReqARC "0";
BA_REL_ "GenSigRxStartValue" BU_SG_REL_ EBOOST_OBD_PHS SG_ 274 RedAutoBrkaStrgReqARC "0";
BA_REL_ "GenSigRxStartValue" BU_SG_REL_ EBCM_PHS SG_ 274 RedAutoBrkaStrgReqARC "0";
BA_REL_ "GenSigSuprvResp" BU_SG_REL_ EBCM_PHS SG_ 274 RedAutoBrkSysRdcPerDet 1;
BA_REL_ "GenSigTimeoutMsg" BU_SG_REL_ EBCM_PHS SG_ 274 RedAutoBrkSysRdcPerDet 274;
BA_REL_ "GenSigTimeoutTime" BU_SG_REL_ EBCM_PHS SG_ 274 RedAutoBrkSysRdcPerDet 250;
BA_REL_ "GenSigSuprvResp" BU_SG_REL_ EBOOST_OBD_PHS SG_ 274 RedAutoBrkSysRdcPerDet 1;
BA_REL_ "GenSigTimeoutMsg" BU_SG_REL_ EBOOST_OBD_PHS SG_ 274 RedAutoBrkSysRdcPerDet 274;
BA_REL_ "GenSigTimeoutTime" BU_SG_REL_ EBOOST_OBD_PHS SG_ 274 RedAutoBrkSysRdcPerDet 250;
BA_REL_ "GenSigSuprvResp" BU_SG_REL_ EOCM2cp_IMX6_PHS SG_ 1300 VehIdNmDig2_9 1;
BA_REL_ "GenSigTimeoutMsg" BU_SG_REL_ EOCM2cp_IMX6_PHS SG_ 1300 VehIdNmDig2_9 1300;
BA_REL_ "GenSigTimeoutTime" BU_SG_REL_ EOCM2cp_IMX6_PHS SG_ 1300 VehIdNmDig2_9 2500;
BA_REL_ "GenSigRxStartValue" BU_SG_REL_ EBCM_PHS SG_ 979 PTABR_AccReq "0";
BA_REL_ "GenSigSuprvResp" BU_SG_REL_ EBCM_PHS SG_ 979 PTABR_AccReq 1;
BA_REL_ "GenSigTimeoutMsg" BU_SG_REL_ EBCM_PHS SG_ 979 PTABR_AccReq 979;
BA_REL_ "GenSigTimeoutTime" BU_SG_REL_ EBCM_PHS SG_ 979 PTABR_AccReq 250;
BA_REL_ "GenSigRxStartValue" BU_SG_REL_ EBCM_PHS SG_ 979 PTABR_PTBrkRqAct "0";
BA_REL_ "GenSigSuprvResp" BU_SG_REL_ EBCM_PHS SG_ 979 PTABR_PTBrkRqAct 1;
BA_REL_ "GenSigTimeoutMsg" BU_SG_REL_ EBCM_PHS SG_ 979 PTABR_PTBrkRqAct 979;
BA_REL_ "GenSigTimeoutTime" BU_SG_REL_ EBCM_PHS SG_ 979 PTABR_PTBrkRqAct 250;
BA_REL_ "GenSigRxStartValue" BU_SG_REL_ EBCM_PHS SG_ 979 PTAutoBrkReqPVal "0";
BA_REL_ "GenSigRxStartValue" BU_SG_REL_ EBCM_PHS SG_ 979 PTAutoBrkReqARC "0";
BA_REL_ "GenSigSuprvResp" BU_SG_REL_ EBCM_PHS SG_ 979 BrkBstVac 1;
BA_REL_ "GenSigTimeoutMsg" BU_SG_REL_ EBCM_PHS SG_ 979 BrkBstVac 979;
BA_REL_ "GenSigTimeoutTime" BU_SG_REL_ EBCM_PHS SG_ 979 BrkBstVac 250;
BA_REL_ "GenSigSuprvResp" BU_SG_REL_ EBCM_PHS SG_ 1249 VehIdNmDig10_17 1;
BA_REL_ "GenSigTimeoutMsg" BU_SG_REL_ EBCM_PHS SG_ 1249 VehIdNmDig10_17 1249;
BA_REL_ "GenSigTimeoutTime" BU_SG_REL_ EBCM_PHS SG_ 1249 VehIdNmDig10_17 2500;
BA_REL_ "GenSigRxStartValue" BU_SG_REL_ EBOOST_OBD_PHS SG_ 608 AutoPwrChksm "0";
BA_REL_ "GenSigRxStartValue" BU_SG_REL_ EPSb_PHS SG_ 608 AutoPwrChksm "0";
BA_REL_ "GenSigRxStartValue" BU_SG_REL_ EBCM_PHS SG_ 608 AutoPwrChksm "0";
BA_REL_ "GenSigRxStartValue" BU_SG_REL_ EPSa_PHS SG_ 608 AutoPwrChksm "0";
BA_REL_ "GenSigRxStartValue" BU_SG_REL_ EBOOST_OBD_PHS SG_ 608 AutoPwrARC "0";
BA_REL_ "GenSigRxStartValue" BU_SG_REL_ EPSb_PHS SG_ 608 AutoPwrARC "0";
BA_REL_ "GenSigRxStartValue" BU_SG_REL_ EBCM_PHS SG_ 608 AutoPwrARC "0";
BA_REL_ "GenSigRxStartValue" BU_SG_REL_ EPSa_PHS SG_ 608 AutoPwrARC "0";
BA_REL_ "GenSigRxStartValue" BU_SG_REL_ EBOOST_OBD_PHS SG_ 608 AutoPwrLdShdRq "No Load Shedding";
BA_REL_ "GenSigSuprvResp" BU_SG_REL_ EBOOST_OBD_PHS SG_ 608 AutoPwrLdShdRq 1;
BA_REL_ "GenSigTimeoutMsg" BU_SG_REL_ EBOOST_OBD_PHS SG_ 608 AutoPwrLdShdRq 608;
BA_REL_ "GenSigTimeoutTime" BU_SG_REL_ EBOOST_OBD_PHS SG_ 608 AutoPwrLdShdRq 250;
BA_REL_ "GenSigRxStartValue" BU_SG_REL_ EPSb_PHS SG_ 608 AutoPwrLdShdRq "No Load Shedding";
BA_REL_ "GenSigSuprvResp" BU_SG_REL_ EPSb_PHS SG_ 608 AutoPwrLdShdRq 1;
BA_REL_ "GenSigTimeoutMsg" BU_SG_REL_ EPSb_PHS SG_ 608 AutoPwrLdShdRq 608;
BA_REL_ "GenSigTimeoutTime" BU_SG_REL_ EPSb_PHS SG_ 608 AutoPwrLdShdRq 250;
BA_REL_ "GenSigRxStartValue" BU_SG_REL_ EBCM_PHS SG_ 608 AutoPwrLdShdRq "No Load Shedding";
BA_REL_ "GenSigSuprvResp" BU_SG_REL_ EBCM_PHS SG_ 608 AutoPwrLdShdRq 1;
BA_REL_ "GenSigTimeoutMsg" BU_SG_REL_ EBCM_PHS SG_ 608 AutoPwrLdShdRq 608;
BA_REL_ "GenSigTimeoutTime" BU_SG_REL_ EBCM_PHS SG_ 608 AutoPwrLdShdRq 250;
BA_REL_ "GenSigRxStartValue" BU_SG_REL_ EPSa_PHS SG_ 608 AutoPwrLdShdRq "No Load Shedding";
BA_REL_ "GenSigSuprvResp" BU_SG_REL_ EPSa_PHS SG_ 608 AutoPwrLdShdRq 1;
BA_REL_ "GenSigTimeoutMsg" BU_SG_REL_ EPSa_PHS SG_ 608 AutoPwrLdShdRq 608;
BA_REL_ "GenSigTimeoutTime" BU_SG_REL_ EPSa_PHS SG_ 608 AutoPwrLdShdRq 250;
BA_REL_ "GenSigRxStartValue" BU_SG_REL_ EBOOST_OBD_PHS SG_ 1001 DistRollCntAvgDrvnSrc "Transmission Output Speed";
BA_REL_ "GenSigSuprvResp" BU_SG_REL_ EBOOST_OBD_PHS SG_ 1001 DistRollCntAvgDrvnSrc 1;
BA_REL_ "GenSigTimeoutMsg" BU_SG_REL_ EBOOST_OBD_PHS SG_ 1001 DistRollCntAvgDrvnSrc 1001;
BA_REL_ "GenSigTimeoutTime" BU_SG_REL_ EBOOST_OBD_PHS SG_ 1001 DistRollCntAvgDrvnSrc 250;
BA_REL_ "GenSigSuprvResp" BU_SG_REL_ EOCM2cp_IMX6_PHS SG_ 1001 DistRollCntAvgDrvnSrc 1;
BA_REL_ "GenSigTimeoutMsg" BU_SG_REL_ EOCM2cp_IMX6_PHS SG_ 1001 DistRollCntAvgDrvnSrc 1001;
BA_REL_ "GenSigTimeoutTime" BU_SG_REL_ EOCM2cp_IMX6_PHS SG_ 1001 DistRollCntAvgDrvnSrc 1000;
BA_REL_ "GenSigRxStartValue" BU_SG_REL_ EBOOST_OBD_PHS SG_ 1001 VehSpdAvgDrvnSrc "Transmission Output Speed";
BA_REL_ "GenSigSuprvResp" BU_SG_REL_ EBOOST_OBD_PHS SG_ 1001 VehSpdAvgDrvnSrc 1;
BA_REL_ "GenSigTimeoutMsg" BU_SG_REL_ EBOOST_OBD_PHS SG_ 1001 VehSpdAvgDrvnSrc 1001;
BA_REL_ "GenSigTimeoutTime" BU_SG_REL_ EBOOST_OBD_PHS SG_ 1001 VehSpdAvgDrvnSrc 250;
BA_REL_ "GenSigSuprvResp" BU_SG_REL_ EOCM2cp_IMX6_PHS SG_ 1001 VehSpdAvgDrvnSrc 1;
BA_REL_ "GenSigTimeoutMsg" BU_SG_REL_ EOCM2cp_IMX6_PHS SG_ 1001 VehSpdAvgDrvnSrc 1001;
BA_REL_ "GenSigTimeoutTime" BU_SG_REL_ EOCM2cp_IMX6_PHS SG_ 1001 VehSpdAvgDrvnSrc 1000;
BA_REL_ "GenSigRxStartValue" BU_SG_REL_ EBOOST_OBD_PHS SG_ 1001 DstRolCntAvgNonDrvnV "Valid";
BA_REL_ "GenSigRxStartValue" BU_SG_REL_ EBOOST_OBD_PHS SG_ 1001 DstRolCntAvNDrRstOc "False";
BA_REL_ "GenSigSuprvResp" BU_SG_REL_ EBOOST_OBD_PHS SG_ 1001 DstRolCntAvNDrRstOc 1;
BA_REL_ "GenSigTimeoutMsg" BU_SG_REL_ EBOOST_OBD_PHS SG_ 1001 DstRolCntAvNDrRstOc 1001;
BA_REL_ "GenSigTimeoutTime" BU_SG_REL_ EBOOST_OBD_PHS SG_ 1001 DstRolCntAvNDrRstOc 250;
BA_REL_ "GenSigSuprvResp" BU_SG_REL_ EOCM2cp_IMX6_PHS SG_ 1001 DstRolCntAvNDrRstOc 1;
BA_REL_ "GenSigTimeoutMsg" BU_SG_REL_ EOCM2cp_IMX6_PHS SG_ 1001 DstRolCntAvNDrRstOc 1001;
BA_REL_ "GenSigTimeoutTime" BU_SG_REL_ EOCM2cp_IMX6_PHS SG_ 1001 DstRolCntAvNDrRstOc 1000;
BA_REL_ "GenSigVBitResp" BU_SG_REL_ EBOOST_OBD_PHS SG_ 1001 DstRolCntAvgNonDrvn 1;
BA_REL_ "GenSigRxStartValue" BU_SG_REL_ EBOOST_OBD_PHS SG_ 1001 DstRolCntAvgNonDrvn "0";
BA_REL_ "GenSigSuprvResp" BU_SG_REL_ EBOOST_OBD_PHS SG_ 1001 DstRolCntAvgNonDrvn 1;
BA_REL_ "GenSigTimeoutMsg" BU_SG_REL_ EBOOST_OBD_PHS SG_ 1001 DstRolCntAvgNonDrvn 1001;
BA_REL_ "GenSigTimeoutTime" BU_SG_REL_ EBOOST_OBD_PHS SG_ 1001 DstRolCntAvgNonDrvn 250;
BA_REL_ "GenSigSuprvResp" BU_SG_REL_ EOCM2cp_IMX6_PHS SG_ 1001 DstRolCntAvgNonDrvn 1;
BA_REL_ "GenSigTimeoutMsg" BU_SG_REL_ EOCM2cp_IMX6_PHS SG_ 1001 DstRolCntAvgNonDrvn 1001;
BA_REL_ "GenSigTimeoutTime" BU_SG_REL_ EOCM2cp_IMX6_PHS SG_ 1001 DstRolCntAvgNonDrvn 1000;
BA_REL_ "GenSigVBitResp" BU_SG_REL_ EPSb_PHS SG_ 1001 DstRolCntAvgNonDrvn 1;
BA_REL_ "GenSigVBitResp" BU_SG_REL_ EPSa_PHS SG_ 1001 DstRolCntAvgNonDrvn 1;
BA_REL_ "GenSigRxStartValue" BU_SG_REL_ EBOOST_OBD_PHS SG_ 1001 DistRollCntAvgDrvnV "Valid";
BA_REL_ "GenSigRxStartValue" BU_SG_REL_ EBOOST_OBD_PHS SG_ 1001 DstRolCntAvgDrnRstOc "0";
BA_REL_ "GenSigSuprvResp" BU_SG_REL_ EBOOST_OBD_PHS SG_ 1001 DstRolCntAvgDrnRstOc 1;
BA_REL_ "GenSigTimeoutMsg" BU_SG_REL_ EBOOST_OBD_PHS SG_ 1001 DstRolCntAvgDrnRstOc 1001;
BA_REL_ "GenSigTimeoutTime" BU_SG_REL_ EBOOST_OBD_PHS SG_ 1001 DstRolCntAvgDrnRstOc 250;
BA_REL_ "GenSigSuprvResp" BU_SG_REL_ EOCM2cp_IMX6_PHS SG_ 1001 DstRolCntAvgDrnRstOc 1;
BA_REL_ "GenSigTimeoutMsg" BU_SG_REL_ EOCM2cp_IMX6_PHS SG_ 1001 DstRolCntAvgDrnRstOc 1001;
BA_REL_ "GenSigTimeoutTime" BU_SG_REL_ EOCM2cp_IMX6_PHS SG_ 1001 DstRolCntAvgDrnRstOc 1000;
BA_REL_ "GenSigVBitResp" BU_SG_REL_ EBOOST_OBD_PHS SG_ 1001 DistRollCntAvgDrvn 1;
BA_REL_ "GenSigRxStartValue" BU_SG_REL_ EBOOST_OBD_PHS SG_ 1001 DistRollCntAvgDrvn "0";
BA_REL_ "GenSigSuprvResp" BU_SG_REL_ EBOOST_OBD_PHS SG_ 1001 DistRollCntAvgDrvn 1;
BA_REL_ "GenSigTimeoutMsg" BU_SG_REL_ EBOOST_OBD_PHS SG_ 1001 DistRollCntAvgDrvn 1001;
BA_REL_ "GenSigTimeoutTime" BU_SG_REL_ EBOOST_OBD_PHS SG_ 1001 DistRollCntAvgDrvn 250;
BA_REL_ "GenSigVBitResp" BU_SG_REL_ EOCM2cp_IMX6_PHS SG_ 1001 DistRollCntAvgDrvn 1;
BA_REL_ "GenSigSuprvResp" BU_SG_REL_ EOCM2cp_IMX6_PHS SG_ 1001 DistRollCntAvgDrvn 1;
BA_REL_ "GenSigTimeoutMsg" BU_SG_REL_ EOCM2cp_IMX6_PHS SG_ 1001 DistRollCntAvgDrvn 1001;
BA_REL_ "GenSigTimeoutTime" BU_SG_REL_ EOCM2cp_IMX6_PHS SG_ 1001 DistRollCntAvgDrvn 1000;
BA_REL_ "GenSigVBitResp" BU_SG_REL_ EPSb_PHS SG_ 1001 DistRollCntAvgDrvn 1;
BA_REL_ "GenSigVBitResp" BU_SG_REL_ EPSa_PHS SG_ 1001 DistRollCntAvgDrvn 1;
BA_REL_ "GenSigRxStartValue" BU_SG_REL_ EBOOST_OBD_PHS SG_ 1001 VehSpdAvgNDrvnV "Valid";
BA_REL_ "GenSigVBitResp" BU_SG_REL_ EBOOST_OBD_PHS SG_ 1001 VehSpdAvgNDrvn 1;
BA_REL_ "GenSigRxStartValue" BU_SG_REL_ EBOOST_OBD_PHS SG_ 1001 VehSpdAvgNDrvn "0";
BA_REL_ "GenSigSuprvResp" BU_SG_REL_ EBOOST_OBD_PHS SG_ 1001 VehSpdAvgNDrvn 1;
BA_REL_ "GenSigTimeoutMsg" BU_SG_REL_ EBOOST_OBD_PHS SG_ 1001 VehSpdAvgNDrvn 1001;
BA_REL_ "GenSigTimeoutTime" BU_SG_REL_ EBOOST_OBD_PHS SG_ 1001 VehSpdAvgNDrvn 250;
BA_REL_ "GenSigVBitResp" BU_SG_REL_ EPSa_PHS SG_ 1001 VehSpdAvgNDrvn 1;
BA_REL_ "GenSigVBitResp" BU_SG_REL_ EOCM2cp_IMX6_PHS SG_ 1001 VehSpdAvgNDrvn 1;
BA_REL_ "GenSigSuprvResp" BU_SG_REL_ EOCM2cp_IMX6_PHS SG_ 1001 VehSpdAvgNDrvn 1;
BA_REL_ "GenSigTimeoutMsg" BU_SG_REL_ EOCM2cp_IMX6_PHS SG_ 1001 VehSpdAvgNDrvn 1001;
BA_REL_ "GenSigTimeoutTime" BU_SG_REL_ EOCM2cp_IMX6_PHS SG_ 1001 VehSpdAvgNDrvn 1000;
BA_REL_ "GenSigVBitResp" BU_SG_REL_ EPSb_PHS SG_ 1001 VehSpdAvgNDrvn 1;
BA_REL_ "GenSigVBitResp" BU_SG_REL_ EBCM_PHS SG_ 1001 VehSpdAvgNDrvn 1;
BA_REL_ "GenSigSuprvResp" BU_SG_REL_ EBCM_PHS SG_ 1001 VehSpdAvgNDrvn 1;
BA_REL_ "GenSigTimeoutMsg" BU_SG_REL_ EBCM_PHS SG_ 1001 VehSpdAvgNDrvn 1001;
BA_REL_ "GenSigTimeoutTime" BU_SG_REL_ EBCM_PHS SG_ 1001 VehSpdAvgNDrvn 1000;
BA_REL_ "GenSigRxStartValue" BU_SG_REL_ EBOOST_OBD_PHS SG_ 1001 VehSpdAvgDrvnV "Valid";
BA_REL_ "GenSigVBitResp" BU_SG_REL_ EBOOST_OBD_PHS SG_ 1001 VehSpdAvgDrvn 1;
BA_REL_ "GenSigRxStartValue" BU_SG_REL_ EBOOST_OBD_PHS SG_ 1001 VehSpdAvgDrvn "0";
BA_REL_ "GenSigSuprvResp" BU_SG_REL_ EBOOST_OBD_PHS SG_ 1001 VehSpdAvgDrvn 1;
BA_REL_ "GenSigTimeoutMsg" BU_SG_REL_ EBOOST_OBD_PHS SG_ 1001 VehSpdAvgDrvn 1001;
BA_REL_ "GenSigTimeoutTime" BU_SG_REL_ EBOOST_OBD_PHS SG_ 1001 VehSpdAvgDrvn 250;
BA_REL_ "GenSigVBitResp" BU_SG_REL_ EOCM2cp_IMX6_PHS SG_ 1001 VehSpdAvgDrvn 1;
BA_REL_ "GenSigSuprvResp" BU_SG_REL_ EOCM2cp_IMX6_PHS SG_ 1001 VehSpdAvgDrvn 1;
BA_REL_ "GenSigTimeoutMsg" BU_SG_REL_ EOCM2cp_IMX6_PHS SG_ 1001 VehSpdAvgDrvn 1001;
BA_REL_ "GenSigTimeoutTime" BU_SG_REL_ EOCM2cp_IMX6_PHS SG_ 1001 VehSpdAvgDrvn 1000;
BA_REL_ "GenSigVBitResp" BU_SG_REL_ EOCM2cp_K1_PHS SG_ 1001 VehSpdAvgDrvn 1;
BA_REL_ "GenSigSuprvResp" BU_SG_REL_ EOCM2cp_K1_PHS SG_ 1001 VehSpdAvgDrvn 1;
BA_REL_ "GenSigTimeoutMsg" BU_SG_REL_ EOCM2cp_K1_PHS SG_ 1001 VehSpdAvgDrvn 1001;
BA_REL_ "GenSigTimeoutTime" BU_SG_REL_ EOCM2cp_K1_PHS SG_ 1001 VehSpdAvgDrvn 250;
BA_REL_ "GenSigVBitResp" BU_SG_REL_ EPSa_PHS SG_ 1001 VehSpdAvgDrvn 1;
BA_REL_ "GenSigSuprvResp" BU_SG_REL_ EPSa_PHS SG_ 1001 VehSpdAvgDrvn 1;
BA_REL_ "GenSigTimeoutMsg" BU_SG_REL_ EPSa_PHS SG_ 1001 VehSpdAvgDrvn 1001;
BA_REL_ "GenSigTimeoutTime" BU_SG_REL_ EPSa_PHS SG_ 1001 VehSpdAvgDrvn 250;
BA_REL_ "GenSigVBitResp" BU_SG_REL_ EPSb_PHS SG_ 1001 VehSpdAvgDrvn 1;
BA_REL_ "GenSigSuprvResp" BU_SG_REL_ EPSb_PHS SG_ 1001 VehSpdAvgDrvn 1;
BA_REL_ "GenSigTimeoutMsg" BU_SG_REL_ EPSb_PHS SG_ 1001 VehSpdAvgDrvn 1001;
BA_REL_ "GenSigTimeoutTime" BU_SG_REL_ EPSb_PHS SG_ 1001 VehSpdAvgDrvn 250;
BA_REL_ "GenSigVBitResp" BU_SG_REL_ EPSb_PHS SG_ 1009 OtsAirTmpCrVal 1;
BA_REL_ "GenSigSuprvResp" BU_SG_REL_ EPSb_PHS SG_ 1009 OtsAirTmpCrVal 1;
BA_REL_ "GenSigTimeoutMsg" BU_SG_REL_ EPSb_PHS SG_ 1009 OtsAirTmpCrVal 1009;
BA_REL_ "GenSigTimeoutTime" BU_SG_REL_ EPSb_PHS SG_ 1009 OtsAirTmpCrVal 625;
BA_REL_ "GenSigVBitResp" BU_SG_REL_ EPSa_PHS SG_ 1009 OtsAirTmpCrVal 1;
BA_REL_ "GenSigSuprvResp" BU_SG_REL_ EPSa_PHS SG_ 1009 OtsAirTmpCrVal 1;
BA_REL_ "GenSigTimeoutMsg" BU_SG_REL_ EPSa_PHS SG_ 1009 OtsAirTmpCrVal 1009;
BA_REL_ "GenSigTimeoutTime" BU_SG_REL_ EPSa_PHS SG_ 1009 OtsAirTmpCrVal 625;
BA_REL_ "GenSigVBitResp" BU_SG_REL_ EBCM_PHS SG_ 1009 OtsAirTmpCrVal 1;
BA_REL_ "GenSigSuprvResp" BU_SG_REL_ EBCM_PHS SG_ 1009 OtsAirTmpCrVal 1;
BA_REL_ "GenSigTimeoutMsg" BU_SG_REL_ EBCM_PHS SG_ 1009 OtsAirTmpCrVal 1009;
BA_REL_ "GenSigTimeoutTime" BU_SG_REL_ EBCM_PHS SG_ 1009 OtsAirTmpCrVal 625;
BA_REL_ "GenSigSuprvResp" BU_SG_REL_ EBCM_PHS SG_ 1009 EngOffTmExtRng 1;
BA_REL_ "GenSigTimeoutMsg" BU_SG_REL_ EBCM_PHS SG_ 1009 EngOffTmExtRng 1009;
BA_REL_ "GenSigTimeoutTime" BU_SG_REL_ EBCM_PHS SG_ 1009 EngOffTmExtRng 625;
BA_REL_ "GenSigVBitResp" BU_SG_REL_ EPSa_PHS SG_ 1009 EngOffTmExtRng 1;
BA_REL_ "GenSigVBitResp" BU_SG_REL_ EPSb_PHS SG_ 1009 EngOffTmExtRng 1;
BA_REL_ "GenSigVDAFailComment" BU_SG_REL_ EPSb_PHS SG_ 1009 EngOffTmExtRng "Engine Off Time VDA";
BA_REL_ "GenSigVDAFailResp" BU_SG_REL_ EPSb_PHS SG_ 1009 EngOffTmExtRng 1;
BA_REL_ "GenSigSuprvResp" BU_SG_REL_ EBCM_PHS SG_ 201 Eng12vStrtrMtrCmmdOn 1;
BA_REL_ "GenSigTimeoutMsg" BU_SG_REL_ EBCM_PHS SG_ 201 Eng12vStrtrMtrCmmdOn 201;
BA_REL_ "GenSigTimeoutTime" BU_SG_REL_ EBCM_PHS SG_ 201 Eng12vStrtrMtrCmmdOn 250;
BA_REL_ "GenSigSuprvResp" BU_SG_REL_ EBCM_PHS SG_ 201 Eng12vStrtrMtrCmmdOn 1;
BA_REL_ "GenSigTimeoutMsg" BU_SG_REL_ EBCM_PHS SG_ 201 Eng12vStrtrMtrCmmdOn 201;
BA_REL_ "GenSigTimeoutTime" BU_SG_REL_ EBCM_PHS SG_ 201 Eng12vStrtrMtrCmmdOn 250;
BA_REL_ "GenSigSuprvResp" BU_SG_REL_ EPSb_PHS SG_ 201 Eng12vStrtrMtrCmmdOn 1;
BA_REL_ "GenSigTimeoutMsg" BU_SG_REL_ EPSb_PHS SG_ 201 Eng12vStrtrMtrCmmdOn 201;
BA_REL_ "GenSigTimeoutTime" BU_SG_REL_ EPSb_PHS SG_ 201 Eng12vStrtrMtrCmmdOn 250;
BA_REL_ "GenSigSuprvResp" BU_SG_REL_ EPSa_PHS SG_ 201 Eng12vStrtrMtrCmmdOn 1;
BA_REL_ "GenSigTimeoutMsg" BU_SG_REL_ EPSa_PHS SG_ 201 Eng12vStrtrMtrCmmdOn 201;
BA_REL_ "GenSigTimeoutTime" BU_SG_REL_ EPSa_PHS SG_ 201 Eng12vStrtrMtrCmmdOn 250;
BA_REL_ "GenSigSuprvResp" BU_SG_REL_ EBOOST_OBD_PHS SG_ 201 EngCntrlRunCrnkTrmSt 1;
BA_REL_ "GenSigTimeoutMsg" BU_SG_REL_ EBOOST_OBD_PHS SG_ 201 EngCntrlRunCrnkTrmSt 201;
BA_REL_ "GenSigTimeoutTime" BU_SG_REL_ EBOOST_OBD_PHS SG_ 201 EngCntrlRunCrnkTrmSt 250;
BA_REL_ "GenSigSuprvResp" BU_SG_REL_ EBCM_PHS SG_ 201 EngCntrlRunCrnkTrmSt 1;
BA_REL_ "GenSigTimeoutMsg" BU_SG_REL_ EBCM_PHS SG_ 201 EngCntrlRunCrnkTrmSt 201;
BA_REL_ "GenSigTimeoutTime" BU_SG_REL_ EBCM_PHS SG_ 201 EngCntrlRunCrnkTrmSt 250;
BA_REL_ "GenSigSuprvResp" BU_SG_REL_ EBCM_PHS SG_ 201 EngCntrlRunCrnkTrmSt 1;
BA_REL_ "GenSigTimeoutMsg" BU_SG_REL_ EBCM_PHS SG_ 201 EngCntrlRunCrnkTrmSt 201;
BA_REL_ "GenSigTimeoutTime" BU_SG_REL_ EBCM_PHS SG_ 201 EngCntrlRunCrnkTrmSt 250;
BA_REL_ "GenSigVBitResp" BU_SG_REL_ EBCM_PHS SG_ 201 EngAirIntBstPr 1;
BA_REL_ "GenSigSuprvResp" BU_SG_REL_ EBCM_PHS SG_ 201 EngAirIntBstPr 1;
BA_REL_ "GenSigTimeoutMsg" BU_SG_REL_ EBCM_PHS SG_ 201 EngAirIntBstPr 201;
BA_REL_ "GenSigTimeoutTime" BU_SG_REL_ EBCM_PHS SG_ 201 EngAirIntBstPr 250;
BA_REL_ "GenSigRxStartValue" BU_SG_REL_ EBCM_PHS SG_ 201 RmVhStrtEngRng "False";
BA_REL_ "GenSigSuprvResp" BU_SG_REL_ EBCM_PHS SG_ 201 RmVhStrtEngRng 1;
BA_REL_ "GenSigTimeoutMsg" BU_SG_REL_ EBCM_PHS SG_ 201 RmVhStrtEngRng 201;
BA_REL_ "GenSigTimeoutTime" BU_SG_REL_ EBCM_PHS SG_ 201 RmVhStrtEngRng 250;
BA_REL_ "GenSigSuprvResp" BU_SG_REL_ EBCM_PHS SG_ 201 PT_BrkPedDscrtInpStat 1;
BA_REL_ "GenSigTimeoutMsg" BU_SG_REL_ EBCM_PHS SG_ 201 PT_BrkPedDscrtInpStat 201;
BA_REL_ "GenSigTimeoutTime" BU_SG_REL_ EBCM_PHS SG_ 201 PT_BrkPedDscrtInpStat 250;
BA_REL_ "GenSigVBitResp" BU_SG_REL_ EBCM_PHS SG_ 201 PT_BrkPedDscrtInpStat 1;
BA_REL_ "GenSigSuprvResp" BU_SG_REL_ EBCM_PHS SG_ 201 PT_BrkPedDscrtInpStat 1;
BA_REL_ "GenSigTimeoutMsg" BU_SG_REL_ EBCM_PHS SG_ 201 PT_BrkPedDscrtInpStat 201;
BA_REL_ "GenSigTimeoutTime" BU_SG_REL_ EBCM_PHS SG_ 201 PT_BrkPedDscrtInpStat 250;
BA_REL_ "GenSigSuprvResp" BU_SG_REL_ EBCM_PHS SG_ 201 AccActPos 1;
BA_REL_ "GenSigTimeoutMsg" BU_SG_REL_ EBCM_PHS SG_ 201 AccActPos 201;
BA_REL_ "GenSigTimeoutTime" BU_SG_REL_ EBCM_PHS SG_ 201 AccActPos 250;
BA_REL_ "GenSigVBitResp" BU_SG_REL_ EBCM_PHS SG_ 201 AccActPos 1;
BA_REL_ "GenSigTimeoutMsg" BU_SG_REL_ EBCM_PHS SG_ 201 AccActPos 201;
BA_REL_ "GenSigTimeoutTime" BU_SG_REL_ EBCM_PHS SG_ 201 AccActPos 250;
BA_REL_ "GenSigSuprvResp" BU_SG_REL_ EBCM_PHS SG_ 201 CrsCntAtv 1;
BA_REL_ "GenSigTimeoutMsg" BU_SG_REL_ EBCM_PHS SG_ 201 CrsCntAtv 201;
BA_REL_ "GenSigTimeoutTime" BU_SG_REL_ EBCM_PHS SG_ 201 CrsCntAtv 250;
BA_REL_ "GenSigSuprvResp" BU_SG_REL_ EBCM_PHS SG_ 201 DrvThrottlOvrrdDet 1;
BA_REL_ "GenSigTimeoutMsg" BU_SG_REL_ EBCM_PHS SG_ 201 DrvThrottlOvrrdDet 201;
BA_REL_ "GenSigTimeoutTime" BU_SG_REL_ EBCM_PHS SG_ 201 DrvThrottlOvrrdDet 250;
BA_REL_ "GenSigSuprvResp" BU_SG_REL_ EBCM_PHS SG_ 201 PT_CrnkAct 1;
BA_REL_ "GenSigTimeoutMsg" BU_SG_REL_ EBCM_PHS SG_ 201 PT_CrnkAct 201;
BA_REL_ "GenSigTimeoutTime" BU_SG_REL_ EBCM_PHS SG_ 201 PT_CrnkAct 250;
BA_REL_ "GenSigSuprvResp" BU_SG_REL_ EBCM_PHS SG_ 201 PT_CrnkAct 1;
BA_REL_ "GenSigTimeoutMsg" BU_SG_REL_ EBCM_PHS SG_ 201 PT_CrnkAct 201;
BA_REL_ "GenSigTimeoutTime" BU_SG_REL_ EBCM_PHS SG_ 201 PT_CrnkAct 250;
BA_REL_ "GenSigSuprvResp" BU_SG_REL_ EPSb_PHS SG_ 201 PT_CrnkAct 1;
BA_REL_ "GenSigTimeoutMsg" BU_SG_REL_ EPSb_PHS SG_ 201 PT_CrnkAct 201;
BA_REL_ "GenSigTimeoutTime" BU_SG_REL_ EPSb_PHS SG_ 201 PT_CrnkAct 250;
BA_REL_ "GenSigSuprvResp" BU_SG_REL_ EPSa_PHS SG_ 201 PT_CrnkAct 1;
BA_REL_ "GenSigTimeoutMsg" BU_SG_REL_ EPSa_PHS SG_ 201 PT_CrnkAct 201;
BA_REL_ "GenSigTimeoutTime" BU_SG_REL_ EPSa_PHS SG_ 201 PT_CrnkAct 250;
BA_REL_ "GenSigSuprvResp" BU_SG_REL_ EBCM_PHS SG_ 201 EngSpdStat 1;
BA_REL_ "GenSigTimeoutMsg" BU_SG_REL_ EBCM_PHS SG_ 201 EngSpdStat 201;
BA_REL_ "GenSigTimeoutTime" BU_SG_REL_ EBCM_PHS SG_ 201 EngSpdStat 250;
BA_REL_ "GenSigSuprvResp" BU_SG_REL_ EBCM_PHS SG_ 201 EngSpdStat 1;
BA_REL_ "GenSigTimeoutMsg" BU_SG_REL_ EBCM_PHS SG_ 201 EngSpdStat 201;
BA_REL_ "GenSigTimeoutTime" BU_SG_REL_ EBCM_PHS SG_ 201 EngSpdStat 250;
BA_REL_ "GenSigSuprvResp" BU_SG_REL_ EPSb_PHS SG_ 201 EngSpdStat 1;
BA_REL_ "GenSigTimeoutMsg" BU_SG_REL_ EPSb_PHS SG_ 201 EngSpdStat 201;
BA_REL_ "GenSigTimeoutTime" BU_SG_REL_ EPSb_PHS SG_ 201 EngSpdStat 250;
BA_REL_ "GenSigSuprvResp" BU_SG_REL_ EPSa_PHS SG_ 201 EngSpdStat 1;
BA_REL_ "GenSigTimeoutMsg" BU_SG_REL_ EPSa_PHS SG_ 201 EngSpdStat 201;
BA_REL_ "GenSigTimeoutTime" BU_SG_REL_ EPSa_PHS SG_ 201 EngSpdStat 250;
BA_REL_ "GenSigSuprvResp" BU_SG_REL_ EBCM_PHS SG_ 201 EngSpd 1;
BA_REL_ "GenSigTimeoutMsg" BU_SG_REL_ EBCM_PHS SG_ 201 EngSpd 201;
BA_REL_ "GenSigTimeoutTime" BU_SG_REL_ EBCM_PHS SG_ 201 EngSpd 250;
BA_REL_ "GenSigSuprvResp" BU_SG_REL_ EBCM_PHS SG_ 201 EngSpd 1;
BA_REL_ "GenSigTimeoutMsg" BU_SG_REL_ EBCM_PHS SG_ 201 EngSpd 201;
BA_REL_ "GenSigTimeoutTime" BU_SG_REL_ EBCM_PHS SG_ 201 EngSpd 250;
BA_REL_ "GenSigSuprvResp" BU_SG_REL_ EPSb_PHS SG_ 201 EngSpd 1;
BA_REL_ "GenSigTimeoutMsg" BU_SG_REL_ EPSb_PHS SG_ 201 EngSpd 201;
BA_REL_ "GenSigTimeoutTime" BU_SG_REL_ EPSb_PHS SG_ 201 EngSpd 250;
BA_REL_ "GenSigSuprvResp" BU_SG_REL_ EPSa_PHS SG_ 201 EngSpd 1;
BA_REL_ "GenSigTimeoutMsg" BU_SG_REL_ EPSa_PHS SG_ 201 EngSpd 201;
BA_REL_ "GenSigTimeoutTime" BU_SG_REL_ EPSa_PHS SG_ 201 EngSpd 250;
BA_REL_ "GenSigSuprvResp" BU_SG_REL_ EBCM_PHS SG_ 201 EngRunAtv 1;
BA_REL_ "GenSigTimeoutMsg" BU_SG_REL_ EBCM_PHS SG_ 201 EngRunAtv 201;
BA_REL_ "GenSigTimeoutTime" BU_SG_REL_ EBCM_PHS SG_ 201 EngRunAtv 250;
BA_REL_ "GenSigSuprvResp" BU_SG_REL_ EPSb_PHS SG_ 201 EngRunAtv 1;
BA_REL_ "GenSigTimeoutMsg" BU_SG_REL_ EPSb_PHS SG_ 201 EngRunAtv 201;
BA_REL_ "GenSigTimeoutTime" BU_SG_REL_ EPSb_PHS SG_ 201 EngRunAtv 250;
BA_REL_ "GenSigSuprvResp" BU_SG_REL_ EPSa_PHS SG_ 201 EngRunAtv 1;
BA_REL_ "GenSigTimeoutMsg" BU_SG_REL_ EPSa_PHS SG_ 201 EngRunAtv 201;
BA_REL_ "GenSigTimeoutTime" BU_SG_REL_ EPSa_PHS SG_ 201 EngRunAtv 250;
BA_REL_ "GenSigRxStartValue" BU_SG_REL_ EPSb_PHS SG_ 842 NDrvnWhlGrndVelChksm "0";
BA_REL_ "GenSigRxStartValue" BU_SG_REL_ EPSa_PHS SG_ 842 NDrvnWhlGrndVelChksm "0";
BA_REL_ "GenSigRxStartValue" BU_SG_REL_ EBOOST_OBD_PHS SG_ 842 NDrvnWhlGrndVelChksm "0";
BA_REL_ "GenSigRxStartValue" BU_SG_REL_ EPSb_PHS SG_ 842 NDrvnWhlGrndVelARC "0";
BA_REL_ "GenSigRxStartValue" BU_SG_REL_ EPSa_PHS SG_ 842 NDrvnWhlGrndVelARC "0";
BA_REL_ "GenSigRxStartValue" BU_SG_REL_ EBOOST_OBD_PHS SG_ 842 NDrvnWhlGrndVelARC "0";
BA_REL_ "GenSigRxStartValue" BU_SG_REL_ EBOOST_OBD_PHS SG_ 842 WhlRotDrctnlSRtNDrvn "Unknown";
BA_REL_ "GenSigSuprvResp" BU_SG_REL_ EBOOST_OBD_PHS SG_ 842 WhlRotDrctnlSRtNDrvn 1;
BA_REL_ "GenSigTimeoutMsg" BU_SG_REL_ EBOOST_OBD_PHS SG_ 842 WhlRotDrctnlSRtNDrvn 842;
BA_REL_ "GenSigTimeoutTime" BU_SG_REL_ EBOOST_OBD_PHS SG_ 842 WhlRotDrctnlSRtNDrvn 125;
BA_REL_ "GenSigSuprvResp" BU_SG_REL_ EPSb_PHS SG_ 842 WhlRotDrctnlSRtNDrvn 1;
BA_REL_ "GenSigTimeoutMsg" BU_SG_REL_ EPSb_PHS SG_ 842 WhlRotDrctnlSRtNDrvn 842;
BA_REL_ "GenSigTimeoutTime" BU_SG_REL_ EPSb_PHS SG_ 842 WhlRotDrctnlSRtNDrvn 250;
BA_REL_ "GenSigSuprvResp" BU_SG_REL_ EPSa_PHS SG_ 842 WhlRotDrctnlSRtNDrvn 1;
BA_REL_ "GenSigTimeoutMsg" BU_SG_REL_ EPSa_PHS SG_ 842 WhlRotDrctnlSRtNDrvn 842;
BA_REL_ "GenSigTimeoutTime" BU_SG_REL_ EPSa_PHS SG_ 842 WhlRotDrctnlSRtNDrvn 250;
BA_REL_ "GenSigRxStartValue" BU_SG_REL_ EBOOST_OBD_PHS SG_ 842 WhlRotDrctnlStLfNDrvn "Unknown";
BA_REL_ "GenSigSuprvResp" BU_SG_REL_ EBOOST_OBD_PHS SG_ 842 WhlRotDrctnlStLfNDrvn 1;
BA_REL_ "GenSigTimeoutMsg" BU_SG_REL_ EBOOST_OBD_PHS SG_ 842 WhlRotDrctnlStLfNDrvn 842;
BA_REL_ "GenSigTimeoutTime" BU_SG_REL_ EBOOST_OBD_PHS SG_ 842 WhlRotDrctnlStLfNDrvn 125;
BA_REL_ "GenSigSuprvResp" BU_SG_REL_ EPSb_PHS SG_ 842 WhlRotDrctnlStLfNDrvn 1;
BA_REL_ "GenSigTimeoutMsg" BU_SG_REL_ EPSb_PHS SG_ 842 WhlRotDrctnlStLfNDrvn 842;
BA_REL_ "GenSigTimeoutTime" BU_SG_REL_ EPSb_PHS SG_ 842 WhlRotDrctnlStLfNDrvn 250;
BA_REL_ "GenSigSuprvResp" BU_SG_REL_ EPSa_PHS SG_ 842 WhlRotDrctnlStLfNDrvn 1;
BA_REL_ "GenSigTimeoutMsg" BU_SG_REL_ EPSa_PHS SG_ 842 WhlRotDrctnlStLfNDrvn 842;
BA_REL_ "GenSigTimeoutTime" BU_SG_REL_ EPSa_PHS SG_ 842 WhlRotDrctnlStLfNDrvn 250;
BA_REL_ "GenSigRxStartValue" BU_SG_REL_ EBOOST_OBD_PHS SG_ 842 WhlGrndVlctyRtNnDrvnV "Valid";
BA_REL_ "GenSigVBitResp" BU_SG_REL_ EBOOST_OBD_PHS SG_ 842 WhlGrndVlctyRtNnDrvn 1;
BA_REL_ "GenSigRxStartValue" BU_SG_REL_ EBOOST_OBD_PHS SG_ 842 WhlGrndVlctyRtNnDrvn "0";
BA_REL_ "GenSigSuprvResp" BU_SG_REL_ EBOOST_OBD_PHS SG_ 842 WhlGrndVlctyRtNnDrvn 1;
BA_REL_ "GenSigTimeoutMsg" BU_SG_REL_ EBOOST_OBD_PHS SG_ 842 WhlGrndVlctyRtNnDrvn 842;
BA_REL_ "GenSigTimeoutTime" BU_SG_REL_ EBOOST_OBD_PHS SG_ 842 WhlGrndVlctyRtNnDrvn 125;
BA_REL_ "GenSigVBitResp" BU_SG_REL_ EPSa_PHS SG_ 842 WhlGrndVlctyRtNnDrvn 1;
BA_REL_ "GenSigSuprvResp" BU_SG_REL_ EPSa_PHS SG_ 842 WhlGrndVlctyRtNnDrvn 1;
BA_REL_ "GenSigTimeoutMsg" BU_SG_REL_ EPSa_PHS SG_ 842 WhlGrndVlctyRtNnDrvn 842;
BA_REL_ "GenSigTimeoutTime" BU_SG_REL_ EPSa_PHS SG_ 842 WhlGrndVlctyRtNnDrvn 250;
BA_REL_ "GenSigVBitResp" BU_SG_REL_ EPSb_PHS SG_ 842 WhlGrndVlctyRtNnDrvn 1;
BA_REL_ "GenSigSuprvResp" BU_SG_REL_ EPSb_PHS SG_ 842 WhlGrndVlctyRtNnDrvn 1;
BA_REL_ "GenSigTimeoutMsg" BU_SG_REL_ EPSb_PHS SG_ 842 WhlGrndVlctyRtNnDrvn 842;
BA_REL_ "GenSigTimeoutTime" BU_SG_REL_ EPSb_PHS SG_ 842 WhlGrndVlctyRtNnDrvn 250;
BA_REL_ "GenSigRxStartValue" BU_SG_REL_ EBOOST_OBD_PHS SG_ 842 WhlGrndVlctyLftNnDrvnV "Valid";
BA_REL_ "GenSigVBitResp" BU_SG_REL_ EBOOST_OBD_PHS SG_ 842 WhlGrndVlctyLftNnDrvn 1;
BA_REL_ "GenSigRxStartValue" BU_SG_REL_ EBOOST_OBD_PHS SG_ 842 WhlGrndVlctyLftNnDrvn "0";
BA_REL_ "GenSigSuprvResp" BU_SG_REL_ EBOOST_OBD_PHS SG_ 842 WhlGrndVlctyLftNnDrvn 1;
BA_REL_ "GenSigTimeoutMsg" BU_SG_REL_ EBOOST_OBD_PHS SG_ 842 WhlGrndVlctyLftNnDrvn 842;
BA_REL_ "GenSigTimeoutTime" BU_SG_REL_ EBOOST_OBD_PHS SG_ 842 WhlGrndVlctyLftNnDrvn 125;
BA_REL_ "GenSigVBitResp" BU_SG_REL_ EPSa_PHS SG_ 842 WhlGrndVlctyLftNnDrvn 1;
BA_REL_ "GenSigSuprvResp" BU_SG_REL_ EPSa_PHS SG_ 842 WhlGrndVlctyLftNnDrvn 1;
BA_REL_ "GenSigTimeoutMsg" BU_SG_REL_ EPSa_PHS SG_ 842 WhlGrndVlctyLftNnDrvn 842;
BA_REL_ "GenSigTimeoutTime" BU_SG_REL_ EPSa_PHS SG_ 842 WhlGrndVlctyLftNnDrvn 250;
BA_REL_ "GenSigVBitResp" BU_SG_REL_ EPSb_PHS SG_ 842 WhlGrndVlctyLftNnDrvn 1;
BA_REL_ "GenSigSuprvResp" BU_SG_REL_ EPSb_PHS SG_ 842 WhlGrndVlctyLftNnDrvn 1;
BA_REL_ "GenSigTimeoutMsg" BU_SG_REL_ EPSb_PHS SG_ 842 WhlGrndVlctyLftNnDrvn 842;
BA_REL_ "GenSigTimeoutTime" BU_SG_REL_ EPSb_PHS SG_ 842 WhlGrndVlctyLftNnDrvn 250;
BA_REL_ "GenSigRxStartValue" BU_SG_REL_ EPSb_PHS SG_ 840 DrvnWhlGrndVelChksm "0";
BA_REL_ "GenSigRxStartValue" BU_SG_REL_ EPSa_PHS SG_ 840 DrvnWhlGrndVelChksm "0";
BA_REL_ "GenSigRxStartValue" BU_SG_REL_ EBOOST_OBD_PHS SG_ 840 DrvnWhlGrndVelChksm "0";
BA_REL_ "GenSigRxStartValue" BU_SG_REL_ EBOOST_OBD_PHS SG_ 840 WhlRotDrctnlStLftDrvn "Unknown";
BA_REL_ "GenSigSuprvResp" BU_SG_REL_ EBOOST_OBD_PHS SG_ 840 WhlRotDrctnlStLftDrvn 1;
BA_REL_ "GenSigTimeoutMsg" BU_SG_REL_ EBOOST_OBD_PHS SG_ 840 WhlRotDrctnlStLftDrvn 840;
BA_REL_ "GenSigTimeoutTime" BU_SG_REL_ EBOOST_OBD_PHS SG_ 840 WhlRotDrctnlStLftDrvn 125;
BA_REL_ "GenSigSuprvResp" BU_SG_REL_ EPSb_PHS SG_ 840 WhlRotDrctnlStLftDrvn 1;
BA_REL_ "GenSigTimeoutMsg" BU_SG_REL_ EPSb_PHS SG_ 840 WhlRotDrctnlStLftDrvn 840;
BA_REL_ "GenSigTimeoutTime" BU_SG_REL_ EPSb_PHS SG_ 840 WhlRotDrctnlStLftDrvn 250;
BA_REL_ "GenSigSuprvResp" BU_SG_REL_ EPSa_PHS SG_ 840 WhlRotDrctnlStLftDrvn 1;
BA_REL_ "GenSigTimeoutMsg" BU_SG_REL_ EPSa_PHS SG_ 840 WhlRotDrctnlStLftDrvn 840;
BA_REL_ "GenSigTimeoutTime" BU_SG_REL_ EPSa_PHS SG_ 840 WhlRotDrctnlStLftDrvn 250;
BA_REL_ "GenSigRxStartValue" BU_SG_REL_ EBOOST_OBD_PHS SG_ 840 WhlRotDrctnlStRtDrvn "Unknown";
BA_REL_ "GenSigSuprvResp" BU_SG_REL_ EBOOST_OBD_PHS SG_ 840 WhlRotDrctnlStRtDrvn 1;
BA_REL_ "GenSigTimeoutMsg" BU_SG_REL_ EBOOST_OBD_PHS SG_ 840 WhlRotDrctnlStRtDrvn 840;
BA_REL_ "GenSigTimeoutTime" BU_SG_REL_ EBOOST_OBD_PHS SG_ 840 WhlRotDrctnlStRtDrvn 125;
BA_REL_ "GenSigSuprvResp" BU_SG_REL_ EPSb_PHS SG_ 840 WhlRotDrctnlStRtDrvn 1;
BA_REL_ "GenSigTimeoutMsg" BU_SG_REL_ EPSb_PHS SG_ 840 WhlRotDrctnlStRtDrvn 840;
BA_REL_ "GenSigTimeoutTime" BU_SG_REL_ EPSb_PHS SG_ 840 WhlRotDrctnlStRtDrvn 250;
BA_REL_ "GenSigSuprvResp" BU_SG_REL_ EPSa_PHS SG_ 840 WhlRotDrctnlStRtDrvn 1;
BA_REL_ "GenSigTimeoutMsg" BU_SG_REL_ EPSa_PHS SG_ 840 WhlRotDrctnlStRtDrvn 840;
BA_REL_ "GenSigTimeoutTime" BU_SG_REL_ EPSa_PHS SG_ 840 WhlRotDrctnlStRtDrvn 250;
BA_REL_ "GenSigRxStartValue" BU_SG_REL_ EBOOST_OBD_PHS SG_ 840 WhlGrndVlctyRtDrvnV "Valid";
BA_REL_ "GenSigVBitResp" BU_SG_REL_ EBOOST_OBD_PHS SG_ 840 WhlGrndVlctyRtDrvn 1;
BA_REL_ "GenSigRxStartValue" BU_SG_REL_ EBOOST_OBD_PHS SG_ 840 WhlGrndVlctyRtDrvn "0";
BA_REL_ "GenSigSuprvResp" BU_SG_REL_ EBOOST_OBD_PHS SG_ 840 WhlGrndVlctyRtDrvn 1;
BA_REL_ "GenSigTimeoutMsg" BU_SG_REL_ EBOOST_OBD_PHS SG_ 840 WhlGrndVlctyRtDrvn 840;
BA_REL_ "GenSigTimeoutTime" BU_SG_REL_ EBOOST_OBD_PHS SG_ 840 WhlGrndVlctyRtDrvn 125;
BA_REL_ "GenSigVBitResp" BU_SG_REL_ EPSa_PHS SG_ 840 WhlGrndVlctyRtDrvn 1;
BA_REL_ "GenSigSuprvResp" BU_SG_REL_ EPSa_PHS SG_ 840 WhlGrndVlctyRtDrvn 1;
BA_REL_ "GenSigTimeoutMsg" BU_SG_REL_ EPSa_PHS SG_ 840 WhlGrndVlctyRtDrvn 840;
BA_REL_ "GenSigTimeoutTime" BU_SG_REL_ EPSa_PHS SG_ 840 WhlGrndVlctyRtDrvn 250;
BA_REL_ "GenSigVBitResp" BU_SG_REL_ EPSb_PHS SG_ 840 WhlGrndVlctyRtDrvn 1;
BA_REL_ "GenSigSuprvResp" BU_SG_REL_ EPSb_PHS SG_ 840 WhlGrndVlctyRtDrvn 1;
BA_REL_ "GenSigTimeoutMsg" BU_SG_REL_ EPSb_PHS SG_ 840 WhlGrndVlctyRtDrvn 840;
BA_REL_ "GenSigTimeoutTime" BU_SG_REL_ EPSb_PHS SG_ 840 WhlGrndVlctyRtDrvn 250;
BA_REL_ "GenSigRxStartValue" BU_SG_REL_ EBOOST_OBD_PHS SG_ 840 WhlGrndVlctyLftDrvnV "Valid";
BA_REL_ "GenSigVBitResp" BU_SG_REL_ EBOOST_OBD_PHS SG_ 840 WhlGrndVlctyLftDrvn 1;
BA_REL_ "GenSigRxStartValue" BU_SG_REL_ EBOOST_OBD_PHS SG_ 840 WhlGrndVlctyLftDrvn "0";
BA_REL_ "GenSigSuprvResp" BU_SG_REL_ EBOOST_OBD_PHS SG_ 840 WhlGrndVlctyLftDrvn 1;
BA_REL_ "GenSigTimeoutMsg" BU_SG_REL_ EBOOST_OBD_PHS SG_ 840 WhlGrndVlctyLftDrvn 840;
BA_REL_ "GenSigTimeoutTime" BU_SG_REL_ EBOOST_OBD_PHS SG_ 840 WhlGrndVlctyLftDrvn 125;
BA_REL_ "GenSigVBitResp" BU_SG_REL_ EPSa_PHS SG_ 840 WhlGrndVlctyLftDrvn 1;
BA_REL_ "GenSigSuprvResp" BU_SG_REL_ EPSa_PHS SG_ 840 WhlGrndVlctyLftDrvn 1;
BA_REL_ "GenSigTimeoutMsg" BU_SG_REL_ EPSa_PHS SG_ 840 WhlGrndVlctyLftDrvn 840;
BA_REL_ "GenSigTimeoutTime" BU_SG_REL_ EPSa_PHS SG_ 840 WhlGrndVlctyLftDrvn 250;
BA_REL_ "GenSigVBitResp" BU_SG_REL_ EPSb_PHS SG_ 840 WhlGrndVlctyLftDrvn 1;
BA_REL_ "GenSigSuprvResp" BU_SG_REL_ EPSb_PHS SG_ 840 WhlGrndVlctyLftDrvn 1;
BA_REL_ "GenSigTimeoutMsg" BU_SG_REL_ EPSb_PHS SG_ 840 WhlGrndVlctyLftDrvn 840;
BA_REL_ "GenSigTimeoutTime" BU_SG_REL_ EPSb_PHS SG_ 840 WhlGrndVlctyLftDrvn 250;
BA_REL_ "GenSigRxStartValue" BU_SG_REL_ EPSb_PHS SG_ 840 DrvnWhlGrndVelARC "0";
BA_REL_ "GenSigRxStartValue" BU_SG_REL_ EPSa_PHS SG_ 840 DrvnWhlGrndVelARC "0";
BA_REL_ "GenSigRxStartValue" BU_SG_REL_ EBOOST_OBD_PHS SG_ 840 DrvnWhlGrndVelARC "0";
BA_REL_ "GenSigSuprvResp" BU_SG_REL_ EBOOST_OBD_PHS SG_ 497 SysBkupPwrMdEn 1;
BA_REL_ "GenSigTimeoutMsg" BU_SG_REL_ EBOOST_OBD_PHS SG_ 497 SysBkupPwrMdEn 497;
BA_REL_ "GenSigTimeoutTime" BU_SG_REL_ EBOOST_OBD_PHS SG_ 497 SysBkupPwrMdEn 500;
BA_REL_ "GenSigSuprvResp" BU_SG_REL_ EOCM2cp_K1_PHS SG_ 497 SysBkupPwrMdEn 1;
BA_REL_ "GenSigTimeoutMsg" BU_SG_REL_ EOCM2cp_K1_PHS SG_ 497 SysBkupPwrMdEn 497;
BA_REL_ "GenSigTimeoutTime" BU_SG_REL_ EOCM2cp_K1_PHS SG_ 497 SysBkupPwrMdEn 500;
BA_REL_ "GenSigSuprvResp" BU_SG_REL_ EPSb_PHS SG_ 497 SysBkupPwrMdEn 1;
BA_REL_ "GenSigTimeoutMsg" BU_SG_REL_ EPSb_PHS SG_ 497 SysBkupPwrMdEn 497;
BA_REL_ "GenSigTimeoutTime" BU_SG_REL_ EPSb_PHS SG_ 497 SysBkupPwrMdEn 500;
BA_REL_ "GenSigSuprvResp" BU_SG_REL_ EPSa_PHS SG_ 497 SysBkupPwrMdEn 1;
BA_REL_ "GenSigTimeoutMsg" BU_SG_REL_ EPSa_PHS SG_ 497 SysBkupPwrMdEn 497;
BA_REL_ "GenSigTimeoutTime" BU_SG_REL_ EPSa_PHS SG_ 497 SysBkupPwrMdEn 500;
BA_REL_ "GenSigSuprvResp" BU_SG_REL_ EBCM_PHS SG_ 497 SysBkupPwrMdEn 1;
BA_REL_ "GenSigTimeoutMsg" BU_SG_REL_ EBCM_PHS SG_ 497 SysBkupPwrMdEn 497;
BA_REL_ "GenSigTimeoutTime" BU_SG_REL_ EBCM_PHS SG_ 497 SysBkupPwrMdEn 250;
BA_REL_ "GenSigSuprvResp" BU_SG_REL_ EOCM2cp_IMX6_PHS SG_ 497 SysBkupPwrMdEn 1;
BA_REL_ "GenSigTimeoutMsg" BU_SG_REL_ EOCM2cp_IMX6_PHS SG_ 497 SysBkupPwrMdEn 497;
BA_REL_ "GenSigTimeoutTime" BU_SG_REL_ EOCM2cp_IMX6_PHS SG_ 497 SysBkupPwrMdEn 500;
BA_REL_ "GenSigSuprvResp" BU_SG_REL_ EBOOST_OBD_PHS SG_ 497 SysBkUpPwrMd 1;
BA_REL_ "GenSigTimeoutMsg" BU_SG_REL_ EBOOST_OBD_PHS SG_ 497 SysBkUpPwrMd 497;
BA_REL_ "GenSigTimeoutTime" BU_SG_REL_ EBOOST_OBD_PHS SG_ 497 SysBkUpPwrMd 500;
BA_REL_ "GenSigSuprvResp" BU_SG_REL_ EOCM2cp_K1_PHS SG_ 497 SysBkUpPwrMd 1;
BA_REL_ "GenSigTimeoutMsg" BU_SG_REL_ EOCM2cp_K1_PHS SG_ 497 SysBkUpPwrMd 497;
BA_REL_ "GenSigTimeoutTime" BU_SG_REL_ EOCM2cp_K1_PHS SG_ 497 SysBkUpPwrMd 500;
BA_REL_ "GenSigSuprvResp" BU_SG_REL_ EPSb_PHS SG_ 497 SysBkUpPwrMd 1;
BA_REL_ "GenSigTimeoutMsg" BU_SG_REL_ EPSb_PHS SG_ 497 SysBkUpPwrMd 497;
BA_REL_ "GenSigTimeoutTime" BU_SG_REL_ EPSb_PHS SG_ 497 SysBkUpPwrMd 500;
BA_REL_ "GenSigSuprvResp" BU_SG_REL_ EPSa_PHS SG_ 497 SysBkUpPwrMd 1;
BA_REL_ "GenSigTimeoutMsg" BU_SG_REL_ EPSa_PHS SG_ 497 SysBkUpPwrMd 497;
BA_REL_ "GenSigTimeoutTime" BU_SG_REL_ EPSa_PHS SG_ 497 SysBkUpPwrMd 500;
BA_REL_ "GenSigSuprvResp" BU_SG_REL_ EBCM_PHS SG_ 497 SysBkUpPwrMd 1;
BA_REL_ "GenSigTimeoutMsg" BU_SG_REL_ EBCM_PHS SG_ 497 SysBkUpPwrMd 497;
BA_REL_ "GenSigTimeoutTime" BU_SG_REL_ EBCM_PHS SG_ 497 SysBkUpPwrMd 250;
BA_REL_ "GenSigSuprvResp" BU_SG_REL_ EOCM2cp_IMX6_PHS SG_ 497 SysBkUpPwrMd 1;
BA_REL_ "GenSigTimeoutMsg" BU_SG_REL_ EOCM2cp_IMX6_PHS SG_ 497 SysBkUpPwrMd 497;
BA_REL_ "GenSigTimeoutTime" BU_SG_REL_ EOCM2cp_IMX6_PHS SG_ 497 SysBkUpPwrMd 500;
BA_REL_ "GenSigSuprvResp" BU_SG_REL_ EBOOST_OBD_PHS SG_ 497 SysPwrMd 1;
BA_REL_ "GenSigTimeoutMsg" BU_SG_REL_ EBOOST_OBD_PHS SG_ 497 SysPwrMd 497;
BA_REL_ "GenSigTimeoutTime" BU_SG_REL_ EBOOST_OBD_PHS SG_ 497 SysPwrMd 500;
BA_REL_ "GenSigSuprvResp" BU_SG_REL_ EOCM2cp_K1_PHS SG_ 497 SysPwrMd 1;
BA_REL_ "GenSigTimeoutMsg" BU_SG_REL_ EOCM2cp_K1_PHS SG_ 497 SysPwrMd 497;
BA_REL_ "GenSigTimeoutTime" BU_SG_REL_ EOCM2cp_K1_PHS SG_ 497 SysPwrMd 500;
BA_REL_ "GenSigSuprvResp" BU_SG_REL_ EPSb_PHS SG_ 497 SysPwrMd 1;
BA_REL_ "GenSigTimeoutMsg" BU_SG_REL_ EPSb_PHS SG_ 497 SysPwrMd 497;
BA_REL_ "GenSigTimeoutTime" BU_SG_REL_ EPSb_PHS SG_ 497 SysPwrMd 500;
BA_REL_ "GenSigSuprvResp" BU_SG_REL_ EPSa_PHS SG_ 497 SysPwrMd 1;
BA_REL_ "GenSigTimeoutMsg" BU_SG_REL_ EPSa_PHS SG_ 497 SysPwrMd 497;
BA_REL_ "GenSigTimeoutTime" BU_SG_REL_ EPSa_PHS SG_ 497 SysPwrMd 500;
BA_REL_ "GenSigSuprvResp" BU_SG_REL_ EBCM_PHS SG_ 497 SysPwrMd 1;
BA_REL_ "GenSigTimeoutMsg" BU_SG_REL_ EBCM_PHS SG_ 497 SysPwrMd 497;
BA_REL_ "GenSigTimeoutTime" BU_SG_REL_ EBCM_PHS SG_ 497 SysPwrMd 250;
BA_REL_ "GenSigSuprvResp" BU_SG_REL_ EOCM2cp_IMX6_PHS SG_ 497 SysPwrMd 1;
BA_REL_ "GenSigTimeoutMsg" BU_SG_REL_ EOCM2cp_IMX6_PHS SG_ 497 SysPwrMd 497;
BA_REL_ "GenSigTimeoutTime" BU_SG_REL_ EOCM2cp_IMX6_PHS SG_ 497 SysPwrMd 500;
BA_REL_ "GenSigSuprvResp" BU_SG_REL_ EBCM_PHS SG_ 497 PrkBrkSwAtv 1;
BA_REL_ "GenSigTimeoutMsg" BU_SG_REL_ EBCM_PHS SG_ 497 PrkBrkSwAtv 497;
BA_REL_ "GenSigTimeoutTime" BU_SG_REL_ EBCM_PHS SG_ 497 PrkBrkSwAtv 500;
BA_REL_ "GenSigSuprvResp" BU_SG_REL_ EBCM_PHS SG_ 497 PrkBrkSwAtv 1;
BA_REL_ "GenSigTimeoutMsg" BU_SG_REL_ EBCM_PHS SG_ 497 PrkBrkSwAtv 497;
BA_REL_ "GenSigTimeoutTime" BU_SG_REL_ EBCM_PHS SG_ 497 PrkBrkSwAtv 500;
BA_REL_ "GenSigSuprvResp" BU_SG_REL_ EBCM_PHS SG_ 497 PrkBrkSwAtv 1;
BA_REL_ "GenSigTimeoutMsg" BU_SG_REL_ EBCM_PHS SG_ 497 PrkBrkSwAtv 497;
BA_REL_ "GenSigTimeoutTime" BU_SG_REL_ EBCM_PHS SG_ 497 PrkBrkSwAtv 500;
BA_REL_ "GenSigRxStartValue" BU_SG_REL_ EPSb_PHS SG_ 1233 EngOilTmpV "Valid";
BA_REL_ "GenSigRxStartValue" BU_SG_REL_ EPSa_PHS SG_ 1233 EngOilTmpV "Valid";
BA_REL_ "GenSigVBitResp" BU_SG_REL_ EPSb_PHS SG_ 1233 EngOilTmp 1;
BA_REL_ "GenSigRxStartValue" BU_SG_REL_ EPSb_PHS SG_ 1233 EngOilTmp "0";
BA_REL_ "GenSigSuprvResp" BU_SG_REL_ EPSb_PHS SG_ 1233 EngOilTmp 1;
BA_REL_ "GenSigTimeoutMsg" BU_SG_REL_ EPSb_PHS SG_ 1233 EngOilTmp 1233;
BA_REL_ "GenSigTimeoutTime" BU_SG_REL_ EPSb_PHS SG_ 1233 EngOilTmp 1250;
BA_REL_ "GenSigVBitResp" BU_SG_REL_ EPSa_PHS SG_ 1233 EngOilTmp 1;
BA_REL_ "GenSigRxStartValue" BU_SG_REL_ EPSa_PHS SG_ 1233 EngOilTmp "0";
BA_REL_ "GenSigSuprvResp" BU_SG_REL_ EPSa_PHS SG_ 1233 EngOilTmp 1;
BA_REL_ "GenSigTimeoutMsg" BU_SG_REL_ EPSa_PHS SG_ 1233 EngOilTmp 1233;
BA_REL_ "GenSigTimeoutTime" BU_SG_REL_ EPSa_PHS SG_ 1233 EngOilTmp 1250;
BA_REL_ "GenSigSuprvResp" BU_SG_REL_ EOCM2cp_K1_PHS SG_ 407 TARS_TransActRngM 1;
BA_REL_ "GenSigTimeoutMsg" BU_SG_REL_ EOCM2cp_K1_PHS SG_ 407 TARS_TransActRngM 407;
BA_REL_ "GenSigTimeoutTime" BU_SG_REL_ EOCM2cp_K1_PHS SG_ 407 TARS_TransActRngM 75;
BA_REL_ "GenSigSuprvResp" BU_SG_REL_ EOCM2cp_K1_PHS SG_ 407 TARS_TransActRngV 1;
BA_REL_ "GenSigTimeoutMsg" BU_SG_REL_ EOCM2cp_K1_PHS SG_ 407 TARS_TransActRngV 407;
BA_REL_ "GenSigTimeoutTime" BU_SG_REL_ EOCM2cp_K1_PHS SG_ 407 TARS_TransActRngV 75;
BA_REL_ "GenSigSuprvResp" BU_SG_REL_ EOCM2cp_K1_PHS SG_ 407 TARS_TransActRng 1;
BA_REL_ "GenSigTimeoutMsg" BU_SG_REL_ EOCM2cp_K1_PHS SG_ 407 TARS_TransActRng 407;
BA_REL_ "GenSigTimeoutTime" BU_SG_REL_ EOCM2cp_K1_PHS SG_ 407 TARS_TransActRng 75;
BA_REL_ "GenSigSuprvResp" BU_SG_REL_ EOCM2cp_K1_PHS SG_ 407 TEPI_TrnsEngdPrFlwStV 1;
BA_REL_ "GenSigTimeoutMsg" BU_SG_REL_ EOCM2cp_K1_PHS SG_ 407 TEPI_TrnsEngdPrFlwStV 407;
BA_REL_ "GenSigTimeoutTime" BU_SG_REL_ EOCM2cp_K1_PHS SG_ 407 TEPI_TrnsEngdPrFlwStV 75;
BA_REL_ "GenSigSuprvResp" BU_SG_REL_ EOCM2cp_K1_PHS SG_ 407 TEPI_TrnsEngdPrFlwSt 1;
BA_REL_ "GenSigTimeoutMsg" BU_SG_REL_ EOCM2cp_K1_PHS SG_ 407 TEPI_TrnsEngdPrFlwSt 407;
BA_REL_ "GenSigTimeoutTime" BU_SG_REL_ EOCM2cp_K1_PHS SG_ 407 TEPI_TrnsEngdPrFlwSt 75;
BA_REL_ "GenSigSuprvResp" BU_SG_REL_ EOCM2cp_K1_PHS SG_ 407 TransRatio 1;
BA_REL_ "GenSigTimeoutMsg" BU_SG_REL_ EOCM2cp_K1_PHS SG_ 407 TransRatio 407;
BA_REL_ "GenSigTimeoutTime" BU_SG_REL_ EOCM2cp_K1_PHS SG_ 407 TransRatio 75;
BA_REL_ "GenSigSuprvResp" BU_SG_REL_ EOCM2cp_K1_PHS SG_ 407 TrnsOvrallActTorqRatio 1;
BA_REL_ "GenSigTimeoutMsg" BU_SG_REL_ EOCM2cp_K1_PHS SG_ 407 TrnsOvrallActTorqRatio 407;
BA_REL_ "GenSigTimeoutTime" BU_SG_REL_ EOCM2cp_K1_PHS SG_ 407 TrnsOvrallActTorqRatio 75;
VAL_ 274 RedADIMCntrlFailed 1 "true" 0 "false" ;
VAL_ 274 RedExtVehCtrlSts 3 "Invalid" 2 "Active" 1 "Authenticate" 0 "Intialize" ;
VAL_ 274 RedVehMdMngrSt 0 "Unknown" 1 "Manual" 2 "Autonomous Supervised" 3 "Supervisor Override" 4 "Autonomous Unsupervised" 5 "Failed" ;
VAL_ 274 RedAutoEPBReq 2 "Request Release" 1 "Request Apply" 0 "No Request" ;
VAL_ 274 RedAutoBrkReqType 2 "Standstill Hold Request" 1 "Brake Torque Request" 0 "No Request" 3 "Brake Prefill" ;
VAL_ 274 RedAutoBrkSysRdcPerDet 1 "true" 0 "false" ;
VAL_ 1931 DTCI_CodeSupported_78B 1 "true" 0 "false" ;
VAL_ 1931 DTCI_CurrentStatus_78B 1 "true" 0 "false" ;
VAL_ 1931 DTCI_DTCFaultType_78B 3 "Type C" 2 "Type B" 1 "Type A" 0 "Not Supported" ;
VAL_ 1931 DTCI_DTCTriggered_78B 1 "true" 0 "false" ;
VAL_ 1931 DTCI_HistStat_78B 1 "true" 0 "false" ;
VAL_ 1931 DTCI_TstFldCdClrdStat_78B 1 "true" 0 "false" ;
VAL_ 1931 DTCI_TstFldPwrUpSt_78B 1 "true" 0 "false" ;
VAL_ 1931 DTCI_TstNPsdCdClrdSt_78B 1 "true" 0 "false" ;
VAL_ 1931 DTCI_TstNPsdPwrUpSt_78B 1 "true" 0 "false" ;
VAL_ 1931 DTCIUnused1_78B 1 "true" 0 "false" ;
VAL_ 1931 DTCIUnused2_78B 1 "true" 0 "false" ;
VAL_ 1931 DTCIUnused3_78B 1 "true" 0 "false" ;
VAL_ 1931 DTCIUnused4_78B 1 "true" 0 "false" ;
VAL_ 1931 DTCIUnused5_78B 1 "true" 0 "false" ;
VAL_ 1931 DTCIUnused6_78B 1 "true" 0 "false" ;
VAL_ 1931 DTCIUnused7_78B 1 "true" 0 "false" ;
VAL_ 1931 DTCI_WrnIndRqdSt_78B 1 "true" 0 "false" ;
VAL_ 979 RegVltCtlEngyRcvryAct 1 "true" 0 "false" ;
VAL_ 979 SpdLmtrSttngTypAct 3 "Reserved" 2 "Auto" 1 "Manual" 0 "Off" ;
VAL_ 979 SetSpdLmtRchd 3 "Reserved" 2 "Low limit reached" 1 "High limit reached" 0 "No limit reached" ;
VAL_ 979 ElvtdIdlCstCrStVal 0 "No Action" 1 "Off" 2 "On" ;
VAL_ 979 ElvtdIdlCstStAvl 1 "true" 0 "false" ;
VAL_ 979 PTABR_PTBrkRqAct 1 "true" 0 "false" ;
VAL_ 979 BrkBstVacV 1 "Invalid" 0 "Valid" ;
VAL_ 979 EngManfldAirTempCrtdV 1 "Invalid" 0 "Valid" ;
VAL_ 979 PltfrmEngSpdCmmndSt 3 "Request Denied" 2 "Lost Arbitration" 1 "Request Honored" 0 "No Request" ;
VAL_ 562 BrkSysAutBrkStat 0 "Not active" 1 "Active" 2 "Limited" 3 "Failed" ;
VAL_ 562 FSRACCBrkngReqDenied 1 "true" 0 "false" ;
VAL_ 562 BrkSysExtHldCpbltyFld 1 "true" 0 "false" ;
VAL_ 562 SndPerfMdCsStAvl 1 "true" 0 "false" ;
VAL_ 562 SndPerfMdCsCrStVal 0 "No Action" 1 "Performance Mode 1" 2 "Performance Mode 2" 3 "Performance Mode 3" 4 "Performance Mode 4" 5 "Performance Mode 5" 6 "Performance Mode 6" 7 "Auto" ;
VAL_ 562 DispPerfMdCsStAvl 1 "true" 0 "false" ;
VAL_ 562 DispPerfMdCsCrStVal 0 "No Action" 1 "Performance Mode 1" 2 "Performance Mode 2" 3 "Performance Mode 3" 4 "Performance Mode 4" 5 "Performance Mode 5" 6 "Performance Mode 6" 7 "Auto" ;
VAL_ 562 DrvlneMntsPerfMdRq 0 "No Action" 1 "Performance Mode 1" 2 "Performance Mode 2" 3 "Performance Mode 3" 4 "Performance Mode 4" 5 "Performance Mode 5" 6 "Performance Mode 6" 7 "Performance Mode 7" ;
VAL_ 562 RideCntrlPerfMdRq 7 "Performance Mode 7" 6 "Performance Mode 6" 5 "Performance Mode 5" 4 "Performance Mode 4" 3 "Performance Mode 3" 2 "Performance Mode 2" 1 "Performance Mode 1" 0 "No Action" ;
VAL_ 562 StgSysPerfMdRq 7 "Performance Mode 7" 6 "Performance Mode 6" 5 "Performance Mode 5" 4 "Performance Mode 4" 3 "Performance Mode 3" 2 "Performance Mode 2" 1 "Performance Mode 1" 0 "No Action" ;
VAL_ 562 DiffPerfMdRq 7 "Performance Mode 7" 6 "Performance Mode 6" 5 "Performance Mode 5" 4 "Performance Mode 4" 3 "Performance Mode 3" 2 "Performance Mode 2" 1 "Performance Mode 1" 0 "No Action" ;
VAL_ 562 SndEnhcmtPerfMdRq 7 "Performance Mode 7" 6 "Performance Mode 6" 5 "Performance Mode 5" 4 "Performance Mode 4" 3 "Performance Mode 3" 2 "Performance Mode 2" 1 "Performance Mode 1" 0 "No Action" ;
VAL_ 562 DsplyPerfMdRq 7 "Performance Mode 7" 6 "Performance Mode 6" 5 "Performance Mode 5" 4 "Performance Mode 4" 3 "Performance Mode 3" 2 "Performance Mode 2" 1 "Performance Mode 1" 0 "No Action" ;
VAL_ 562 ExhstPerfMdRq 7 "Performance Mode 7" 6 "Performance Mode 6" 5 "Performance Mode 5" 4 "Performance Mode 4" 3 "Performance Mode 3" 2 "Performance Mode 2" 1 "Performance Mode 1" 0 "No Action" ;
VAL_ 562 HillDscntCntlSysStat 4 "Temporarily Inhibited" 3 "Failed" 2 "Active" 1 "Enabled" 0 "Normal" ;
VAL_ 562 SusCustStngAvlbl 1 "true" 0 "false" ;
VAL_ 562 SusCustCurrStngVal 7 "Auto" 6 "Performance Mode 6" 5 "Performance Mode 5" 4 "Performance Mode 4" 3 "Performance Mode 3" 0 "No Action" 1 "Performance Mode 1" 2 "Performance Mode 2" ;
VAL_ 562 StrCustStngAvlbl 1 "true" 0 "false" ;
VAL_ 562 StrCustCurrStngVal 7 "Auto" 6 "Performance Mode 6" 5 "Performance Mode 5" 4 "Performance Mode 4" 3 "Performance Mode 3" 0 "No Action" 1 "Performance Mode 1" 2 "Performance Mode 2" ;
VAL_ 562 DrvlnCustStngAvlbl 1 "true" 0 "false" ;
VAL_ 562 AWDPerfMdRq 7 "Performance Mode 7" 6 "Performance Mode 6" 5 "Performance Mode 5" 4 "Performance Mode 4" 3 "Performance Mode 3" 2 "Performance Mode 2" 1 "Performance Mode 1" 0 "No Action" ;
VAL_ 562 DrvlnCustCurrStngVal 7 "Auto" 6 "Performance Mode 6" 5 "Performance Mode 5" 4 "Performance Mode 4" 3 "Performance Mode 3" 0 "No Action" 1 "Performance Mode 1" 2 "Performance Mode 2" ;
VAL_ 608 AutoPwrSelfTestStat 3 "Complete" 2 "Active" 1 "Pending" 0 "Inactive" ;
VAL_ 608 AutoPwrSOH 3 "Faulted" 2 "Supervision Mode" 1 "Inactive" 0 "Indeterminate" ;
VAL_ 608 AutoPwrDrtgLvl 5 " Derating Level 5" 4 " Derating Level 4" 3 " Derating Level 3" 2 " Derating Level 2" 1 " Derating Level 1" 0 " Derating Level 0" ;
VAL_ 608 AutoPwrLdShdRq 4 "Load Shed Level 4" 3 "Load Shed Level 3" 2 "Load Shed Level 2" 1 "Load Shed Level 1" 0 "No Load Shedding" ;
VAL_ 608 AutoVltOvrdAct 1 "true" 0 "false" ;
VAL_ 1001 DistRollCntAvgDrvnSrc 1 "Wheel Speed" 0 "Transmission Output Speed" ;
VAL_ 1001 VehSpdAvgDrvnSrc 1 "Wheel Speed" 0 "Transmission Output Speed" ;
VAL_ 1001 DstRolCntAvgNonDrvnV 1 "Invalid" 0 "Valid" ;
VAL_ 1001 DstRolCntAvNDrRstOc 1 "true" 0 "false" ;
VAL_ 1001 DistRollCntAvgDrvnV 1 "Invalid" 0 "Valid" ;
VAL_ 1001 DstRolCntAvgDrnRstOc 1 "true" 0 "false" ;
VAL_ 1001 VehSpdAvgNDrvnV 1 "Invalid" 0 "Valid" ;
VAL_ 1001 VehSpdAvgDrvnV 1 "Invalid" 0 "Valid" ;
VAL_ 1009 RstrctdPTOpModeReqd 1 "true" 0 "false" ;
VAL_ 1009 ClmtCtrlHtrEngRunRq 1 "Engine Run Requested" 0 "No Action" ;
VAL_ 1009 OtsAirTmpCrValMsk 1 "Use Data" 0 "Don't Use Data" ;
VAL_ 1009 ACCmEngRunReq 1 "Engine Run Requested" 0 "No Action" ;
VAL_ 1009 OutAirTempVDA 1 "VirtualDeviceAvailable" 0 "VirtualDeviceUnavailable" ;
VAL_ 1009 OtsAirTmpCrValV 1 "Invalid" 0 "Valid" ;
VAL_ 1009 EngOffTmVDA 1 "VirtualDeviceAvailable" 0 "VirtualDeviceUnavailable" ;
VAL_ 1009 ClntCircPmpRq 1 "On" 0 "Off" ;
VAL_ 1009 EngOffTmExtRngV 1 "Invalid" 0 "Valid" ;
VAL_ 1009 PF_MinIdlBstLvlReq 3 "Boost Level 3" 2 "Boost Level 2" 1 "Boost Level 1" 0 "No Boost Requested" ;
VAL_ 201 Eng12vStrtrMtrCmmdOn 1 "true" 0 "false" ;
VAL_ 201 EngCntrlRunCrnkTrmSt 1 "Active" 0 "Inactive" ;
VAL_ 201 EngAirIntBstPrV 1 "Invalid" 0 "Valid" ;
VAL_ 201 SpdLmtrSpdWrngEnbld 1 "true" 0 "false" ;
VAL_ 201 EngCylDactEvntPndg 1 "true" 0 "false" ;
VAL_ 201 EngCylDeactMd 3 "Reactivation In Progress" 2 "Half of Total Cylinders Active" 1 "Deactivation In Progress" 0 "All Cylinders Active" ;
VAL_ 201 RmVhStrtEngRng 1 "true" 0 "false" ;
VAL_ 201 PFEngSpdCmndSpcd 1 "true" 0 "false" ;
VAL_ 201 PltfrmEngSpdCmdInhtRq 0 "Allow Platform Engine Speed Control" 1 "Inhibit Platform Eng. Speed Control" ;
VAL_ 201 PT_BrkPedDscrtInpStatV 1 "Invalid" 0 "Valid" ;
VAL_ 201 PT_BrkPedDscrtInpStat 1 "Brake Applied" 0 "Brake Not Applied" ;
VAL_ 201 CrsCntEnbld 1 "true" 0 "false" ;
VAL_ 201 CrsCntAtv 1 "true" 0 "false" ;
VAL_ 201 DrvThrottlOvrrdDet 1 "true" 0 "false" ;
VAL_ 201 PT_CrnkAct 1 "true" 0 "false" ;
VAL_ 201 PTRunAbrt 1 "true" 0 "false" ;
VAL_ 201 PTO_PT_RunAbrtd 1 "true" 0 "false" ;
VAL_ 201 PTCrnkAbrted 1 "true" 0 "false" ;
VAL_ 201 EngSpdStat 3 "Invalid" 1 "Degraded Operation" 0 "Normal Operation" ;
VAL_ 201 EngRunAtv 1 "true" 0 "false" ;
VAL_ 201 EngIdlAtv 1 "true" 0 "false" ;
VAL_ 201 AccActPosV 1 "Invalid" 0 "Valid" ;
VAL_ 842 WhlRotDrctnlSRtNDrvn 0 "Unknown" 1 "Forward" 2 "Reverse" 3 "Not Supported" 4 "Failed" 5 "Reserved 1" 6 "Reserved 2" 7 "Reserved 3" ;
VAL_ 842 WhlRotDrctnlStLfNDrvn 0 "Unknown" 1 "Forward" 2 "Reverse" 3 "Not Supported" 4 "Failed" 5 "Reserved 1" 6 "Reserved 2" 7 "Reserved 3" ;
VAL_ 842 WhlGrndVlctyRtNnDrvnV 1 "Invalid" 0 "Valid" ;
VAL_ 842 WhlGrndVlctyLftNnDrvnV 1 "Invalid" 0 "Valid" ;
VAL_ 840 WhlRotDrctnlStLftDrvn 0 "Unknown" 1 "Forward" 2 "Reverse" 3 "Not Supported" 4 "Failed" 5 "Reserved 1" 6 "Reserved 2" 7 "Reserved 3" ;
VAL_ 840 WhlRotDrctnlStRtDrvn 0 "Unknown" 1 "Forward" 2 "Reverse" 3 "Not Supported" 4 "Failed" 5 "Reserved 1" 6 "Reserved 2" 7 "Reserved 3" ;
VAL_ 840 WhlGrndVlctyRtDrvnV 1 "Invalid" 0 "Valid" ;
VAL_ 840 WhlGrndVlctyLftDrvnV 1 "Invalid" 0 "Valid" ;
VAL_ 1912 DTCI_DTCFaultType_778 3 "Type C" 2 "Type B" 1 "Type A" 0 "Not Supported" ;
VAL_ 1912 DTCI_CodeSupported_778 1 "true" 0 "false" ;
VAL_ 1912 DTCI_CurrentStatus_778 1 "true" 0 "false" ;
VAL_ 1912 DTCI_TstNPsdCdClrdSt_778 1 "true" 0 "false" ;
VAL_ 1912 DTCI_TstFldCdClrdStat_778 1 "true" 0 "false" ;
VAL_ 1912 DTCI_HistStat_778 1 "true" 0 "false" ;
VAL_ 1912 DTCI_TstNPsdPwrUpSt_778 1 "true" 0 "false" ;
VAL_ 1912 DTCI_TstFldPwrUpSt_778 1 "true" 0 "false" ;
VAL_ 1912 DTCI_WrnIndRqdSt_778 1 "true" 0 "false" ;
VAL_ 1912 DTCI_DTCTriggered_778 1 "true" 0 "false" ;
VAL_ 1912 DTCIUnused7_778 1 "true" 0 "false" ;
VAL_ 1912 DTCIUnused6_778 1 "true" 0 "false" ;
VAL_ 1912 DTCIUnused5_778 1 "true" 0 "false" ;
VAL_ 1912 DTCIUnused4_778 1 "true" 0 "false" ;
VAL_ 1912 DTCIUnused3_778 1 "true" 0 "false" ;
VAL_ 1912 DTCIUnused2_778 1 "true" 0 "false" ;
VAL_ 1912 DTCIUnused1_778 1 "true" 0 "false" ;
VAL_ 497 ElvtdIdlCstStReq 0 "No Action" 1 "Off" 2 "On" ;
VAL_ 497 FuelFltLfRstRqd 1 "true" 0 "false" ;
VAL_ 497 ACCompSysVDA 1 "VirtualDeviceAvailable" 0 "VirtualDeviceUnavailable" ;
VAL_ 497 BkupPwrModeMstrVDA 1 "VirtualDeviceAvailable" 0 "VirtualDeviceUnavailable" ;
VAL_ 497 PrkBrkVDA 1 "VirtualDeviceAvailable" 0 "VirtualDeviceUnavailable" ;
VAL_ 497 PrkBrkVDM 1 "Use Data" 0 "Don't Use Data" ;
VAL_ 497 BkupPwrModeMstrVDM 1 "Use Data" 0 "Don't Use Data" ;
VAL_ 497 ACCompSysVDM 1 "Use Data" 0 "Don't Use Data" ;
VAL_ 497 AirbgVDA 1 "VirtualDeviceAvailable" 0 "VirtualDeviceUnavailable" ;
VAL_ 497 SysBkupPwrMdEn 1 "true" 0 "false" ;
VAL_ 497 SysBkUpPwrMd 3 "Crank Request" 2 "Run" 1 "Accessory" 0 "Off" ;
VAL_ 497 SysPwrMd 3 "Crank Request" 2 "Run" 1 "Accessory" 0 "Off" ;
VAL_ 497 TrStLgMdAtv 1 "true" 0 "false" ;
VAL_ 497 DispMeasSys 1 "English" 0 "Metric" ;
VAL_ 497 ACCmpsrFldOn 1 "true" 0 "false" ;
VAL_ 497 ACCompModReq 3 "No Action" 2 "Engage" 1 "Disengage" 0 "Disengage Immediately" ;
VAL_ 497 ACCompNormLdV 1 "Invalid" 0 "Valid" ;
VAL_ 497 PTORSMstrEngShtReq 1 "true" 0 "false" ;
VAL_ 497 EngOilLfRstRq 1 "true" 0 "false" ;
VAL_ 497 SIRDpl 1 "true" 0 "false" ;
VAL_ 497 PTORmStMsEngStRq 1 "PTO Remote Start Requested" 0 "PTO Remote Start Not Requested" ;
VAL_ 497 RmVehStrRq 1 "Remote Start Requested" 0 "Remote Start Not Requested" ;
VAL_ 497 ThrtlPrgrsnReq 2 "Map C" 1 "Map B" 0 "Map A" ;
VAL_ 497 PrkBrkSwAtv 1 "true" 0 "false" ;
VAL_ 497 PMMAccTrmSt 1 "Active" 0 "Inactive" ;
VAL_ 497 PMMRunCrkTrmSt 1 "Active" 0 "Inactive" ;
VAL_ 497 ImmblzrPreRelPswdStat 1 "Information Valid" 0 "No Information" ;
VAL_ 1908 DTCI_DTCFaultType_774 3 "Type C" 2 "Type B" 1 "Type A" 0 "Not Supported" ;
VAL_ 1908 DTCI_CodeSupported_774 1 "true" 0 "false" ;
VAL_ 1908 DTCI_CurrentStatus_774 1 "true" 0 "false" ;
VAL_ 1908 DTCI_TstNPsdCdClrdSt_774 1 "true" 0 "false" ;
VAL_ 1908 DTCI_TstFldCdClrdStat_774 1 "true" 0 "false" ;
VAL_ 1908 DTCI_HistStat_774 1 "true" 0 "false" ;
VAL_ 1908 DTCI_TstNPsdPwrUpSt_774 1 "true" 0 "false" ;
VAL_ 1908 DTCI_TstFldPwrUpSt_774 1 "true" 0 "false" ;
VAL_ 1908 DTCI_WrnIndRqdSt_774 1 "true" 0 "false" ;
VAL_ 1908 DTCI_DTCTriggered_774 1 "true" 0 "false" ;
VAL_ 1908 DTCIUnused7_774 1 "true" 0 "false" ;
VAL_ 1908 DTCIUnused6_774 1 "true" 0 "false" ;
VAL_ 1908 DTCIUnused5_774 1 "true" 0 "false" ;
VAL_ 1908 DTCIUnused4_774 1 "true" 0 "false" ;
VAL_ 1908 DTCIUnused3_774 1 "true" 0 "false" ;
VAL_ 1908 DTCIUnused2_774 1 "true" 0 "false" ;
VAL_ 1908 DTCIUnused1_774 1 "true" 0 "false" ;
VAL_ 1233 PTExPrtclFltWrng3IO 1 "true" 0 "false" ;
VAL_ 1233 PTExPartFltManRegStat 7 "Reserved 3" 6 "Reserved 2" 5 "Reserved 1" 4 "Complete" 3 "In Progress" 2 "Not Allowed" 1 "Allowed" 0 "Cleaning Not Required" ;
VAL_ 1233 a_12VBatSysUnstab 1 "true" 0 "false" ;
VAL_ 1233 EngShtdwnAct 1 "true" 0 "false" ;
VAL_ 1233 EngShtdwnPndgIO 1 "true" 0 "false" ;
VAL_ 1233 FuelFltChgNwIO 1 "true" 0 "false" ;
VAL_ 1233 PTExPrtclFltrWrn2IO 1 "true" 0 "false" ;
VAL_ 1233 PTHiElecLdReqd 1 "true" 0 "false" ;
VAL_ 1233 PTExPrtclFltrWrnIO 1 "true" 0 "false" ;
VAL_ 1233 AirCndOffIO 1 "true" 0 "false" ;
VAL_ 1233 DslGlwPlgIO 1 "true" 0 "false" ;
VAL_ 1233 RdcdPwrIO 1 "true" 0 "false" ;
VAL_ 1233 FlLvlPctV 1 "Invalid" 0 "Valid" ;
VAL_ 1233 EngWtrInFlIO 1 "true" 0 "false" ;
VAL_ 1233 EngOilTmpV 1 "Invalid" 0 "Valid" ;
VAL_ 1233 EngOilPrsV 1 "Invalid" 0 "Valid" ;
VAL_ 1233 EngOilPrsLwIO 1 "true" 0 "false" ;
VAL_ 1233 EngOilLvlLwIO 1 "true" 0 "false" ;
VAL_ 1233 EngOilChngIO 1 "true" 0 "false" ;
VAL_ 1233 EngHt_StpEngIO 1 "true" 0 "false" ;
VAL_ 1233 EngHotFuelEnrchmntIO 1 "true" 0 "false" ;
VAL_ 1233 CkFlFilrCapIO 1 "true" 0 "false" ;
VAL_ 382 BrkSysBrkLtsReqdRed 1 "true" 0 "false" ;
VAL_ 508 CSTBATS_TrqVlV 1 "Invalid" 0 "Valid" ;
VAL_ 407 TARS_TransActRngM 1 "Use Data" 0 "Don't Use Data" ;
VAL_ 407 TARS_TransActRngV 1 "Invalid" 0 "Valid" ;
VAL_ 407 TARS_TransActRng 15 "Unused and Reserved2" 14 "Unused and Reserved1" 13 "Fourth Drive Position" 12 "Between Third and Fourth Drive position" 11 "Third Drive Position" 10 "Between Second and Third Drive position" 9 "Second Drive Position" 8 "Between First and Second Drive position" 7 "First Drive Position" 6 "Between Neutral and First Drive position" 5 "Neutral Position" 4 "Between Reverse and Neutral" 3 "Reverse Position" 2 "Between Park and Reverse" 1 "Park Position" 0 "Unknown Position" ;
VAL_ 407 TEPI_TrnsEngdPrFlwStV 1 "Invalid" 0 "Valid" ;
VAL_ 407 TEPI_TrnsEngdPrFlwSt 7 "Unused and Reserved4" 6 "Unused and Reserved3" 5 "Unused and Reserved2" 4 "Unused and Reserved1" 3 "Reverse Engaged" 2 "Drive Engaged" 1 "No Powerflow" 0 "Unavailable " ;
VAL_ 407 TransRatioV 1 "Invalid" 0 "Valid" ;
VAL_ 407 TrnsOvrallActTorqRatioV 1 "Invalid" 0 "Valid" ;
SIG_GROUP_ 1931 DTCInfo_78B 1 : DTCI_CodeSupported_78B DTCI_CurrentStatus_78B DTCI_DTCFailType_78B DTCI_DTCFaultType_78B DTCI_DTCNumber_78B DTCI_DTCSource_78B DTCI_DTCTriggered_78B DTCI_HistStat_78B DTCI_TstFldCdClrdStat_78B DTCI_TstFldPwrUpSt_78B DTCI_TstNPsdCdClrdSt_78B DTCI_TstNPsdPwrUpSt_78B DTCIUnused1_78B DTCIUnused2_78B DTCIUnused3_78B DTCIUnused4_78B DTCIUnused5_78B DTCIUnused6_78B DTCIUnused7_78B DTCI_WrnIndRqdSt_78B;
SIG_GROUP_ 979 PTAutoBrkReq 1 : PTABR_AccReq PTABR_PTBrkRqAct;
SIG_GROUP_ 1912 DTCInfo_778 1 : DTCI_DTCFaultType_778 DTCI_CodeSupported_778 DTCI_CurrentStatus_778 DTCI_TstNPsdCdClrdSt_778 DTCI_TstFldCdClrdStat_778 DTCI_HistStat_778 DTCI_TstNPsdPwrUpSt_778 DTCI_TstFldPwrUpSt_778 DTCI_WrnIndRqdSt_778 DTCI_DTCFailType_778 DTCI_DTCNumber_778 DTCI_DTCSource_778 DTCI_DTCTriggered_778 DTCIUnused7_778 DTCIUnused6_778 DTCIUnused5_778 DTCIUnused4_778 DTCIUnused3_778 DTCIUnused2_778 DTCIUnused1_778;
SIG_GROUP_ 1908 DTCInfo_774 1 : DTCI_DTCFaultType_774 DTCI_CodeSupported_774 DTCI_CurrentStatus_774 DTCI_TstNPsdCdClrdSt_774 DTCI_TstFldCdClrdStat_774 DTCI_HistStat_774 DTCI_TstNPsdPwrUpSt_774 DTCI_TstFldPwrUpSt_774 DTCI_WrnIndRqdSt_774 DTCI_DTCFailType_774 DTCI_DTCNumber_774 DTCI_DTCSource_774 DTCI_DTCTriggered_774 DTCIUnused7_774 DTCIUnused6_774 DTCIUnused5_774 DTCIUnused4_774 DTCIUnused3_774 DTCIUnused2_774 DTCIUnused1_774;
SIG_GROUP_ 508 ChsSysTtlBrkAxleTrqSt 1 : CSTBATS_TrqVl CSTBATS_TrqVlV;
SIG_GROUP_ 407 TransActlRngSt 1 : TARS_TransActRngM TARS_TransActRngV TARS_TransActRng;
SIG_GROUP_ 407 TransEngdPrFlwInfo 1 : TEPI_TrnsEngdPrFlwStV TEPI_TrnsEngdPrFlwSt;
